VERSION ""

NS_ :

BS_:

BU_: ABS_BASE ATCM_DMSM GENERIC_GWMWakeup PBM IPMB TCU_TBS FDSM GSM TRCM GWM _delete ABS_ESC HUD IPMA CCM SASM PSCM SCCM HCM ATCM SUMA_RLM ATCM_FFSM PCU SECM VDM TBM OCS GENERIC TCCM TSTR RCM

BO_ 1073 BodyEngGateway_2_HS2: 8 GWM
 SG_ CamraFrntBttn_D_Stat : 48|1@0+ (1,0) [0|1] "SED"  IPMB
 SG_ CamraFrntBttn_D_Stat_UB : 60|1@0+ (1,0) [0|1] "SED"  IPMB
 SG_ BrkDrvMde_D_Rq_UB : 49|1@0+ (1,0) [0|1] "SED"  ABS_BASE,ABS_ESC,CCM
 SG_ BrkDrvMde_D_Rq : 63|3@0+ (1,0) [0|7] "SED"  ABS_BASE,ABS_ESC,CCM
 SG_ SteEffort_D_Rq : 52|3@0+ (1,0) [0|7] "SED"  PSCM
 SG_ SteEffort_D_Rq_UB : 40|1@0+ (1,0) [0|1] "SED"  PSCM
 SG_ AutoHoldSwtch_D_Stat_UB : 57|1@0+ (1,0) [0|1] "SED"  ABS_BASE,ABS_ESC
 SG_ AutoHoldSwtch_D_Stat : 59|2@0+ (1,0) [0|3] "SED"  ABS_BASE,ABS_ESC
 SG_ HMI_HMIMode_St_UB : 41|1@0+ (1,0) [0|1] "SED"  SASM,SCCM
 SG_ HMI_HMIMode_St : 55|3@0+ (1,0) [0|7] "SED"  SASM,SCCM
 SG_ Veh_Lock_Requestor_UB : 47|1@0+ (1,0) [0|1] "SED"  TCU_TBS,GSM
 SG_ Veh_Lock_EvNum_UB : 32|1@0+ (1,0) [0|1] "SED"  HUD,TCU_TBS,GSM
 SG_ Veh_Lock_Sub_Id_UB : 33|1@0+ (1,0) [0|1] "SED"  TCU_TBS
 SG_ Tire_Press_System_Stat_UB : 34|1@0+ (1,0) [0|1] "SED"  TCU_TBS
 SG_ Veh_Lock_Status_UB : 8|1@0+ (1,0) [0|1] "SED"  GSM,TCU_TBS
 SG_ Veh_Lock_Sub_Id : 19|4@0+ (1,0) [0|15] "SED"  TCU_TBS
 SG_ Veh_Lock_Status : 10|2@0+ (1,0) [0|3] "SED"  GSM,TCU_TBS
 SG_ Veh_Lock_Requestor : 39|5@0+ (1,0) [0|31] "SED"  TCU_TBS,GSM
 SG_ Veh_Lock_EvNum : 31|8@0+ (1,0) [0|255] "unitless"  HUD,TCU_TBS,GSM
 SG_ Tire_Press_System_Stat : 23|4@0+ (1,0) [0|15] "SED"  TCU_TBS
 SG_ DISPLAY_SPEED_OFFSET_UB : 0|1@0+ (1,0) [0|1] "SED"  IPMA
 SG_ DISPLAY_SPEED_OFFSET : 3|3@0+ (0.5,0) [0|3.5] "kph"  IPMA
 SG_ DISPLAY_SPEED_SCALING_UB : 11|1@0+ (1,0) [0|1] "SED"  IPMA
 SG_ DISPLAY_SPEED_SCALING : 15|4@0+ (0.5,100) [100|107.5] "%"  IPMA
 SG_ Foh_D_Stat : 7|3@0+ (1,0) [0|7] "SED"  SASM,SCCM
 SG_ Foh_D_Stat_UB : 4|1@0+ (1,0) [0|1] "SED"  SASM,SCCM
 SG_ SteWhlHeat_D_Rq_UB : 42|1@0+ (1,0) [0|1] "SED"  SCCM,SASM
 SG_ SteWhlHeat_D_Rq : 46|4@0+ (1,0) [0|15] "SED"  SCCM,SASM

BO_ 1092 TrackingBlocking_Data: 8 TCU_TBS
 SG_ TbsLamp_D_RqDsply : 7|2@0+ (1,0) [0|3] "SED"  GWM

BO_ 1876 TesterPhysicalReqTCU_TBS: 8 TSTR
 SG_ TesterPhysicalReqTCU : 7|64@0+ (1,0) [0|1.84467E+019] "unitless"  TCU_TBS

BO_ 1884 TesterPhysicalResTCU_TBS: 8 TCU_TBS
 SG_ TesterPhysicalResTCU : 7|64@0+ (1,0) [0|1.84467E+019] "unitless"  TSTR

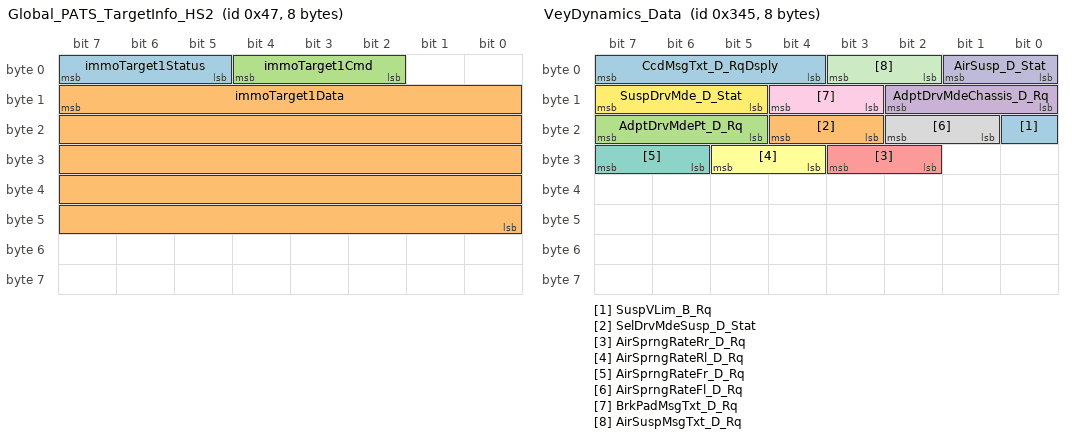
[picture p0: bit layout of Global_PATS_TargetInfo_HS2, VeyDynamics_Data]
BO_ 71 Global_PATS_TargetInfo_HS2: 8 GWM
 SG_ immoTarget1Status : 7|3@0+ (1,0) [0|7] "SED"  ABS_BASE,TCU_TBS,ABS_ESC
 SG_ immoTarget1Data : 15|40@0+ (1,0) [0|1099511627775] "Encrypted"  ABS_BASE,TCU_TBS,ABS_ESC
 SG_ immoTarget1Cmd : 4|3@0+ (1,0) [0|7] "SED"  ABS_BASE,TCU_TBS,ABS_ESC

BO_ 973 Traffic_RecognitionData: 8 IPMA
 SG_ TsrVl2PrmntMsgTxt_D_Rq : 60|2@0+ (1,0) [0|3] "SED"  GWM
 SG_ TsrVl1PrmntMsgTxt_D_Rq : 41|2@0+ (1,0) [0|3] "SED"  GWM
 SG_ TsrVl2RstrcMsgTxt2_D_Rq : 63|3@0+ (1,0) [0|7] "SED"  GWM
 SG_ TsrVl1RstrcMsgTxt2_D_Rq : 51|3@0+ (1,0) [0|7] "SED"  GWM
 SG_ TsrOvtkMsgTxt2_D_Rq : 55|4@0+ (1,0) [0|15] "SED"  GWM
 SG_ WwaWarn_B_Rq : 48|1@0+ (1,0) [0|1] "SED"  GWM
 SG_ TsrVlUnitMsgTxt_D_Rq : 43|2@0+ (1,0) [0|3] "SED"  GWM
 SG_ TsrVLim2MsgTxt_D_Rq : 39|8@0+ (1,0) [0|255] "SED"  GWM
 SG_ TsrVLim1MsgTxt_D_Rq : 31|8@0+ (1,0) [0|255] "SED"  GWM
 SG_ TsrVl2TypeMsgTxt_D_Rq : 45|2@0+ (1,0) [0|3] "SED"  GWM
 SG_ TsrVl2StatMsgTxt_D_Rq : 47|2@0+ (1,0) [0|3] "SED"  GWM
 SG_ TsrVl2RstrcMsgTxt_D_Rq : 17|2@0+ (1,0) [0|3] "SED"  GWM
 SG_ TsrVl1TypeMsgTxt_D_Rq : 19|2@0+ (1,0) [0|3] "SED"  GWM
 SG_ TsrVl1StatMsgTxt_D_Rq : 21|2@0+ (1,0) [0|3] "SED"  GWM
 SG_ TsrVl1RstrcMsgTxt_D_Rq : 23|2@0+ (1,0) [0|3] "SED"  GWM
 SG_ TsrStatMsgTxt_D_Rq : 10|3@0+ (1,0) [0|7] "SED"  GWM
 SG_ TsrOvtkTypeMsgTxt_D_Rq : 12|2@0+ (1,0) [0|3] "SED"  GWM
 SG_ TsrOvtkStatMsgTxt_D_Rq : 1|2@0+ (1,0) [0|3] "SED"  GWM
 SG_ TsrOvtkMsgTxt_D_Rq : 15|3@0+ (1,0) [0|7] "SED"  GWM
 SG_ TsrOswWarnMsgTxt_D_Rq : 3|2@0+ (1,0) [0|3] "SED"  GWM
 SG_ TsrMsgTxt_D_Rq : 7|4@0+ (1,0) [0|15] "SED"  GWM

BO_ 825 Front_Distance_Req: 8 FDSM
 SG_ WndwFrontHeat_B_Rq : 43|1@0+ (1,0) [0|1] "SED"  GWM
 SG_ FdsmTrgRight_B_Actl : 5|1@0+ (1,0) [0|1] "SED"  CCM
 SG_ FdsmTrgLeft_B_Actl : 6|1@0+ (1,0) [0|1] "SED"  CCM
 SG_ FdsmTrgDist_L_Actl : 1|10@0+ (0.0156,0) [0|15.9588] "meter"  CCM
 SG_ FdsmTrgCntr_B_Actl : 7|1@0+ (1,0) [0|1] "SED"  CCM
 SG_ LscmbbSrvcRqd_B_Rq : 44|1@0+ (1,0) [0|1] "SED"  GWM
 SG_ LscmbbPostEvnt_B_Dsply : 45|1@0+ (1,0) [0|1] "SED"  GWM
 SG_ LscmbbEngTqMn_B_Rq : 47|1@0+ (1,0) [0|1] "SED"  ABS_BASE,ABS_ESC,GWM
 SG_ LscmbbMsgTxt_D_Rq : 46|1@0+ (1,0) [0|1] "SED"  GWM
 SG_ LscmbbDeny_B_Actl : 24|1@0+ (1,0) [0|1] "SED"  ABS_BASE,ABS_ESC
 SG_ LscmbbBrkPrchg_D_Rq : 26|2@0+ (1,0) [0|3] "SED"  ABS_BASE,ABS_ESC
 SG_ LscmbbBrkDecel_No_Cs : 39|8@0+ (1,0) [0|255] "Unitless"  ABS_BASE,ABS_ESC
 SG_ LscmbbBrkDecel_No_Cnt : 30|4@0+ (1,0) [0|15] "Unitless"  ABS_BASE,ABS_ESC
 SG_ LscmbbBrkDecel_B_Enbl : 31|1@0+ (1,0) [0|1] "SED"  ABS_BASE,ABS_ESC
 SG_ LscmbbBrkDecel_A_Rq : 23|8@0+ (0.05,-12.75) [-12.75|12.75] "m/s^2"  ABS_BASE,ABS_ESC
 SG_ LscmbbBlck_B_Actl : 2|1@0+ (1,0) [0|1] "SED"  CCM,GWM
 SG_ LscmbbBaSens_D_Rq : 4|2@0+ (1,0) [0|3] "SED"  ABS_BASE,ABS_ESC

BO_ 837 VeyDynamics_Data: 8 VDM
 SG_ SuspVLim_B_Rq : 16|1@0+ (1,0) [0|1] "SED"  GWM
 SG_ SelDrvMdeSusp_D_Stat : 20|2@0+ (1,0) [0|3] "SED"  ABS_BASE,ABS_ESC
 SG_ AdptDrvMdePt_D_Rq : 23|3@0+ (1,0) [0|7] "SED"  ABS_BASE,ABS_ESC
 SG_ AdptDrvMdeChassis_D_Rq : 10|3@0+ (1,0) [0|7] "SED"  ABS_BASE,ABS_ESC
 SG_ AirSprngRateRr_D_Rq : 27|2@0+ (1,0) [0|3] "SED"  SUMA_RLM,GENERIC
 SG_ AirSprngRateRl_D_Rq : 29|2@0+ (1,0) [0|3] "SED"  SUMA_RLM,GENERIC
 SG_ AirSprngRateFr_D_Rq : 31|2@0+ (1,0) [0|3] "SED"  SUMA_RLM,GENERIC
 SG_ AirSprngRateFl_D_Rq : 18|2@0+ (1,0) [0|3] "SED"  SUMA_RLM,GENERIC
 SG_ BrkPadMsgTxt_D_Rq : 12|2@0+ (1,0) [0|3] "SED"  GWM
 SG_ AirSusp_D_Stat : 1|2@0+ (1,0) [0|3] "SED"  GWM
 SG_ AirSuspMsgTxt_D_Rq : 3|2@0+ (1,0) [0|3] "SED"  GWM
 SG_ SuspDrvMde_D_Stat : 15|3@0+ (1,0) [0|7] "SED"  ABS_BASE,GWM,ABS_ESC
 SG_ CcdMsgTxt_D_RqDsply : 7|4@0+ (1,0) [0|15] "SED"  ABS_BASE,SASM,GWM,PSCM,ABS_ESC

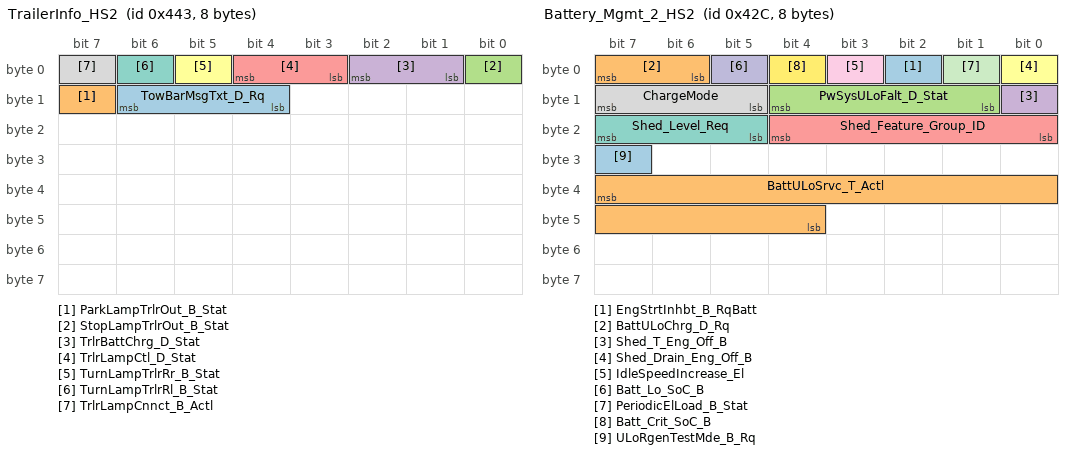
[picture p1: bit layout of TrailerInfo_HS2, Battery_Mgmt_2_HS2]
BO_ 1091 TrailerInfo_HS2: 8 GWM
 SG_ TowBarMsgTxt_D_Rq : 14|3@0+ (1,0) [0|7] "SED"  GENERIC
 SG_ ParkLampTrlrOut_B_Stat : 15|1@0+ (1,0) [0|1] "SED"  GENERIC
 SG_ StopLampTrlrOut_B_Stat : 0|1@0+ (1,0) [0|1] "SED"  GENERIC
 SG_ TrlrBattChrg_D_Stat : 2|2@0+ (1,0) [0|3] "SED"  GENERIC
 SG_ TrlrLampCtl_D_Stat : 4|2@0+ (1,0) [0|3] "SED"  GENERIC
 SG_ TurnLampTrlrRr_B_Stat : 5|1@0+ (1,0) [0|1] "SED"  GENERIC
 SG_ TurnLampTrlrRl_B_Stat : 6|1@0+ (1,0) [0|1] "SED"  GENERIC
 SG_ TrlrLampCnnct_B_Actl : 7|1@0+ (1,0) [0|1] "SED"  ABS_BASE,IPMB,PSCM,IPMA,ABS_ESC,VDM,SCCM

BO_ 1068 Battery_Mgmt_2_HS2: 8 GWM
 SG_ EngStrtInhbt_B_RqBatt : 2|1@0+ (1,0) [0|1] "SED"  GENERIC
 SG_ BattULoChrg_D_Rq : 7|2@0+ (1,0) [0|3] "SED"  GENERIC
 SG_ PwSysULoFalt_D_Stat : 12|4@0+ (1,0) [0|15] "SED"  ABS_BASE,ABS_ESC,PSCM
 SG_ Shed_T_Eng_Off_B : 8|1@0+ (1,0) [0|1] "SED"  SCCM
 SG_ Shed_Feature_Group_ID : 20|5@0+ (1,0) [0|31] "SED"  SCCM
 SG_ Shed_Drain_Eng_Off_B : 0|1@0+ (1,0) [0|1] "SED"  SCCM
 SG_ Shed_Level_Req : 23|3@0+ (1,0) [0|7] "SED"  ABS_BASE,GSM,TRCM,ABS_ESC,SCCM
 SG_ ChargeMode : 15|3@0+ (1,0) [0|7] "SED"  GENERIC
 SG_ IdleSpeedIncrease_El : 3|1@0+ (1,0) [0|1] "SED"  GENERIC
 SG_ Batt_Lo_SoC_B : 5|1@0+ (1,0) [0|1] "SED"  GENERIC
 SG_ PeriodicElLoad_B_Stat : 1|1@0+ (1,0) [0|1] "SED"  GENERIC
 SG_ Batt_Crit_SoC_B : 4|1@0+ (1,0) [0|1] "SED"  GSM,TRCM
 SG_ ULoRgenTestMde_B_Rq : 31|1@0+ (1,0) [0|1] "SED"  GENERIC
 SG_ BattULoSrvc_T_Actl : 39|12@0+ (1,0) [0|4095] "days"  GENERIC

BO_ 611 Driveline_Data_1: 8 TCCM
 SG_ AwdTerrMdeChng_D_Rdy : 58|3@0+ (1,0) [0|7] "SED"  ATCM
 SG_ AwdTerrMde_D_Actl : 50|3@0+ (1,0) [0|7] "SED"  ATCM
 SG_ AwdSys_D_Stat : 27|2@0+ (1,0) [0|3] "SED"  GWM
 SG_ SelDrvMdeAwd_D_Stat : 33|2@0+ (1,0) [0|3] "SED"  ABS_BASE,ABS_ESC,GWM
 SG_ AwdStat_D_RqDsply : 63|5@0+ (1,0) [0|31] "SED"  ABS_BASE,ABS_ESC,GWM
 SG_ AwdLck_D_Stat : 31|4@0+ (1,0) [0|15] "SED"  ABS_BASE,GWM,ABS_ESC
 SG_ AwdSrvcRqd_B_Rq : 0|1@0+ (1,0) [0|1] "SED"  ABS_BASE,ABS_ESC,GWM,RCM
 SG_ AwdDrvMde_D_Stat : 38|3@0+ (1,0) [0|7] "SED"  PSCM,GWM
 SG_ NtrlTowAvail_B_Stat : 4|1@0+ (1,0) [0|1] "SED"  GWM
 SG_ AwdLck_Tq_Rq : 15|12@0+ (1,0) [0|4093] "Nm"  ABS_BASE,ABS_ESC,GWM
 SG_ TrnAout_Tq_RqMx : 47|13@0+ (1,-1250) [-1250|6941] "Nm"  GWM
 SG_ AwdOffRoadMode_D_Stats : 25|2@0+ (1,0) [0|3] "SED"  ABS_BASE,ABS_ESC,GWM
 SG_ AwdLoLamp_D_RqDsply : 35|2@0+ (1,0) [0|3] "SED"  ATCM_FFSM,ATCM_DMSM,GWM
 SG_ AwdHiLamp_D_RqDsply : 19|2@0+ (1,0) [0|3] "SED"  ATCM_FFSM,ATCM_DMSM,GWM
 SG_ AwdAutoLamp_D_RqDsply : 17|2@0+ (1,0) [0|3] "SED"  ATCM_FFSM,ATCM_DMSM,GWM
 SG_ Awd2wdLamp_D_RqDsply : 2|2@0+ (1,0) [0|3] "SED"  ATCM_FFSM,ATCM_DMSM,GWM
 SG_ AwdRnge_D_Actl : 7|3@0+ (1,0) [0|7] "SED"  ABS_BASE,ATCM,PSCM,ABS_ESC,GWM

BO_ 395 HeadUpDisplayReq_HS2: 8 GWM
 SG_ HudShifPoint_N_Rq : 29|6@0+ (100,2000) [2000|8300] "rpm"  HUD
 SG_ HudMde_D_Rq : 38|3@0+ (1,0) [0|7] "SED"  HUD
 SG_ HudLedMde_D_Rq : 31|2@0+ (1,0) [0|3] "SED"  HUD
 SG_ HudLedIntns_Pc_Rq : 22|7@0+ (1,0) [0|127] "percent"  HUD
 SG_ HudLed9On_B_Rq : 15|1@0+ (1,0) [0|1] "SED"  HUD
 SG_ HudLed8On_B_Rq : 0|1@0+ (1,0) [0|1] "SED"  HUD
 SG_ HudLed7On_B_Rq : 1|1@0+ (1,0) [0|1] "SED"  HUD
 SG_ HudLed6On_B_Rq : 2|1@0+ (1,0) [0|1] "SED"  HUD
 SG_ HudLed5On_B_Rq : 3|1@0+ (1,0) [0|1] "SED"  HUD
 SG_ HudLed4On_B_Rq : 4|1@0+ (1,0) [0|1] "SED"  HUD
 SG_ HudLed3On_B_Rq : 5|1@0+ (1,0) [0|1] "SED"  HUD
 SG_ HudLed2On_B_Rq : 6|1@0+ (1,0) [0|1] "SED"  HUD
 SG_ HudLed1On_B_Rq : 7|1@0+ (1,0) [0|1] "SED"  HUD
 SG_ HudLed18On_B_Rq : 39|1@0+ (1,0) [0|1] "SED"  HUD
 SG_ HudLed17On_B_Rq : 23|1@0+ (1,0) [0|1] "SED"  HUD
 SG_ HudLed16On_B_Rq : 8|1@0+ (1,0) [0|1] "SED"  HUD
 SG_ HudLed15On_B_Rq : 9|1@0+ (1,0) [0|1] "SED"  HUD
 SG_ HudLed14On_B_Rq : 10|1@0+ (1,0) [0|1] "SED"  HUD
 SG_ HudLed13On_B_Rq : 11|1@0+ (1,0) [0|1] "SED"  HUD
 SG_ HudLed12On_B_Rq : 12|1@0+ (1,0) [0|1] "SED"  HUD
 SG_ HudLed11On_B_Rq : 13|1@0+ (1,0) [0|1] "SED"  HUD
 SG_ HudLed10On_B_Rq : 14|1@0+ (1,0) [0|1] "SED"  HUD

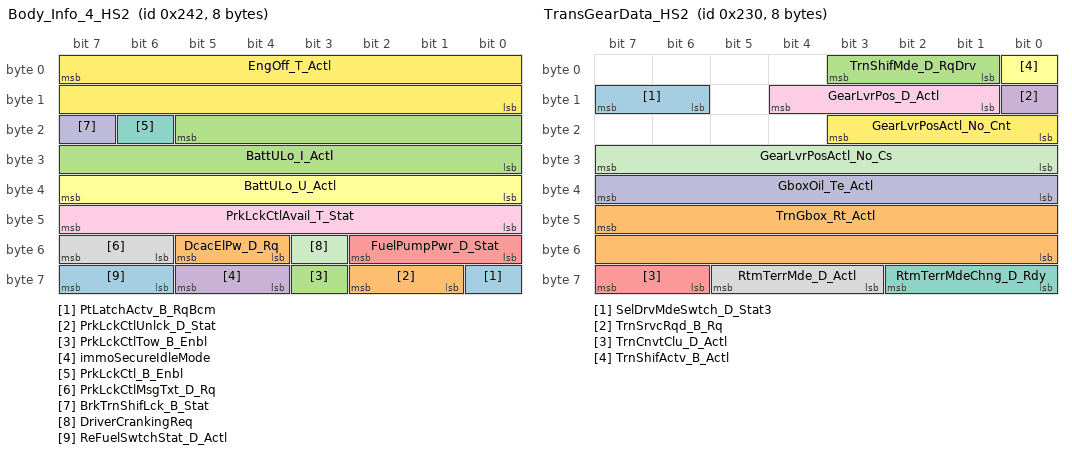
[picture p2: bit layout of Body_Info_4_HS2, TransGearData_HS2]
BO_ 578 Body_Info_4_HS2: 8 GWM
 SG_ PtLatchActv_B_RqBcm : 56|1@0+ (1,0) [0|1] "SED"  GENERIC
 SG_ PrkLckCtlUnlck_D_Stat : 58|2@0+ (1,0) [0|3] "SED"  GENERIC
 SG_ PrkLckCtlTow_B_Enbl : 59|1@0+ (1,0) [0|1] "SED"  GENERIC
 SG_ immoSecureIdleMode : 61|2@0+ (1,0) [0|3] "SED"  GSM
 SG_ FuelPumpPwr_D_Stat : 50|3@0+ (1,0) [0|7] "SED"  GENERIC
 SG_ BattULo_U_Actl : 39|8@0+ (0.0625,0) [0|15.875] "volt"  ABS_BASE,PSCM,IPMA,ABS_ESC
 SG_ PrkLckCtl_B_Enbl : 22|1@0+ (1,0) [0|1] "SED"  GSM,TRCM
 SG_ PrkLckCtlMsgTxt_D_Rq : 55|2@0+ (1,0) [0|3] "SED"  GENERIC,TRCM
 SG_ PrkLckCtlAvail_T_Stat : 47|8@0+ (1,0) [0|255] "second"  GENERIC
 SG_ BrkTrnShifLck_B_Stat : 23|1@0+ (1,0) [0|1] "SED"  GSM,TRCM
 SG_ DriverCrankingReq : 51|1@0+ (1,0) [0|1] "SED"  GSM,TRCM
 SG_ EngOff_T_Actl : 7|16@0+ (1,0) [0|65534] "second^0.5"  ABS_BASE,IPMA,TCCM,ABS_ESC,ATCM,FDSM
 SG_ ReFuelSwtchStat_D_Actl : 63|2@0+ (1,0) [0|3] "SED"  GENERIC
 SG_ DcacElPw_D_Rq : 53|2@0+ (1,0) [0|3] "SED"  GENERIC
 SG_ BattULo_I_Actl : 21|14@0+ (0.0625,-512) [-512|511.875] "ampere"  GENERIC

BO_ 560 TransGearData_HS2: 8 GWM
 SG_ SelDrvMdeSwtch_D_Stat3 : 15|2@0+ (1,0) [0|3] "SED"  ABS_BASE,ABS_ESC
 SG_ TrnGbox_Rt_Actl : 47|16@0+ (0.001,0) [0|65.533] "Unitless"  ABS_BASE,ABS_ESC
 SG_ TrnShifMde_D_RqDrv : 3|3@0+ (1,0) [0|7] "SED"  ABS_BASE,ABS_ESC,GENERIC
 SG_ TrnSrvcRqd_B_Rq : 8|1@0+ (1,0) [0|1] "SED"  RCM
 SG_ TrnCnvtClu_D_Actl : 63|2@0+ (1,0) [0|3] "SED"  ABS_BASE,ABS_ESC
 SG_ TrnShifActv_B_Actl : 0|1@0+ (1,0) [0|1] "SED"  ABS_BASE,ABS_ESC
 SG_ RtmTerrMdeChng_D_Rdy : 58|3@0+ (1,0) [0|7] "SED"  ATCM
 SG_ RtmTerrMde_D_Actl : 61|3@0+ (1,0) [0|7] "SED"  ATCM
 SG_ GearLvrPos_D_Actl : 12|4@0+ (1,0) [0|15] "SED"  ABS_BASE,SASM,PBM,IPMA,IPMB,HCM,VDM,PSCM,TRCM,SCCM,RCM,GSM,CCM,ABS_ESC,TCCM
 SG_ GboxOil_Te_Actl : 39|8@0+ (1,-60) [-60|193] "degC"  TCCM,GENERIC
 SG_ GearLvrPosActl_No_Cs : 31|8@0+ (1,0) [0|255] "Unitless"  GENERIC
 SG_ GearLvrPosActl_No_Cnt : 19|4@0+ (1,0) [0|15] "Unitless"  GENERIC

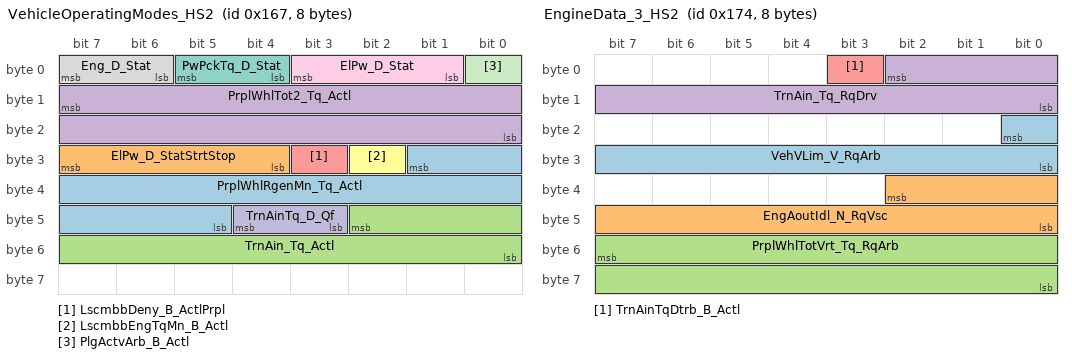
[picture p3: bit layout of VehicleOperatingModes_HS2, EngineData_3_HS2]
BO_ 359 VehicleOperatingModes_HS2: 8 GWM
 SG_ PrplWhlRgenMn_Tq_Actl : 25|13@0+ (4,-16380) [-16380|16380] "Nm"  ABS_BASE,ABS_ESC
 SG_ ElPw_D_StatStrtStop : 31|4@0+ (1,0) [0|15] "SED"  GSM,TRCM,SCCM,SASM,PSCM
 SG_ TrnAin_Tq_Actl : 42|11@0+ (1,-500) [-500|1547] "Nm"  ABS_BASE,ABS_ESC
 SG_ PrplWhlTot2_Tq_Actl : 15|16@0+ (4,-131072) [-131072|131060] "Nm"  ABS_BASE,PBM,RCM,ABS_ESC,PSCM,TCCM,VDM
 SG_ LscmbbDeny_B_ActlPrpl : 27|1@0+ (1,0) [0|1] "SED"  ABS_BASE,ABS_ESC,FDSM
 SG_ LscmbbEngTqMn_B_Actl : 26|1@0+ (1,0) [0|1] "SED"  ABS_BASE,ABS_ESC,FDSM
 SG_ PwPckTq_D_Stat : 5|2@0+ (1,0) [0|3] "SED"  ABS_BASE,IPMB,PBM,HCM,SASM,TCU_TBS,VDM,TRCM,TCCM,TBM,SCCM,PSCM,OCS,IPMA,HUD,GSM,FDSM,CCM,ABS_ESC
 SG_ Eng_D_Stat : 7|2@0+ (1,0) [0|3] "SED"  ABS_BASE,VDM,PBM,ABS_ESC
 SG_ ElPw_D_Stat : 3|3@0+ (1,0) [0|7] "SED"  ABS_BASE,PBM,HCM,SASM,TCU_TBS,IPMA,PSCM,ABS_ESC,ATCM,CCM,FDSM,GSM,HUD,OCS,SCCM,TBM,TCCM,TRCM,VDM
 SG_ TrnAinTq_D_Qf : 44|2@0+ (1,0) [0|3] "SED"  ABS_BASE,ABS_ESC
 SG_ PlgActvArb_B_Actl : 0|1@0+ (1,0) [0|1] "SED"  GENERIC

BO_ 372 EngineData_3_HS2: 8 GWM
 SG_ VehVLim_V_RqArb : 16|9@0+ (0.5,0) [0|255.5] "kph"  GENERIC
 SG_ EngAoutIdl_N_RqVsc : 34|11@0+ (2,0) [0|4094] "rpm"  ABS_BASE,ABS_ESC
 SG_ PrplWhlTotVrt_Tq_RqArb : 55|16@0+ (4,-131072) [-131072|131068] "Nm"  GENERIC
 SG_ TrnAin_Tq_RqDrv : 2|11@0+ (1,-500) [-500|1547] "Nm"  GENERIC
 SG_ TrnAinTqDtrb_B_Actl : 3|1@0+ (1,0) [0|1] "SED"  GENERIC

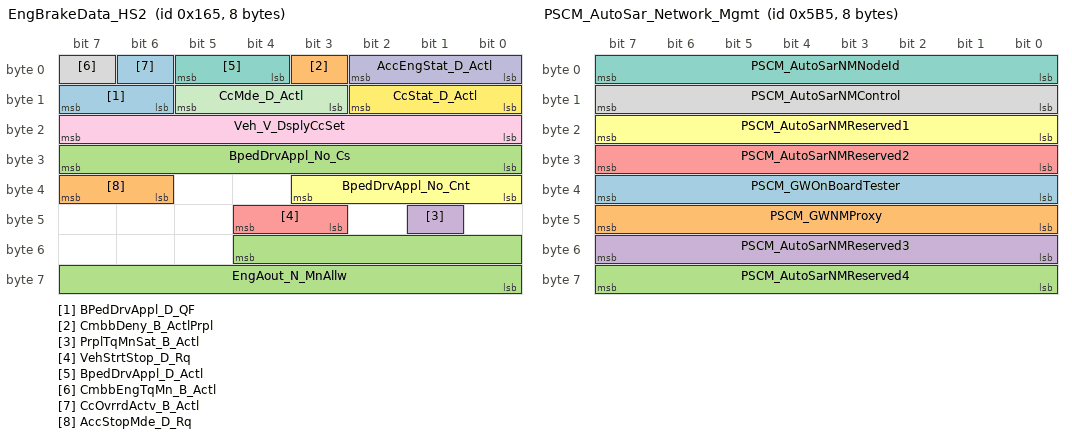
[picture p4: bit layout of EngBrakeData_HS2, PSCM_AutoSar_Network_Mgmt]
BO_ 357 EngBrakeData_HS2: 8 GWM
 SG_ BPedDrvAppl_D_QF : 15|2@0+ (1,0) [0|3] "SED"  ABS_BASE,OCS,VDM,PBM,IPMA,PSCM,GSM,RCM,ABS_ESC,CCM,FDSM
 SG_ CmbbDeny_B_ActlPrpl : 3|1@0+ (1,0) [0|1] "SED"  IPMA,CCM
 SG_ BpedDrvAppl_No_Cs : 31|8@0+ (1,0) [0|255] "Unitless"  GENERIC
 SG_ PrplTqMnSat_B_Actl : 41|1@0+ (1,0) [0|1] "SED"  IPMA,CCM
 SG_ VehStrtStop_D_Rq : 44|2@0+ (1,0) [0|3] "SED"  GENERIC
 SG_ BpedDrvAppl_No_Cnt : 35|4@0+ (1,0) [0|15] "Unitless"  GENERIC
 SG_ BpedDrvAppl_D_Actl : 5|2@0+ (1,0) [0|3] "SED"  ABS_BASE,VDM,OCS,PBM,TBM,PSCM,TCCM,ABS_ESC,CCM,GSM,RCM,TRCM,FDSM,IPMA
 SG_ CmbbEngTqMn_B_Actl : 7|1@0+ (1,0) [0|1] "SED"  IPMA,CCM
 SG_ Veh_V_DsplyCcSet : 23|8@0+ (1,0) [0|253] "Unitless"  GENERIC
 SG_ AccEngStat_D_Actl : 2|3@0+ (1,0) [0|7] "SED"  IPMA,CCM
 SG_ CcMde_D_Actl : 13|3@0+ (1,0) [0|7] "SED"  VDM,ABS_BASE,ABS_ESC
 SG_ CcStat_D_Actl : 10|3@0+ (1,0) [0|7] "SED"  ABS_BASE,IPMA,TCCM,ABS_ESC,CCM,OCS,RCM
 SG_ CcOvrrdActv_B_Actl : 6|1@0+ (1,0) [0|1] "SED"  VDM,ABS_BASE,IPMA,TCCM,ABS_ESC,CCM,RCM
 SG_ AccStopMde_D_Rq : 39|2@0+ (1,0) [0|3] "SED"  ABS_BASE,IPMA,ABS_ESC,CCM
 SG_ EngAout_N_MnAllw : 52|13@0+ (2,0) [0|16382] "rpm"  GENERIC

BO_ 1461 PSCM_AutoSar_Network_Mgmt: 8 PSCM
 SG_ PSCM_GWOnBoardTester : 39|8@0+ (1,0) [0|255] "unitless"  ABS_BASE,GWM,TRCM,TCCM,TBM,SCCM,SASM,PBM,GSM,ABS_ESC
 SG_ PSCM_GWNMProxy : 47|8@0+ (1,0) [0|255] "unitless"  ABS_BASE,GWM,TRCM,TCCM,TBM,SCCM,SASM,PBM,GSM,ABS_ESC
 SG_ PSCM_AutoSarNMReserved4 : 63|8@0+ (1,0) [0|255] "unitless"  ABS_BASE,GWM,TRCM,TCCM,TBM,SCCM,SASM,PBM,GSM,ABS_ESC
 SG_ PSCM_AutoSarNMReserved3 : 55|8@0+ (1,0) [0|255] "unitless"  ABS_BASE,GWM,TRCM,TCCM,TBM,SCCM,SASM,PBM,GSM,ABS_ESC
 SG_ PSCM_AutoSarNMReserved2 : 31|8@0+ (1,0) [0|255] "unitless"  ABS_BASE,GWM,TRCM,TCCM,TBM,SCCM,SASM,PBM,GSM,ABS_ESC
 SG_ PSCM_AutoSarNMReserved1 : 23|8@0+ (1,0) [0|255] "unitless"  ABS_BASE,GWM,TRCM,TCCM,TBM,SCCM,SASM,PBM,GSM,ABS_ESC
 SG_ PSCM_AutoSarNMNodeId : 7|8@0+ (1,0) [0|255] "unitless"  ABS_BASE,GWM,TRCM,TCCM,TBM,SCCM,SASM,PBM,GSM,ABS_ESC
 SG_ PSCM_AutoSarNMControl : 15|8@0+ (1,0) [0|255] "unitless"  ABS_BASE,GWM,TRCM,TCCM,TBM,SCCM,SASM,PBM,GSM,ABS_ESC

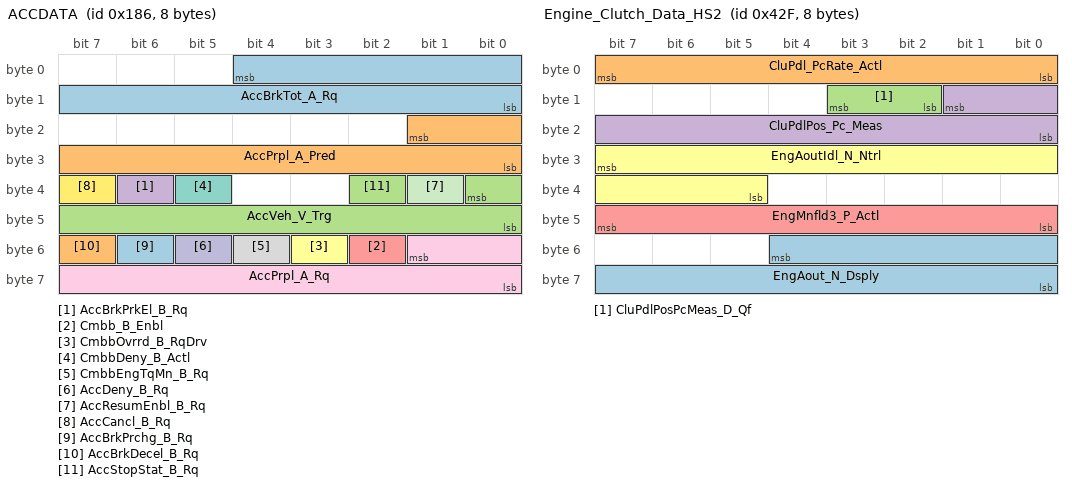
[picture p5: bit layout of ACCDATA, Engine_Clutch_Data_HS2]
BO_ 390 ACCDATA: 8 IPMA
 SG_ AccBrkTot_A_Rq : 4|13@0+ (0.0039,-20) [-20|11.9449] "m/s^2"  ABS_BASE,ABS_ESC,GWM
 SG_ AccPrpl_A_Pred : 17|10@0+ (0.01,-5) [-5|5.23] "m/s^2"  GWM
 SG_ AccVeh_V_Trg : 32|9@0+ (0.5,0) [0|255.5] "kph"  GWM
 SG_ AccBrkPrkEl_B_Rq : 38|1@0+ (1,0) [0|1] "SED"  ABS_BASE,ABS_ESC,GWM
 SG_ Cmbb_B_Enbl : 50|1@0+ (1,0) [0|1] "SED"  RCM,GWM
 SG_ CmbbOvrrd_B_RqDrv : 51|1@0+ (1,0) [0|1] "SED"  RCM,GWM
 SG_ CmbbDeny_B_Actl : 37|1@0+ (1,0) [0|1] "SED"  ABS_BASE,ABS_ESC,RCM,GWM
 SG_ CmbbEngTqMn_B_Rq : 52|1@0+ (1,0) [0|1] "SED"  GWM
 SG_ AccPrpl_A_Rq : 49|10@0+ (0.01,-5) [-5|5.23] "m/s^2"  GWM
 SG_ AccDeny_B_Rq : 53|1@0+ (1,0) [0|1] "SED"  GWM
 SG_ AccResumEnbl_B_Rq : 33|1@0+ (1,0) [0|1] "SED"  GWM
 SG_ AccCancl_B_Rq : 39|1@0+ (1,0) [0|1] "SED"  ABS_BASE,GWM,ABS_ESC
 SG_ AccBrkPrchg_B_Rq : 54|1@0+ (1,0) [0|1] "SED"  ABS_BASE,ABS_ESC,GWM
 SG_ AccBrkDecel_B_Rq : 55|1@0+ (1,0) [0|1] "SED"  ABS_BASE,GWM,ABS_ESC
 SG_ AccStopStat_B_Rq : 34|1@0+ (1,0) [0|1] "SED"  ABS_BASE,ABS_ESC,GWM

BO_ 1947 TesterPhysicalResFDSM: 8 FDSM
 SG_ TesterPhysicalResFDSM : 7|64@0+ (1,0) [0|1.84467E+019] "unitless"  TSTR

BO_ 1939 TesterPhysicalReqFDSM: 8 TSTR
 SG_ TesterPhysicalReqFDSM : 7|64@0+ (1,0) [0|1.84467E+019] "unitless"  FDSM

BO_ 1071 Engine_Clutch_Data_HS2: 8 GWM
 SG_ EngAout_N_Dsply : 52|13@0+ (2,0) [0|16382] "rpm"  GENERIC
 SG_ CluPdl_PcRate_Actl : 7|8@0+ (0.04,-5) [-5|5.2] "%/ms"  ABS_BASE,ABS_ESC
 SG_ CluPdlPosPcMeas_D_Qf : 11|2@0+ (1,0) [0|3] "SED"  HCM,ABS_BASE,TCCM,ABS_ESC
 SG_ CluPdlPos_Pc_Meas : 9|10@0+ (0.1,0) [0|102.3] "%"  HCM,ABS_BASE,TCCM,ABS_ESC
 SG_ EngMnfld3_P_Actl : 47|8@0+ (10,0) [0|2530] "milibar"  ABS_BASE,ABS_ESC
 SG_ EngAoutIdl_N_Ntrl : 31|11@0+ (2,0) [0|4094] "rpm"  ABS_BASE,ABS_ESC

BO_ 1072 Cluster_Info1_HS2: 8 GWM
 SG_ HdcOn_B_Rq_UB : 55|1@0+ (1,0) [0|1] "SED"  ABS_ESC,ABS_BASE
 SG_ TrlrAidCancl_B_Rq_UB : 56|1@0+ (1,0) [0|1] "SED"  PSCM,IPMB
 SG_ TrlrAidCancl_B_Rq : 57|1@0+ (1,0) [0|1] "SED"  PSCM,IPMB
 SG_ HdcOn_B_Rq : 39|1@0+ (1,0) [0|1] "SED"  ABS_ESC,ABS_BASE
 SG_ HsaMde_D_Rq : 51|2@0+ (1,0) [0|3] "SED"  ABS_BASE,ABS_ESC
 SG_ HsaMde_D_Rq_UB : 49|1@0+ (1,0) [0|1] "SED"  ABS_BASE,ABS_ESC
 SG_ LscmbbStat_B_Actl : 53|1@0+ (1,0) [0|1] "SED"  FDSM
 SG_ LscmbbStat_B_Actl_UB : 52|1@0+ (1,0) [0|1] "SED"  FDSM
 SG_ Outside_Air_Temp_Stat_UB : 3|1@0+ (1,0) [0|1] "SED"  PSCM,IPMA,CCM
 SG_ Outside_Air_Temp_Stat : 47|8@0+ (0.5,-40) [-40|86.5] "Degrees C"  PSCM,IPMA,CCM
 SG_ BulbChkActv_B_Stat_UB : 5|1@0+ (1,0) [0|1] "SED"  HUD
 SG_ BulbChkActv_B_Stat : 6|1@0+ (1,0) [0|1] "SED"  HUD
 SG_ Fda_B_Stat_UB : 4|1@0+ (1,0) [0|1] "SED"  CCM,IPMA
 SG_ AccEnbl_B_RqDrv_UB : 2|1@0+ (1,0) [0|1] "SED"  IPMA,CCM
 SG_ AccDeny_B_RqIpc_UB : 1|1@0+ (1,0) [0|1] "SED"  IPMA,CCM
 SG_ OdometerMasterValue_UB : 0|1@0+ (1,0) [0|1] "SED"  ABS_BASE,TCU_TBS,PBM,FDSM,SASM,PSCM,IPMA,VDM,ABS_ESC
 SG_ OdometerMasterValue : 15|24@0+ (1,0) [0|16777214] "km"  ABS_BASE,RCM,TCU_TBS,PBM,FDSM,SASM,IPMA,VDM,PSCM,ABS_ESC
 SG_ Fda_B_Stat : 36|1@0+ (1,0) [0|1] "SED"  CCM,IPMA
 SG_ AccDeny_B_RqIpc : 7|1@0+ (1,0) [0|1] "SED"  CCM,IPMA
 SG_ AccEnbl_B_RqDrv : 35|1@0+ (1,0) [0|1] "SED"  IPMA,CCM
 SG_ DrvSlipCtlMde_D_Rq_UB : 38|1@0+ (1,0) [0|1] "SED"  ABS_BASE,ABS_ESC
 SG_ DrvSlipCtlMde_D_Rq : 33|2@0+ (1,0) [0|3] "SED"  ABS_BASE,ABS_ESC
 SG_ DrvSlipCtlMde_B_Rq_UB : 37|1@0+ (1,0) [0|1] "SED"  ABS_BASE,ABS_ESC
 SG_ DrvSlipCtlMde_B_Rq : 34|1@0+ (1,0) [0|1] "SED"  ABS_BASE,ABS_ESC
 SG_ ePRNDL_MODE_UB : 48|1@0+ (1,0) [0|1] "SED"  GSM,TRCM
 SG_ ePRNDL_MODE : 54|1@0+ (1,0) [0|1] "SED"  GSM,TRCM
 SG_ TrlrBrkMde_D_Rq : 63|1@0+ (1,0) [0|1] "SED"  TBM
 SG_ TRLR_SWAY_CONFIG_CMD : 62|1@0+ (1,0) [0|1] "SED"  ABS_BASE,ABS_ESC
 SG_ TRAILER_BRAKE_CONFIG : 61|1@0+ (1,0) [0|1] "SED"  TBM
 SG_ TrlrBrkMde_D_Rq_UB : 60|1@0+ (1,0) [0|1] "SED"  TBM
 SG_ TRLR_SWAY_CONFIG_CMD_UB : 59|1@0+ (1,0) [0|1] "SED"  ABS_BASE,ABS_ESC
 SG_ TRAILER_BRAKE_CONFIG_UB : 58|1@0+ (1,0) [0|1] "SED"  TBM

BO_ 1058 PowertrainData_HS2: 8 GWM
 SG_ TqmTerrMdeChng_D_Rdy_UB : 33|1@0+ (1,0) [0|1] "SED"  ATCM
 SG_ TqmTerrMde_D_Actl_UB : 32|1@0+ (1,0) [0|1] "SED"  ATCM
 SG_ TqmTerrMdeChng_D_Rdy : 63|3@0+ (1,0) [0|7] "SED"  ATCM
 SG_ TqmTerrMde_D_Actl : 60|3@0+ (1,0) [0|7] "SED"  ATCM
 SG_ BattTracWarnLamp_B_Rq_UB : 48|1@0+ (1,0) [0|1] "SED"  GENERIC
 SG_ BattTracWarnLamp_B_Rq : 43|1@0+ (1,0) [0|1] "SED"  RCM
 SG_ BattTracSrvcRqd_B_Rq_UB : 44|1@0+ (1,0) [0|1] "SED"  GENERIC
 SG_ BattTracSrvcRqd_B_Rq : 45|1@0+ (1,0) [0|1] "SED"  RCM
 SG_ SeatBlLoPsgr_Pc_Actl_UB : 42|1@0+ (1,0) [0|1] "SED"  OCS
 SG_ SeatBlLoPsgr_Pc_Actl : 55|7@0+ (1,0) [0|126] "Percent"  OCS
 SG_ WndwFrontHeat_B_Stat_UB : 41|1@0+ (1,0) [0|1] "SED"  IPMA,FDSM
 SG_ WndwFrontHeat_B_Stat : 40|1@0+ (1,0) [0|1] "SED"  IPMA,FDSM
 SG_ HILL_DESC_SW_UB : 46|1@0+ (1,0) [0|1] "SED"  ABS_BASE,ABS_ESC
 SG_ HILL_DESC_SW : 47|1@0+ (1,0) [0|1] "SED"  ABS_BASE,ABS_ESC
 SG_ EngClntTe_D_Qf : 36|2@0+ (1,0) [0|3] "SED"  ABS_BASE,VDM,ABS_ESC
 SG_ EngClnt_Te_Actl_UB : 37|1@0+ (1,0) [0|1] "SED"  ABS_BASE,VDM,ABS_ESC
 SG_ EngClnt_Te_Actl : 31|8@0+ (1,-60) [-60|195] "degC"  ABS_BASE,VDM,ABS_ESC,GSM,TRCM
 SG_ TrnTotTq_Rt_Est_UB : 38|1@0+ (1,0) [0|1] "SED"  ABS_BASE,ABS_ESC
 SG_ TrnTotLss_Tq_Est_UB : 39|1@0+ (1,0) [0|1] "SED"  ABS_BASE,ABS_ESC
 SG_ TrnTotTq_Rt_Est : 15|16@0+ (0.001,0) [0|65.533] "Unitless"  ABS_BASE,ABS_ESC
 SG_ TrnTotLss_Tq_Est : 7|8@0+ (0.5,0) [0|126.5] "Nm"  ABS_BASE,ABS_ESC
 SG_ DrvSlipCtlMde_B_Rq2_UB : 57|1@0+ (1,0) [0|1] "SED"  ABS_BASE,ABS_ESC
 SG_ DrvSlipCtlMde_B_Rq2 : 34|1@0+ (1,0) [0|1] "SED"  ABS_BASE,ABS_ESC

BO_TX_BU_ 837 : SASM,VDM;
BO_TX_BU_ 390 : GENERIC_GWMWakeup,CCM,IPMA;
CM_ SG_ 1073 HMI_HMIMode_St "Object ACU System Master.HMIMode
OR
Object NAV System Master.HMIMode

Refer Method HMIAudioMode in the SPSS";
CM_ SG_ 1073 Foh_D_Stat "Signal not transmitted on vehicles that do not have the Fuel operated heater feature.";
CM_ BO_ 71 "Provide target function info. to control function of PATS";
CM_ BO_ 611 "Used on Applications with 4x4 supplied by Motorola.";
CM_ SG_ 611 AwdStat_D_RqDsply "Signal not transmitted on programs that do not have AWD.";
CM_ SG_ 611 AwdSrvcRqd_B_Rq "Signal not transmitted on programs that do not have AWD.";
CM_ SG_ 611 AwdLck_Tq_Rq "Signal not transmitted on programs that do not have AWD.";
CM_ SG_ 560 SelDrvMdeSwtch_D_Stat3 "ECM_HEV does not support or transmit signal SelDrvMdeSwtch_D_Stat3.";
CM_ SG_ 560 TrnGbox_Rt_Actl "Signal not transmitted on gas and HEV variants.";
CM_ SG_ 560 TrnSrvcRqd_B_Rq "Signal not transmitted on Diesel and HEV variants.";
CM_ SG_ 560 TrnCnvtClu_D_Actl "Signal not transmitted on gas and HEV variants.";
CM_ SG_ 560 TrnShifActv_B_Actl "Signal not transmitted on HEV variants.";
CM_ SG_ 560 GboxOil_Te_Actl "Signal not transmitted on HEV variants.";
CM_ SG_ 560 GearLvrPosActl_No_Cs "Signal not transmitted on gas and HEV variants.";
CM_ SG_ 560 GearLvrPosActl_No_Cnt "Signal not transmitted on gas and HEV variants.";
CM_ SG_ 359 TrnAin_Tq_Actl "Signal not transmitted on HEV variances.";
CM_ SG_ 359 TrnAinTq_D_Qf "Signal not transmitted on HEV variances.";
CM_ SG_ 359 PlgActvArb_B_Actl "Signal not transmitted on gas, diesel and HEV variants.  Signal is only supported on PHEV programs.";
CM_ SG_ 357 BpedDrvAppl_D_Actl "CCMGenSigTimeoutTime=1000";
CM_ SG_ 357 CcStat_D_Actl "ABSGenSigTimeoutTime=1000";
CM_ SG_ 357 AccStopMde_D_Rq "ABSGenSigTimeoutTime=1000";
CM_ SG_ 390 AccBrkTot_A_Rq "ABSGenSigTimeoutTime=1000";
CM_ SG_ 390 AccBrkPrkEl_B_Rq "ABSGenSigTimeoutTime=1000";
CM_ SG_ 390 AccPrpl_A_Rq "PCMGenSigTimeoutTime=1000";
CM_ SG_ 390 AccBrkPrchg_B_Rq "ABSGenSigTimeoutTime=1000";
CM_ SG_ 390 AccBrkDecel_B_Rq "ABSGenSigTimeoutTime=1000";
CM_ SG_ 390 AccStopStat_B_Rq "ABSGenSigTimeoutTime=1000";
CM_ SG_ 1071 CluPdl_PcRate_Actl "Signal not transmitted on HEV variants.";
CM_ SG_ 1071 CluPdlPosPcMeas_D_Qf "Signal not transmitted on HEV variants.";
CM_ SG_ 1071 CluPdlPos_Pc_Meas "Signal not transmitted on HEV variants.";
CM_ SG_ 1071 EngAoutIdl_N_Ntrl "Signal not transmitted on HEV variants and diesel.";
CM_ SG_ 1072 Outside_Air_Temp_Stat "Filtered value, i.e. same as disply for customer";
CM_ SG_ 1058 TrnTotTq_Rt_Est "Signal not transmitted on gas and HEV variants.";
CM_ SG_ 1058 TrnTotLss_Tq_Est "Signal not transmitted on gas and HEV variants.";
BA_DEF_ SG_  "GenSigTimeoutTime_GWM" INT 0 100000;
BA_DEF_ BO_  "FrameGatewayNetwork" STRING ;
BA_DEF_ BO_  "FrameGatewayMS1" HEX 0 1407;
BA_DEF_ BO_  "FrameGatewayHS3" HEX 0 1407;
BA_DEF_ BO_  "FrameGatewayHS1" HEX 0 1407;
BA_DEF_ BO_  "NetworkInitialization" ENUM  "No","Yes";
BA_DEF_ BO_  "FrameGatewayId" HEX 0 1407;
BA_DEF_ BO_  "EventRateOfChange" INT 10 10000;
BA_DEF_ BO_  "GenMsgStartDelayTime" INT 0 10000;
BA_DEF_ BO_  "GenMsgNrOfRepetition" INT 0 100;
BA_DEF_ BO_  "GenMsgDelayTime" INT 0 1000;
BA_DEF_ BO_  "GenMsgCycleTime" INT 0 100000;
BA_DEF_ BO_  "GenMsgSendType" ENUM  "FixedPeriodic","Event","EnabledPeriodic","NotUsed","NotUsed","EventPeriodic","NotUsed","NotUsed","NoMsgSendType";
BA_DEF_ SG_  "U_U611_U625_MY20_Phev_Tx" ENUM  "No","Yes";
BA_DEF_ SG_  "U_CX482_CX483_MY20_Hev_Tx" ENUM  "No","Yes";
BA_DEF_ SG_  "U_CX482_CX483_MY20_Gas_Tx" ENUM  "No","Yes";
BA_DEF_ SG_  "U_CX482_CX483_MY20_Diesel_Tx" ENUM  "No","Yes";
BA_DEF_ SG_  "U_U611_U625_MY20_Hev_Tx" ENUM  "No","Yes";
BA_DEF_ SG_  "U_U611_U625_MY20_Gas_Tx" ENUM  "No","Yes";
BA_DEF_ SG_  "U_U611_U625_MY20_Diesel_Tx" ENUM  "No","Yes";
BA_DEF_ SG_  "U_LC1_B500_MY18_Gas_Tx" ENUM  "No","Yes";
BA_DEF_ SG_  "U_LC1_B500_MY18_Diesel_Tx" ENUM  "No","Yes";
BA_DEF_ SG_  "U_B500_MY18_Diesel_Tx" ENUM  "No","Yes";
BA_DEF_ SG_  "U_B500_MY18_Gas_Tx" ENUM  "No","Yes";
BA_DEF_ SG_  "U_C490_MY18_Tx" ENUM  "No","Yes";
BA_DEF_ SG_  "U_B562_MY18_Gas_Tx" ENUM  "No","Yes";
BA_DEF_ SG_  "U_C519_MY18_5_Gas_Tx" ENUM  "No","Yes";
BA_DEF_ SG_  "U_C519_MY18_5_Diesel_Tx" ENUM  "No","Yes";
BA_DEF_ SG_  "U_B515_MCA_MY17_Gas_Tx" ENUM  "No","Yes";
BA_DEF_ SG_  "U_B515_MCA_MY17_Diesel_Tx" ENUM  "No","Yes";
BA_DEF_ SG_  "U_B479_MY17_Diesel_Tx" ENUM  "No","Yes";
BA_DEF_ SG_  "U_B479_MY17_Gas_Tx" ENUM  "No","Yes";
BA_DEF_ SG_  "U_B562LC_MY15_Gas_Tx" ENUM  "No","Yes";
BA_DEF_ SG_  "U_B562LC_MY15_Diesel_Tx" ENUM  "No","Yes";
BA_DEF_ SG_  "U_U611_U625_MY20_Phev_Rx" ENUM  "No","Yes";
BA_DEF_ SG_  "U_CX482_CX483_MY20_Hev_Rx" ENUM  "No","Yes";
BA_DEF_ SG_  "U_CX482_CX483_MY20_Gas_Rx" ENUM  "No","Yes";
BA_DEF_ SG_  "U_CX482_CX483_MY20_Diesel_Rx" ENUM  "No","Yes";
BA_DEF_ SG_  "U_U611_U625_MY20_Hev_Rx" ENUM  "No","Yes";
BA_DEF_ SG_  "U_U611_U625_MY20_Gas_Rx" ENUM  "No","Yes";
BA_DEF_ SG_  "U_U611_U625_MY20_Diesel_Rx" ENUM  "No","Yes";
BA_DEF_ SG_  "U_B500_MY18_Diesel_Rx" ENUM  "No","Yes";
BA_DEF_ SG_  "U_B500_MY18_Gas_Rx" ENUM  "No","Yes";
BA_DEF_ SG_  "U_C490_MY18_Rx" ENUM  "No","Yes";
BA_DEF_ SG_  "U_B562_MY18_Gas_Rx" ENUM  "No","Yes";
BA_DEF_ SG_  "U_C519_MY18_5_Gas_Rx" ENUM  "No","Yes";
BA_DEF_ SG_  "U_C519_MY18_5_Diesel_Rx" ENUM  "No","Yes";
BA_DEF_ SG_  "U_B515_MCA_MY17_Gas_Rx" ENUM  "No","Yes";
BA_DEF_ SG_  "U_B515_MCA_MY17_Diesel_Rx" ENUM  "No","Yes";
BA_DEF_ SG_  "U_B479_MY17_Diesel_Rx" ENUM  "No","Yes";
BA_DEF_ SG_  "U_B479_MY17_Gas_Rx" ENUM  "No","Yes";
BA_DEF_ SG_  "U_B562LC_MY15_Gas_Rx" ENUM  "No","Yes";
BA_DEF_ SG_  "U_B562LC_MY15_Diesel_Rx" ENUM  "No","Yes";
BA_DEF_ SG_  "ContentDependant" ENUM  "No","Yes";
BA_DEF_ SG_  "GenSigStartValue" INT 0 1000000000;
BA_DEF_ SG_  "UsedOnPgmDBC" ENUM  "No","Yes";
BA_DEF_ SG_  "CrossOver_InfoCAN" ENUM  "No","Yes";
BA_DEF_ SG_  "WakeupSignal" ENUM  "No","Yes";
BA_DEF_ SG_  "GenSigMissingSourceValue" INT 0 1000000000;
BA_DEF_ SG_  "GenSigSendType" ENUM  "Cyclic","OnWrite","vector_leerstring","OnChange","vector_leerstring","IfActive","vector_leerstring","NoSigSendType";
BA_DEF_ BO_  "GenMsgRoutingTimeoutTime" INT 0 1000;
BA_DEF_ BO_  "MessageGateway" ENUM  "No","Yes";
BA_DEF_ BO_  "NmAsrMessage" ENUM  "No","Yes";
BA_DEF_ BO_  "TpApplType" STRING ;
BA_DEF_ BO_  "DiagState" ENUM  "No","Yes";
BA_DEF_ BO_  "DiagRequest" ENUM  "No","Yes";
BA_DEF_ BO_  "DiagResponse" ENUM  "No","Yes";
BA_DEF_ BO_  "GenMsgILSupport" ENUM  "No","Yes";
BA_DEF_DEF_  "GenSigTimeoutTime_GWM" 0;
BA_DEF_DEF_  "FrameGatewayNetwork" "NONE";
BA_DEF_DEF_  "FrameGatewayMS1" 0;
BA_DEF_DEF_  "FrameGatewayHS3" 0;
BA_DEF_DEF_  "FrameGatewayHS1" 0;
BA_DEF_DEF_  "NetworkInitialization" "Yes";
BA_DEF_DEF_  "FrameGatewayId" 0;
BA_DEF_DEF_  "EventRateOfChange" 10000;
BA_DEF_DEF_  "GenMsgStartDelayTime" 0;
BA_DEF_DEF_  "GenMsgNrOfRepetition" 1;
BA_DEF_DEF_  "GenMsgDelayTime" 20;
BA_DEF_DEF_  "GenMsgCycleTime" 0;
BA_DEF_DEF_  "GenMsgSendType" "NoMsgSendType";
BA_DEF_DEF_  "U_U611_U625_MY20_Phev_Tx" "No";
BA_DEF_DEF_  "U_CX482_CX483_MY20_Hev_Tx" "No";
BA_DEF_DEF_  "U_CX482_CX483_MY20_Gas_Tx" "No";
BA_DEF_DEF_  "U_CX482_CX483_MY20_Diesel_Tx" "No";
BA_DEF_DEF_  "U_U611_U625_MY20_Hev_Tx" "No";
BA_DEF_DEF_  "U_U611_U625_MY20_Gas_Tx" "No";
BA_DEF_DEF_  "U_U611_U625_MY20_Diesel_Tx" "No";
BA_DEF_DEF_  "U_LC1_B500_MY18_Gas_Tx" "No";
BA_DEF_DEF_  "U_LC1_B500_MY18_Diesel_Tx" "No";
BA_DEF_DEF_  "U_B500_MY18_Diesel_Tx" "No";
BA_DEF_DEF_  "U_B500_MY18_Gas_Tx" "No";
BA_DEF_DEF_  "U_C490_MY18_Tx" "No";
BA_DEF_DEF_  "U_B562_MY18_Gas_Tx" "No";
BA_DEF_DEF_  "U_C519_MY18_5_Gas_Tx" "No";
BA_DEF_DEF_  "U_C519_MY18_5_Diesel_Tx" "No";
BA_DEF_DEF_  "U_B515_MCA_MY17_Gas_Tx" "No";
BA_DEF_DEF_  "U_B515_MCA_MY17_Diesel_Tx" "No";
BA_DEF_DEF_  "U_B479_MY17_Diesel_Tx" "No";
BA_DEF_DEF_  "U_B479_MY17_Gas_Tx" "No";
BA_DEF_DEF_  "U_B562LC_MY15_Gas_Tx" "No";
BA_DEF_DEF_  "U_B562LC_MY15_Diesel_Tx" "No";
BA_DEF_DEF_  "U_U611_U625_MY20_Phev_Rx" "No";
BA_DEF_DEF_  "U_CX482_CX483_MY20_Hev_Rx" "No";
BA_DEF_DEF_  "U_CX482_CX483_MY20_Gas_Rx" "No";
BA_DEF_DEF_  "U_CX482_CX483_MY20_Diesel_Rx" "No";
BA_DEF_DEF_  "U_U611_U625_MY20_Hev_Rx" "No";
BA_DEF_DEF_  "U_U611_U625_MY20_Gas_Rx" "No";
BA_DEF_DEF_  "U_U611_U625_MY20_Diesel_Rx" "No";
BA_DEF_DEF_  "U_B500_MY18_Diesel_Rx" "No";
BA_DEF_DEF_  "U_B500_MY18_Gas_Rx" "No";
BA_DEF_DEF_  "U_C490_MY18_Rx" "No";
BA_DEF_DEF_  "U_B562_MY18_Gas_Rx" "No";
BA_DEF_DEF_  "U_C519_MY18_5_Gas_Rx" "No";
BA_DEF_DEF_  "U_C519_MY18_5_Diesel_Rx" "No";
BA_DEF_DEF_  "U_B515_MCA_MY17_Gas_Rx" "No";
BA_DEF_DEF_  "U_B515_MCA_MY17_Diesel_Rx" "No";
BA_DEF_DEF_  "U_B479_MY17_Diesel_Rx" "No";
BA_DEF_DEF_  "U_B479_MY17_Gas_Rx" "No";
BA_DEF_DEF_  "U_B562LC_MY15_Gas_Rx" "No";
BA_DEF_DEF_  "U_B562LC_MY15_Diesel_Rx" "No";
BA_DEF_DEF_  "ContentDependant" "No";
BA_DEF_DEF_  "GenSigStartValue" 0;
BA_DEF_DEF_  "UsedOnPgmDBC" "Yes";
BA_DEF_DEF_  "CrossOver_InfoCAN" "No";
BA_DEF_DEF_  "WakeupSignal" "No";
BA_DEF_DEF_  "GenSigMissingSourceValue" 0;
BA_DEF_DEF_  "GenSigSendType" "NoSigSendType";
BA_DEF_DEF_  "GenMsgRoutingTimeoutTime" 0;
BA_DEF_DEF_  "MessageGateway" "No";
BA_DEF_DEF_  "NmAsrMessage" "No";
BA_DEF_DEF_  "TpApplType" "";
BA_DEF_DEF_  "DiagState" "No";
BA_DEF_DEF_  "DiagRequest" "No";
BA_DEF_DEF_  "DiagResponse" "No";
BA_DEF_DEF_  "GenMsgILSupport" "Yes";
BA_ "GenMsgStartDelayTime" BO_ 1073 100;
BA_ "GenMsgCycleTime" BO_ 1073 1000;
BA_ "GenMsgSendType" BO_ 1073 5;
BA_ "GenMsgCycleTime" BO_ 1092 1000;
BA_ "GenMsgSendType" BO_ 1092 5;
BA_ "NetworkInitialization" BO_ 1876 0;
BA_ "GenMsgDelayTime" BO_ 1876 0;
BA_ "GenMsgSendType" BO_ 1876 1;
BA_ "DiagRequest" BO_ 1876 1;
BA_ "GenMsgILSupport" BO_ 1876 0;
BA_ "NetworkInitialization" BO_ 1884 0;
BA_ "GenMsgDelayTime" BO_ 1884 0;
BA_ "GenMsgSendType" BO_ 1884 1;
BA_ "DiagResponse" BO_ 1884 1;
BA_ "GenMsgILSupport" BO_ 1884 0;
BA_ "FrameGatewayNetwork" BO_ 71 "HS1_CAN";
BA_ "FrameGatewayHS1" BO_ 71 71;
BA_ "FrameGatewayId" BO_ 71 71;
BA_ "GenMsgCycleTime" BO_ 973 1000;
BA_ "GenMsgSendType" BO_ 973 5;
BA_ "GenMsgCycleTime" BO_ 825 30;
BA_ "GenMsgSendType" BO_ 825 0;
BA_ "GenMsgCycleTime" BO_ 837 1000;
BA_ "GenMsgSendType" BO_ 837 5;
BA_ "FrameGatewayNetwork" BO_ 1091 "MS1_CAN";
BA_ "FrameGatewayMS1" BO_ 1091 1091;
BA_ "FrameGatewayId" BO_ 1091 1091;
BA_ "GenMsgCycleTime" BO_ 1068 100;
BA_ "GenMsgSendType" BO_ 1068 5;
BA_ "GenMsgRoutingTimeoutTime" BO_ 1068 150;
BA_ "MessageGateway" BO_ 1068 1;
BA_ "GenMsgCycleTime" BO_ 611 100;
BA_ "GenMsgSendType" BO_ 611 0;
BA_ "FrameGatewayNetwork" BO_ 395 "HS3_CAN";
BA_ "FrameGatewayId" BO_ 395 395;
BA_ "GenMsgCycleTime" BO_ 578 100;
BA_ "GenMsgSendType" BO_ 578 5;
BA_ "GenMsgRoutingTimeoutTime" BO_ 578 120;
BA_ "MessageGateway" BO_ 578 1;
BA_ "GenMsgDelayTime" BO_ 560 10;
BA_ "GenMsgCycleTime" BO_ 560 100;
BA_ "GenMsgSendType" BO_ 560 5;
BA_ "GenMsgRoutingTimeoutTime" BO_ 560 60;
BA_ "MessageGateway" BO_ 560 1;
BA_ "FrameGatewayNetwork" BO_ 359 "HS1_CAN";
BA_ "FrameGatewayHS1" BO_ 359 359;
BA_ "FrameGatewayId" BO_ 359 359;
BA_ "FrameGatewayNetwork" BO_ 372 "HS1_CAN";
BA_ "FrameGatewayHS1" BO_ 372 372;
BA_ "FrameGatewayId" BO_ 372 372;
BA_ "GenMsgDelayTime" BO_ 357 10;
BA_ "GenMsgCycleTime" BO_ 357 100;
BA_ "GenMsgSendType" BO_ 357 5;
BA_ "GenMsgRoutingTimeoutTime" BO_ 357 60;
BA_ "MessageGateway" BO_ 357 1;
BA_ "NetworkInitialization" BO_ 1461 0;
BA_ "GenMsgCycleTime" BO_ 1461 1000;
BA_ "GenMsgSendType" BO_ 1461 0;
BA_ "NmAsrMessage" BO_ 1461 1;
BA_ "GenMsgDelayTime" BO_ 390 10;
BA_ "GenMsgCycleTime" BO_ 390 20;
BA_ "GenMsgSendType" BO_ 390 0;
BA_ "NetworkInitialization" BO_ 1947 0;
BA_ "GenMsgDelayTime" BO_ 1947 0;
BA_ "GenMsgSendType" BO_ 1947 1;
BA_ "DiagResponse" BO_ 1947 1;
BA_ "GenMsgILSupport" BO_ 1947 0;
BA_ "NetworkInitialization" BO_ 1939 0;
BA_ "GenMsgDelayTime" BO_ 1939 0;
BA_ "GenMsgSendType" BO_ 1939 1;
BA_ "DiagRequest" BO_ 1939 1;
BA_ "GenMsgILSupport" BO_ 1939 0;
BA_ "FrameGatewayNetwork" BO_ 1071 "HS1_CAN";
BA_ "FrameGatewayHS1" BO_ 1071 1071;
BA_ "FrameGatewayId" BO_ 1071 1071;
BA_ "GenMsgStartDelayTime" BO_ 1072 200;
BA_ "GenMsgCycleTime" BO_ 1072 100;
BA_ "GenMsgSendType" BO_ 1072 5;
BA_ "GenMsgCycleTime" BO_ 1058 100;
BA_ "GenMsgSendType" BO_ 1058 0;
BA_ "GenSigSendType" SG_ 1073 CamraFrntBttn_D_Stat 3;
BA_ "U_CX482_CX483_MY20_Hev_Rx" SG_ 1073 BrkDrvMde_D_Rq_UB 1;
BA_ "U_CX482_CX483_MY20_Gas_Rx" SG_ 1073 BrkDrvMde_D_Rq_UB 1;
BA_ "U_CX482_CX483_MY20_Diesel_Rx" SG_ 1073 BrkDrvMde_D_Rq_UB 1;
BA_ "U_C519_MY18_5_Gas_Rx" SG_ 1073 BrkDrvMde_D_Rq_UB 1;
BA_ "U_C519_MY18_5_Diesel_Rx" SG_ 1073 BrkDrvMde_D_Rq_UB 1;
BA_ "U_B515_MCA_MY17_Gas_Rx" SG_ 1073 BrkDrvMde_D_Rq_UB 1;
BA_ "U_B515_MCA_MY17_Diesel_Rx" SG_ 1073 BrkDrvMde_D_Rq_UB 1;
BA_ "U_B479_MY17_Diesel_Rx" SG_ 1073 BrkDrvMde_D_Rq_UB 1;
BA_ "U_B479_MY17_Gas_Rx" SG_ 1073 BrkDrvMde_D_Rq_UB 1;
BA_ "U_CX482_CX483_MY20_Hev_Rx" SG_ 1073 BrkDrvMde_D_Rq 1;
BA_ "U_CX482_CX483_MY20_Gas_Rx" SG_ 1073 BrkDrvMde_D_Rq 1;
BA_ "U_CX482_CX483_MY20_Diesel_Rx" SG_ 1073 BrkDrvMde_D_Rq 1;
BA_ "U_C519_MY18_5_Gas_Rx" SG_ 1073 BrkDrvMde_D_Rq 1;
BA_ "U_C519_MY18_5_Diesel_Rx" SG_ 1073 BrkDrvMde_D_Rq 1;
BA_ "U_B515_MCA_MY17_Gas_Rx" SG_ 1073 BrkDrvMde_D_Rq 1;
BA_ "U_B515_MCA_MY17_Diesel_Rx" SG_ 1073 BrkDrvMde_D_Rq 1;
BA_ "U_B479_MY17_Diesel_Rx" SG_ 1073 BrkDrvMde_D_Rq 1;
BA_ "U_B479_MY17_Gas_Rx" SG_ 1073 BrkDrvMde_D_Rq 1;
BA_ "GenSigSendType" SG_ 1073 BrkDrvMde_D_Rq 3;
BA_ "U_B500_MY18_Diesel_Rx" SG_ 1073 SteEffort_D_Rq 1;
BA_ "U_B500_MY18_Gas_Rx" SG_ 1073 SteEffort_D_Rq 1;
BA_ "U_B479_MY17_Diesel_Rx" SG_ 1073 SteEffort_D_Rq 1;
BA_ "U_B479_MY17_Gas_Rx" SG_ 1073 SteEffort_D_Rq 1;
BA_ "GenSigSendType" SG_ 1073 SteEffort_D_Rq 3;
BA_ "U_B500_MY18_Diesel_Rx" SG_ 1073 SteEffort_D_Rq_UB 1;
BA_ "U_B500_MY18_Gas_Rx" SG_ 1073 SteEffort_D_Rq_UB 1;
BA_ "U_B479_MY17_Diesel_Rx" SG_ 1073 SteEffort_D_Rq_UB 1;
BA_ "U_B479_MY17_Gas_Rx" SG_ 1073 SteEffort_D_Rq_UB 1;
BA_ "U_CX482_CX483_MY20_Hev_Rx" SG_ 1073 AutoHoldSwtch_D_Stat_UB 1;
BA_ "U_CX482_CX483_MY20_Gas_Rx" SG_ 1073 AutoHoldSwtch_D_Stat_UB 1;
BA_ "U_CX482_CX483_MY20_Diesel_Rx" SG_ 1073 AutoHoldSwtch_D_Stat_UB 1;
BA_ "U_C519_MY18_5_Gas_Rx" SG_ 1073 AutoHoldSwtch_D_Stat_UB 1;
BA_ "U_C519_MY18_5_Diesel_Rx" SG_ 1073 AutoHoldSwtch_D_Stat_UB 1;
BA_ "U_CX482_CX483_MY20_Hev_Rx" SG_ 1073 AutoHoldSwtch_D_Stat 1;
BA_ "U_CX482_CX483_MY20_Gas_Rx" SG_ 1073 AutoHoldSwtch_D_Stat 1;
BA_ "U_CX482_CX483_MY20_Diesel_Rx" SG_ 1073 AutoHoldSwtch_D_Stat 1;
BA_ "U_C519_MY18_5_Gas_Rx" SG_ 1073 AutoHoldSwtch_D_Stat 1;
BA_ "U_C519_MY18_5_Diesel_Rx" SG_ 1073 AutoHoldSwtch_D_Stat 1;
BA_ "GenSigSendType" SG_ 1073 AutoHoldSwtch_D_Stat 3;
BA_ "U_U611_U625_MY20_Phev_Rx" SG_ 1073 HMI_HMIMode_St_UB 1;
BA_ "U_CX482_CX483_MY20_Hev_Rx" SG_ 1073 HMI_HMIMode_St_UB 1;
BA_ "U_CX482_CX483_MY20_Gas_Rx" SG_ 1073 HMI_HMIMode_St_UB 1;
BA_ "U_CX482_CX483_MY20_Diesel_Rx" SG_ 1073 HMI_HMIMode_St_UB 1;
BA_ "U_U611_U625_MY20_Hev_Rx" SG_ 1073 HMI_HMIMode_St_UB 1;
BA_ "U_U611_U625_MY20_Gas_Rx" SG_ 1073 HMI_HMIMode_St_UB 1;
BA_ "U_U611_U625_MY20_Diesel_Rx" SG_ 1073 HMI_HMIMode_St_UB 1;
BA_ "U_B500_MY18_Diesel_Rx" SG_ 1073 HMI_HMIMode_St_UB 1;
BA_ "U_B500_MY18_Gas_Rx" SG_ 1073 HMI_HMIMode_St_UB 1;
BA_ "U_C519_MY18_5_Gas_Rx" SG_ 1073 HMI_HMIMode_St_UB 1;
BA_ "U_C519_MY18_5_Diesel_Rx" SG_ 1073 HMI_HMIMode_St_UB 1;
BA_ "U_B515_MCA_MY17_Gas_Rx" SG_ 1073 HMI_HMIMode_St_UB 1;
BA_ "U_B515_MCA_MY17_Diesel_Rx" SG_ 1073 HMI_HMIMode_St_UB 1;
BA_ "U_B479_MY17_Diesel_Rx" SG_ 1073 HMI_HMIMode_St_UB 1;
BA_ "U_B479_MY17_Gas_Rx" SG_ 1073 HMI_HMIMode_St_UB 1;
BA_ "U_U611_U625_MY20_Phev_Rx" SG_ 1073 HMI_HMIMode_St 1;
BA_ "U_CX482_CX483_MY20_Hev_Rx" SG_ 1073 HMI_HMIMode_St 1;
BA_ "U_CX482_CX483_MY20_Gas_Rx" SG_ 1073 HMI_HMIMode_St 1;
BA_ "U_CX482_CX483_MY20_Diesel_Rx" SG_ 1073 HMI_HMIMode_St 1;
BA_ "U_U611_U625_MY20_Hev_Rx" SG_ 1073 HMI_HMIMode_St 1;
BA_ "U_U611_U625_MY20_Gas_Rx" SG_ 1073 HMI_HMIMode_St 1;
BA_ "U_U611_U625_MY20_Diesel_Rx" SG_ 1073 HMI_HMIMode_St 1;
BA_ "U_B500_MY18_Diesel_Rx" SG_ 1073 HMI_HMIMode_St 1;
BA_ "U_B500_MY18_Gas_Rx" SG_ 1073 HMI_HMIMode_St 1;
BA_ "U_C519_MY18_5_Gas_Rx" SG_ 1073 HMI_HMIMode_St 1;
BA_ "U_C519_MY18_5_Diesel_Rx" SG_ 1073 HMI_HMIMode_St 1;
BA_ "U_B515_MCA_MY17_Gas_Rx" SG_ 1073 HMI_HMIMode_St 1;
BA_ "U_B515_MCA_MY17_Diesel_Rx" SG_ 1073 HMI_HMIMode_St 1;
BA_ "U_B479_MY17_Diesel_Rx" SG_ 1073 HMI_HMIMode_St 1;
BA_ "U_B479_MY17_Gas_Rx" SG_ 1073 HMI_HMIMode_St 1;
BA_ "GenSigSendType" SG_ 1073 HMI_HMIMode_St 3;
BA_ "CrossOver_InfoCAN" SG_ 1073 HMI_HMIMode_St 1;
BA_ "WakeupSignal" SG_ 1073 HMI_HMIMode_St 1;
BA_ "U_U611_U625_MY20_Phev_Rx" SG_ 1073 Veh_Lock_Requestor_UB 1;
BA_ "U_CX482_CX483_MY20_Hev_Rx" SG_ 1073 Veh_Lock_Requestor_UB 1;
BA_ "U_CX482_CX483_MY20_Gas_Rx" SG_ 1073 Veh_Lock_Requestor_UB 1;
BA_ "U_CX482_CX483_MY20_Diesel_Rx" SG_ 1073 Veh_Lock_Requestor_UB 1;
BA_ "U_U611_U625_MY20_Hev_Rx" SG_ 1073 Veh_Lock_Requestor_UB 1;
BA_ "U_U611_U625_MY20_Gas_Rx" SG_ 1073 Veh_Lock_Requestor_UB 1;
BA_ "U_U611_U625_MY20_Diesel_Rx" SG_ 1073 Veh_Lock_Requestor_UB 1;
BA_ "U_C519_MY18_5_Gas_Rx" SG_ 1073 Veh_Lock_Requestor_UB 1;
BA_ "U_C519_MY18_5_Diesel_Rx" SG_ 1073 Veh_Lock_Requestor_UB 1;
BA_ "U_U611_U625_MY20_Phev_Rx" SG_ 1073 Veh_Lock_EvNum_UB 1;
BA_ "U_CX482_CX483_MY20_Hev_Rx" SG_ 1073 Veh_Lock_EvNum_UB 1;
BA_ "U_CX482_CX483_MY20_Gas_Rx" SG_ 1073 Veh_Lock_EvNum_UB 1;
BA_ "U_CX482_CX483_MY20_Diesel_Rx" SG_ 1073 Veh_Lock_EvNum_UB 1;
BA_ "U_U611_U625_MY20_Hev_Rx" SG_ 1073 Veh_Lock_EvNum_UB 1;
BA_ "U_U611_U625_MY20_Gas_Rx" SG_ 1073 Veh_Lock_EvNum_UB 1;
BA_ "U_U611_U625_MY20_Diesel_Rx" SG_ 1073 Veh_Lock_EvNum_UB 1;
BA_ "U_C519_MY18_5_Gas_Rx" SG_ 1073 Veh_Lock_EvNum_UB 1;
BA_ "U_C519_MY18_5_Diesel_Rx" SG_ 1073 Veh_Lock_EvNum_UB 1;
BA_ "U_U611_U625_MY20_Phev_Rx" SG_ 1073 Veh_Lock_Status_UB 1;
BA_ "U_CX482_CX483_MY20_Hev_Rx" SG_ 1073 Veh_Lock_Status_UB 1;
BA_ "U_CX482_CX483_MY20_Gas_Rx" SG_ 1073 Veh_Lock_Status_UB 1;
BA_ "U_CX482_CX483_MY20_Diesel_Rx" SG_ 1073 Veh_Lock_Status_UB 1;
BA_ "U_U611_U625_MY20_Hev_Rx" SG_ 1073 Veh_Lock_Status_UB 1;
BA_ "U_U611_U625_MY20_Gas_Rx" SG_ 1073 Veh_Lock_Status_UB 1;
BA_ "U_U611_U625_MY20_Diesel_Rx" SG_ 1073 Veh_Lock_Status_UB 1;
BA_ "U_C519_MY18_5_Gas_Rx" SG_ 1073 Veh_Lock_Status_UB 1;
BA_ "U_C519_MY18_5_Diesel_Rx" SG_ 1073 Veh_Lock_Status_UB 1;
BA_ "GenSigSendType" SG_ 1073 Veh_Lock_Sub_Id 3;
BA_ "U_U611_U625_MY20_Phev_Rx" SG_ 1073 Veh_Lock_Status 1;
BA_ "U_CX482_CX483_MY20_Hev_Rx" SG_ 1073 Veh_Lock_Status 1;
BA_ "U_CX482_CX483_MY20_Gas_Rx" SG_ 1073 Veh_Lock_Status 1;
BA_ "U_CX482_CX483_MY20_Diesel_Rx" SG_ 1073 Veh_Lock_Status 1;
BA_ "U_U611_U625_MY20_Hev_Rx" SG_ 1073 Veh_Lock_Status 1;
BA_ "U_U611_U625_MY20_Gas_Rx" SG_ 1073 Veh_Lock_Status 1;
BA_ "U_U611_U625_MY20_Diesel_Rx" SG_ 1073 Veh_Lock_Status 1;
BA_ "U_C519_MY18_5_Gas_Rx" SG_ 1073 Veh_Lock_Status 1;
BA_ "U_C519_MY18_5_Diesel_Rx" SG_ 1073 Veh_Lock_Status 1;
BA_ "GenSigSendType" SG_ 1073 Veh_Lock_Status 3;
BA_ "GenSigStartValue" SG_ 1073 Veh_Lock_Status 1;
BA_ "WakeupSignal" SG_ 1073 Veh_Lock_Status 1;
BA_ "U_U611_U625_MY20_Phev_Rx" SG_ 1073 Veh_Lock_Requestor 1;
BA_ "U_CX482_CX483_MY20_Hev_Rx" SG_ 1073 Veh_Lock_Requestor 1;
BA_ "U_CX482_CX483_MY20_Gas_Rx" SG_ 1073 Veh_Lock_Requestor 1;
BA_ "U_CX482_CX483_MY20_Diesel_Rx" SG_ 1073 Veh_Lock_Requestor 1;
BA_ "U_U611_U625_MY20_Hev_Rx" SG_ 1073 Veh_Lock_Requestor 1;
BA_ "U_U611_U625_MY20_Gas_Rx" SG_ 1073 Veh_Lock_Requestor 1;
BA_ "U_U611_U625_MY20_Diesel_Rx" SG_ 1073 Veh_Lock_Requestor 1;
BA_ "U_C519_MY18_5_Gas_Rx" SG_ 1073 Veh_Lock_Requestor 1;
BA_ "U_C519_MY18_5_Diesel_Rx" SG_ 1073 Veh_Lock_Requestor 1;
BA_ "GenSigSendType" SG_ 1073 Veh_Lock_Requestor 3;
BA_ "WakeupSignal" SG_ 1073 Veh_Lock_Requestor 1;
BA_ "U_U611_U625_MY20_Phev_Rx" SG_ 1073 Veh_Lock_EvNum 1;
BA_ "U_CX482_CX483_MY20_Hev_Rx" SG_ 1073 Veh_Lock_EvNum 1;
BA_ "U_CX482_CX483_MY20_Gas_Rx" SG_ 1073 Veh_Lock_EvNum 1;
BA_ "U_CX482_CX483_MY20_Diesel_Rx" SG_ 1073 Veh_Lock_EvNum 1;
BA_ "U_U611_U625_MY20_Hev_Rx" SG_ 1073 Veh_Lock_EvNum 1;
BA_ "U_U611_U625_MY20_Gas_Rx" SG_ 1073 Veh_Lock_EvNum 1;
BA_ "U_U611_U625_MY20_Diesel_Rx" SG_ 1073 Veh_Lock_EvNum 1;
BA_ "U_C519_MY18_5_Gas_Rx" SG_ 1073 Veh_Lock_EvNum 1;
BA_ "U_C519_MY18_5_Diesel_Rx" SG_ 1073 Veh_Lock_EvNum 1;
BA_ "GenSigSendType" SG_ 1073 Veh_Lock_EvNum 3;
BA_ "WakeupSignal" SG_ 1073 Veh_Lock_EvNum 1;
BA_ "GenSigSendType" SG_ 1073 Tire_Press_System_Stat 3;
BA_ "CrossOver_InfoCAN" SG_ 1073 Tire_Press_System_Stat 1;
BA_ "U_CX482_CX483_MY20_Hev_Rx" SG_ 1073 DISPLAY_SPEED_OFFSET_UB 1;
BA_ "U_CX482_CX483_MY20_Gas_Rx" SG_ 1073 DISPLAY_SPEED_OFFSET_UB 1;
BA_ "U_CX482_CX483_MY20_Diesel_Rx" SG_ 1073 DISPLAY_SPEED_OFFSET_UB 1;
BA_ "U_U611_U625_MY20_Hev_Rx" SG_ 1073 DISPLAY_SPEED_OFFSET_UB 1;
BA_ "U_U611_U625_MY20_Gas_Rx" SG_ 1073 DISPLAY_SPEED_OFFSET_UB 1;
BA_ "U_U611_U625_MY20_Diesel_Rx" SG_ 1073 DISPLAY_SPEED_OFFSET_UB 1;
BA_ "U_C519_MY18_5_Gas_Rx" SG_ 1073 DISPLAY_SPEED_OFFSET_UB 1;
BA_ "U_C519_MY18_5_Diesel_Rx" SG_ 1073 DISPLAY_SPEED_OFFSET_UB 1;
BA_ "U_B479_MY17_Diesel_Rx" SG_ 1073 DISPLAY_SPEED_OFFSET_UB 1;
BA_ "U_B479_MY17_Gas_Rx" SG_ 1073 DISPLAY_SPEED_OFFSET_UB 1;
BA_ "U_CX482_CX483_MY20_Hev_Rx" SG_ 1073 DISPLAY_SPEED_OFFSET 1;
BA_ "U_CX482_CX483_MY20_Gas_Rx" SG_ 1073 DISPLAY_SPEED_OFFSET 1;
BA_ "U_CX482_CX483_MY20_Diesel_Rx" SG_ 1073 DISPLAY_SPEED_OFFSET 1;
BA_ "U_U611_U625_MY20_Hev_Rx" SG_ 1073 DISPLAY_SPEED_OFFSET 1;
BA_ "U_U611_U625_MY20_Gas_Rx" SG_ 1073 DISPLAY_SPEED_OFFSET 1;
BA_ "U_U611_U625_MY20_Diesel_Rx" SG_ 1073 DISPLAY_SPEED_OFFSET 1;
BA_ "U_C519_MY18_5_Gas_Rx" SG_ 1073 DISPLAY_SPEED_OFFSET 1;
BA_ "U_C519_MY18_5_Diesel_Rx" SG_ 1073 DISPLAY_SPEED_OFFSET 1;
BA_ "U_B479_MY17_Diesel_Rx" SG_ 1073 DISPLAY_SPEED_OFFSET 1;
BA_ "U_B479_MY17_Gas_Rx" SG_ 1073 DISPLAY_SPEED_OFFSET 1;
BA_ "GenSigSendType" SG_ 1073 DISPLAY_SPEED_OFFSET 3;
BA_ "CrossOver_InfoCAN" SG_ 1073 DISPLAY_SPEED_OFFSET 1;
BA_ "U_CX482_CX483_MY20_Hev_Rx" SG_ 1073 DISPLAY_SPEED_SCALING_UB 1;
BA_ "U_CX482_CX483_MY20_Gas_Rx" SG_ 1073 DISPLAY_SPEED_SCALING_UB 1;
BA_ "U_CX482_CX483_MY20_Diesel_Rx" SG_ 1073 DISPLAY_SPEED_SCALING_UB 1;
BA_ "U_U611_U625_MY20_Hev_Rx" SG_ 1073 DISPLAY_SPEED_SCALING_UB 1;
BA_ "U_U611_U625_MY20_Gas_Rx" SG_ 1073 DISPLAY_SPEED_SCALING_UB 1;
BA_ "U_U611_U625_MY20_Diesel_Rx" SG_ 1073 DISPLAY_SPEED_SCALING_UB 1;
BA_ "U_C519_MY18_5_Gas_Rx" SG_ 1073 DISPLAY_SPEED_SCALING_UB 1;
BA_ "U_C519_MY18_5_Diesel_Rx" SG_ 1073 DISPLAY_SPEED_SCALING_UB 1;
BA_ "U_B479_MY17_Diesel_Rx" SG_ 1073 DISPLAY_SPEED_SCALING_UB 1;
BA_ "U_B479_MY17_Gas_Rx" SG_ 1073 DISPLAY_SPEED_SCALING_UB 1;
BA_ "U_CX482_CX483_MY20_Hev_Rx" SG_ 1073 DISPLAY_SPEED_SCALING 1;
BA_ "U_CX482_CX483_MY20_Gas_Rx" SG_ 1073 DISPLAY_SPEED_SCALING 1;
BA_ "U_CX482_CX483_MY20_Diesel_Rx" SG_ 1073 DISPLAY_SPEED_SCALING 1;
BA_ "U_U611_U625_MY20_Hev_Rx" SG_ 1073 DISPLAY_SPEED_SCALING 1;
BA_ "U_U611_U625_MY20_Gas_Rx" SG_ 1073 DISPLAY_SPEED_SCALING 1;
BA_ "U_U611_U625_MY20_Diesel_Rx" SG_ 1073 DISPLAY_SPEED_SCALING 1;
BA_ "U_C519_MY18_5_Gas_Rx" SG_ 1073 DISPLAY_SPEED_SCALING 1;
BA_ "U_C519_MY18_5_Diesel_Rx" SG_ 1073 DISPLAY_SPEED_SCALING 1;
BA_ "U_B479_MY17_Diesel_Rx" SG_ 1073 DISPLAY_SPEED_SCALING 1;
BA_ "U_B479_MY17_Gas_Rx" SG_ 1073 DISPLAY_SPEED_SCALING 1;
BA_ "GenSigSendType" SG_ 1073 DISPLAY_SPEED_SCALING 3;
BA_ "CrossOver_InfoCAN" SG_ 1073 DISPLAY_SPEED_SCALING 1;
BA_ "U_U611_U625_MY20_Phev_Rx" SG_ 1073 Foh_D_Stat 1;
BA_ "U_CX482_CX483_MY20_Hev_Rx" SG_ 1073 Foh_D_Stat 1;
BA_ "U_CX482_CX483_MY20_Gas_Rx" SG_ 1073 Foh_D_Stat 1;
BA_ "U_CX482_CX483_MY20_Diesel_Rx" SG_ 1073 Foh_D_Stat 1;
BA_ "U_U611_U625_MY20_Hev_Rx" SG_ 1073 Foh_D_Stat 1;
BA_ "U_U611_U625_MY20_Gas_Rx" SG_ 1073 Foh_D_Stat 1;
BA_ "U_U611_U625_MY20_Diesel_Rx" SG_ 1073 Foh_D_Stat 1;
BA_ "U_B500_MY18_Diesel_Rx" SG_ 1073 Foh_D_Stat 1;
BA_ "U_B500_MY18_Gas_Rx" SG_ 1073 Foh_D_Stat 1;
BA_ "U_C519_MY18_5_Gas_Rx" SG_ 1073 Foh_D_Stat 1;
BA_ "U_C519_MY18_5_Diesel_Rx" SG_ 1073 Foh_D_Stat 1;
BA_ "U_B515_MCA_MY17_Gas_Rx" SG_ 1073 Foh_D_Stat 1;
BA_ "U_B515_MCA_MY17_Diesel_Rx" SG_ 1073 Foh_D_Stat 1;
BA_ "U_B479_MY17_Diesel_Rx" SG_ 1073 Foh_D_Stat 1;
BA_ "U_B479_MY17_Gas_Rx" SG_ 1073 Foh_D_Stat 1;
BA_ "GenSigSendType" SG_ 1073 Foh_D_Stat 3;
BA_ "ContentDependant" SG_ 1073 Foh_D_Stat 1;
BA_ "WakeupSignal" SG_ 1073 Foh_D_Stat 1;
BA_ "U_U611_U625_MY20_Phev_Rx" SG_ 1073 Foh_D_Stat_UB 1;
BA_ "U_CX482_CX483_MY20_Hev_Rx" SG_ 1073 Foh_D_Stat_UB 1;
BA_ "U_CX482_CX483_MY20_Gas_Rx" SG_ 1073 Foh_D_Stat_UB 1;
BA_ "U_CX482_CX483_MY20_Diesel_Rx" SG_ 1073 Foh_D_Stat_UB 1;
BA_ "U_U611_U625_MY20_Hev_Rx" SG_ 1073 Foh_D_Stat_UB 1;
BA_ "U_U611_U625_MY20_Gas_Rx" SG_ 1073 Foh_D_Stat_UB 1;
BA_ "U_U611_U625_MY20_Diesel_Rx" SG_ 1073 Foh_D_Stat_UB 1;
BA_ "U_B500_MY18_Diesel_Rx" SG_ 1073 Foh_D_Stat_UB 1;
BA_ "U_B500_MY18_Gas_Rx" SG_ 1073 Foh_D_Stat_UB 1;
BA_ "U_C519_MY18_5_Gas_Rx" SG_ 1073 Foh_D_Stat_UB 1;
BA_ "U_C519_MY18_5_Diesel_Rx" SG_ 1073 Foh_D_Stat_UB 1;
BA_ "U_B515_MCA_MY17_Gas_Rx" SG_ 1073 Foh_D_Stat_UB 1;
BA_ "U_B515_MCA_MY17_Diesel_Rx" SG_ 1073 Foh_D_Stat_UB 1;
BA_ "U_B479_MY17_Diesel_Rx" SG_ 1073 Foh_D_Stat_UB 1;
BA_ "U_B479_MY17_Gas_Rx" SG_ 1073 Foh_D_Stat_UB 1;
BA_ "U_U611_U625_MY20_Phev_Rx" SG_ 1073 SteWhlHeat_D_Rq_UB 1;
BA_ "U_CX482_CX483_MY20_Hev_Rx" SG_ 1073 SteWhlHeat_D_Rq_UB 1;
BA_ "U_CX482_CX483_MY20_Gas_Rx" SG_ 1073 SteWhlHeat_D_Rq_UB 1;
BA_ "U_CX482_CX483_MY20_Diesel_Rx" SG_ 1073 SteWhlHeat_D_Rq_UB 1;
BA_ "U_B500_MY18_Diesel_Rx" SG_ 1073 SteWhlHeat_D_Rq_UB 1;
BA_ "U_B500_MY18_Gas_Rx" SG_ 1073 SteWhlHeat_D_Rq_UB 1;
BA_ "U_C519_MY18_5_Gas_Rx" SG_ 1073 SteWhlHeat_D_Rq_UB 1;
BA_ "U_C519_MY18_5_Diesel_Rx" SG_ 1073 SteWhlHeat_D_Rq_UB 1;
BA_ "U_B479_MY17_Diesel_Rx" SG_ 1073 SteWhlHeat_D_Rq_UB 1;
BA_ "U_B479_MY17_Gas_Rx" SG_ 1073 SteWhlHeat_D_Rq_UB 1;
BA_ "U_U611_U625_MY20_Hev_Rx" SG_ 1073 SteWhlHeat_D_Rq_UB 1;
BA_ "U_U611_U625_MY20_Gas_Rx" SG_ 1073 SteWhlHeat_D_Rq_UB 1;
BA_ "U_U611_U625_MY20_Diesel_Rx" SG_ 1073 SteWhlHeat_D_Rq_UB 1;
BA_ "U_U611_U625_MY20_Phev_Rx" SG_ 1073 SteWhlHeat_D_Rq 1;
BA_ "U_CX482_CX483_MY20_Hev_Rx" SG_ 1073 SteWhlHeat_D_Rq 1;
BA_ "U_CX482_CX483_MY20_Gas_Rx" SG_ 1073 SteWhlHeat_D_Rq 1;
BA_ "U_CX482_CX483_MY20_Diesel_Rx" SG_ 1073 SteWhlHeat_D_Rq 1;
BA_ "U_B500_MY18_Diesel_Rx" SG_ 1073 SteWhlHeat_D_Rq 1;
BA_ "U_B500_MY18_Gas_Rx" SG_ 1073 SteWhlHeat_D_Rq 1;
BA_ "U_C519_MY18_5_Gas_Rx" SG_ 1073 SteWhlHeat_D_Rq 1;
BA_ "U_C519_MY18_5_Diesel_Rx" SG_ 1073 SteWhlHeat_D_Rq 1;
BA_ "U_B479_MY17_Diesel_Rx" SG_ 1073 SteWhlHeat_D_Rq 1;
BA_ "U_B479_MY17_Gas_Rx" SG_ 1073 SteWhlHeat_D_Rq 1;
BA_ "U_U611_U625_MY20_Hev_Rx" SG_ 1073 SteWhlHeat_D_Rq 1;
BA_ "U_U611_U625_MY20_Gas_Rx" SG_ 1073 SteWhlHeat_D_Rq 1;
BA_ "U_U611_U625_MY20_Diesel_Rx" SG_ 1073 SteWhlHeat_D_Rq 1;
BA_ "GenSigSendType" SG_ 1073 SteWhlHeat_D_Rq 3;
BA_ "U_C519_MY18_5_Gas_Tx" SG_ 1092 TbsLamp_D_RqDsply 1;
BA_ "U_B515_MCA_MY17_Gas_Tx" SG_ 1092 TbsLamp_D_RqDsply 1;
BA_ "GenSigSendType" SG_ 1092 TbsLamp_D_RqDsply 3;
BA_ "U_C519_MY18_5_Gas_Rx" SG_ 1876 TesterPhysicalReqTCU 1;
BA_ "U_B515_MCA_MY17_Gas_Rx" SG_ 1876 TesterPhysicalReqTCU 1;
BA_ "GenSigSendType" SG_ 1876 TesterPhysicalReqTCU 3;
BA_ "U_C519_MY18_5_Gas_Tx" SG_ 1884 TesterPhysicalResTCU 1;
BA_ "U_B515_MCA_MY17_Gas_Tx" SG_ 1884 TesterPhysicalResTCU 1;
BA_ "GenSigSendType" SG_ 1884 TesterPhysicalResTCU 3;
BA_ "U_CX482_CX483_MY20_Hev_Rx" SG_ 71 immoTarget1Status 1;
BA_ "U_CX482_CX483_MY20_Gas_Rx" SG_ 71 immoTarget1Status 1;
BA_ "U_CX482_CX483_MY20_Diesel_Rx" SG_ 71 immoTarget1Status 1;
BA_ "U_B500_MY18_Diesel_Rx" SG_ 71 immoTarget1Status 1;
BA_ "U_B500_MY18_Gas_Rx" SG_ 71 immoTarget1Status 1;
BA_ "U_C490_MY18_Rx" SG_ 71 immoTarget1Status 1;
BA_ "U_B562_MY18_Gas_Rx" SG_ 71 immoTarget1Status 1;
BA_ "U_C519_MY18_5_Gas_Rx" SG_ 71 immoTarget1Status 1;
BA_ "U_C519_MY18_5_Diesel_Rx" SG_ 71 immoTarget1Status 1;
BA_ "U_B515_MCA_MY17_Gas_Rx" SG_ 71 immoTarget1Status 1;
BA_ "U_B515_MCA_MY17_Diesel_Rx" SG_ 71 immoTarget1Status 1;
BA_ "U_B479_MY17_Diesel_Rx" SG_ 71 immoTarget1Status 1;
BA_ "U_B479_MY17_Gas_Rx" SG_ 71 immoTarget1Status 1;
BA_ "U_CX482_CX483_MY20_Hev_Rx" SG_ 71 immoTarget1Data 1;
BA_ "U_CX482_CX483_MY20_Gas_Rx" SG_ 71 immoTarget1Data 1;
BA_ "U_CX482_CX483_MY20_Diesel_Rx" SG_ 71 immoTarget1Data 1;
BA_ "U_B500_MY18_Diesel_Rx" SG_ 71 immoTarget1Data 1;
BA_ "U_B500_MY18_Gas_Rx" SG_ 71 immoTarget1Data 1;
BA_ "U_C490_MY18_Rx" SG_ 71 immoTarget1Data 1;
BA_ "U_B562_MY18_Gas_Rx" SG_ 71 immoTarget1Data 1;
BA_ "U_C519_MY18_5_Gas_Rx" SG_ 71 immoTarget1Data 1;
BA_ "U_C519_MY18_5_Diesel_Rx" SG_ 71 immoTarget1Data 1;
BA_ "U_B515_MCA_MY17_Gas_Rx" SG_ 71 immoTarget1Data 1;
BA_ "U_B515_MCA_MY17_Diesel_Rx" SG_ 71 immoTarget1Data 1;
BA_ "U_B479_MY17_Diesel_Rx" SG_ 71 immoTarget1Data 1;
BA_ "U_B479_MY17_Gas_Rx" SG_ 71 immoTarget1Data 1;
BA_ "U_CX482_CX483_MY20_Hev_Rx" SG_ 71 immoTarget1Cmd 1;
BA_ "U_CX482_CX483_MY20_Gas_Rx" SG_ 71 immoTarget1Cmd 1;
BA_ "U_CX482_CX483_MY20_Diesel_Rx" SG_ 71 immoTarget1Cmd 1;
BA_ "U_B500_MY18_Diesel_Rx" SG_ 71 immoTarget1Cmd 1;
BA_ "U_B500_MY18_Gas_Rx" SG_ 71 immoTarget1Cmd 1;
BA_ "U_C490_MY18_Rx" SG_ 71 immoTarget1Cmd 1;
BA_ "U_B562_MY18_Gas_Rx" SG_ 71 immoTarget1Cmd 1;
BA_ "U_C519_MY18_5_Gas_Rx" SG_ 71 immoTarget1Cmd 1;
BA_ "U_C519_MY18_5_Diesel_Rx" SG_ 71 immoTarget1Cmd 1;
BA_ "U_B515_MCA_MY17_Gas_Rx" SG_ 71 immoTarget1Cmd 1;
BA_ "U_B515_MCA_MY17_Diesel_Rx" SG_ 71 immoTarget1Cmd 1;
BA_ "U_B479_MY17_Diesel_Rx" SG_ 71 immoTarget1Cmd 1;
BA_ "U_B479_MY17_Gas_Rx" SG_ 71 immoTarget1Cmd 1;
BA_ "U_CX482_CX483_MY20_Hev_Tx" SG_ 973 TsrVl2PrmntMsgTxt_D_Rq 1;
BA_ "U_CX482_CX483_MY20_Gas_Tx" SG_ 973 TsrVl2PrmntMsgTxt_D_Rq 1;
BA_ "U_CX482_CX483_MY20_Diesel_Tx" SG_ 973 TsrVl2PrmntMsgTxt_D_Rq 1;
BA_ "U_U611_U625_MY20_Diesel_Tx" SG_ 973 TsrVl2PrmntMsgTxt_D_Rq 1;
BA_ "U_C519_MY18_5_Gas_Tx" SG_ 973 TsrVl2PrmntMsgTxt_D_Rq 1;
BA_ "U_C519_MY18_5_Diesel_Tx" SG_ 973 TsrVl2PrmntMsgTxt_D_Rq 1;
BA_ "U_B479_MY17_Diesel_Tx" SG_ 973 TsrVl2PrmntMsgTxt_D_Rq 1;
BA_ "U_B479_MY17_Gas_Tx" SG_ 973 TsrVl2PrmntMsgTxt_D_Rq 1;
BA_ "GenSigSendType" SG_ 973 TsrVl2PrmntMsgTxt_D_Rq 3;
BA_ "U_CX482_CX483_MY20_Hev_Tx" SG_ 973 TsrVl1PrmntMsgTxt_D_Rq 1;
BA_ "U_CX482_CX483_MY20_Gas_Tx" SG_ 973 TsrVl1PrmntMsgTxt_D_Rq 1;
BA_ "U_CX482_CX483_MY20_Diesel_Tx" SG_ 973 TsrVl1PrmntMsgTxt_D_Rq 1;
BA_ "U_U611_U625_MY20_Diesel_Tx" SG_ 973 TsrVl1PrmntMsgTxt_D_Rq 1;
BA_ "U_C519_MY18_5_Gas_Tx" SG_ 973 TsrVl1PrmntMsgTxt_D_Rq 1;
BA_ "U_C519_MY18_5_Diesel_Tx" SG_ 973 TsrVl1PrmntMsgTxt_D_Rq 1;
BA_ "U_B479_MY17_Diesel_Tx" SG_ 973 TsrVl1PrmntMsgTxt_D_Rq 1;
BA_ "U_B479_MY17_Gas_Tx" SG_ 973 TsrVl1PrmntMsgTxt_D_Rq 1;
BA_ "GenSigSendType" SG_ 973 TsrVl1PrmntMsgTxt_D_Rq 3;
BA_ "U_CX482_CX483_MY20_Hev_Tx" SG_ 973 TsrVl2RstrcMsgTxt2_D_Rq 1;
BA_ "U_CX482_CX483_MY20_Gas_Tx" SG_ 973 TsrVl2RstrcMsgTxt2_D_Rq 1;
BA_ "U_CX482_CX483_MY20_Diesel_Tx" SG_ 973 TsrVl2RstrcMsgTxt2_D_Rq 1;
BA_ "U_U611_U625_MY20_Diesel_Tx" SG_ 973 TsrVl2RstrcMsgTxt2_D_Rq 1;
BA_ "U_C519_MY18_5_Gas_Tx" SG_ 973 TsrVl2RstrcMsgTxt2_D_Rq 1;
BA_ "U_C519_MY18_5_Diesel_Tx" SG_ 973 TsrVl2RstrcMsgTxt2_D_Rq 1;
BA_ "U_B479_MY17_Diesel_Tx" SG_ 973 TsrVl2RstrcMsgTxt2_D_Rq 1;
BA_ "U_B479_MY17_Gas_Tx" SG_ 973 TsrVl2RstrcMsgTxt2_D_Rq 1;
BA_ "GenSigSendType" SG_ 973 TsrVl2RstrcMsgTxt2_D_Rq 3;
BA_ "GenSigStartValue" SG_ 973 TsrVl2RstrcMsgTxt2_D_Rq 1;
BA_ "U_CX482_CX483_MY20_Hev_Tx" SG_ 973 TsrVl1RstrcMsgTxt2_D_Rq 1;
BA_ "U_CX482_CX483_MY20_Gas_Tx" SG_ 973 TsrVl1RstrcMsgTxt2_D_Rq 1;
BA_ "U_CX482_CX483_MY20_Diesel_Tx" SG_ 973 TsrVl1RstrcMsgTxt2_D_Rq 1;
BA_ "U_U611_U625_MY20_Diesel_Tx" SG_ 973 TsrVl1RstrcMsgTxt2_D_Rq 1;
BA_ "U_C519_MY18_5_Gas_Tx" SG_ 973 TsrVl1RstrcMsgTxt2_D_Rq 1;
BA_ "U_C519_MY18_5_Diesel_Tx" SG_ 973 TsrVl1RstrcMsgTxt2_D_Rq 1;
BA_ "U_B479_MY17_Diesel_Tx" SG_ 973 TsrVl1RstrcMsgTxt2_D_Rq 1;
BA_ "U_B479_MY17_Gas_Tx" SG_ 973 TsrVl1RstrcMsgTxt2_D_Rq 1;
BA_ "GenSigSendType" SG_ 973 TsrVl1RstrcMsgTxt2_D_Rq 3;
BA_ "GenSigStartValue" SG_ 973 TsrVl1RstrcMsgTxt2_D_Rq 1;
BA_ "U_CX482_CX483_MY20_Hev_Tx" SG_ 973 TsrOvtkMsgTxt2_D_Rq 1;
BA_ "U_CX482_CX483_MY20_Gas_Tx" SG_ 973 TsrOvtkMsgTxt2_D_Rq 1;
BA_ "U_CX482_CX483_MY20_Diesel_Tx" SG_ 973 TsrOvtkMsgTxt2_D_Rq 1;
BA_ "U_U611_U625_MY20_Hev_Tx" SG_ 973 TsrOvtkMsgTxt2_D_Rq 1;
BA_ "U_U611_U625_MY20_Gas_Tx" SG_ 973 TsrOvtkMsgTxt2_D_Rq 1;
BA_ "U_U611_U625_MY20_Diesel_Tx" SG_ 973 TsrOvtkMsgTxt2_D_Rq 1;
BA_ "U_C519_MY18_5_Gas_Tx" SG_ 973 TsrOvtkMsgTxt2_D_Rq 1;
BA_ "U_C519_MY18_5_Diesel_Tx" SG_ 973 TsrOvtkMsgTxt2_D_Rq 1;
BA_ "U_B479_MY17_Diesel_Tx" SG_ 973 TsrOvtkMsgTxt2_D_Rq 1;
BA_ "U_B479_MY17_Gas_Tx" SG_ 973 TsrOvtkMsgTxt2_D_Rq 1;
BA_ "GenSigSendType" SG_ 973 TsrOvtkMsgTxt2_D_Rq 3;
BA_ "U_CX482_CX483_MY20_Hev_Tx" SG_ 973 WwaWarn_B_Rq 1;
BA_ "U_CX482_CX483_MY20_Gas_Tx" SG_ 973 WwaWarn_B_Rq 1;
BA_ "U_CX482_CX483_MY20_Diesel_Tx" SG_ 973 WwaWarn_B_Rq 1;
BA_ "U_U611_U625_MY20_Diesel_Tx" SG_ 973 WwaWarn_B_Rq 1;
BA_ "U_C519_MY18_5_Gas_Tx" SG_ 973 WwaWarn_B_Rq 1;
BA_ "U_C519_MY18_5_Diesel_Tx" SG_ 973 WwaWarn_B_Rq 1;
BA_ "GenSigSendType" SG_ 973 WwaWarn_B_Rq 3;
BA_ "U_CX482_CX483_MY20_Hev_Tx" SG_ 973 TsrVlUnitMsgTxt_D_Rq 1;
BA_ "U_CX482_CX483_MY20_Gas_Tx" SG_ 973 TsrVlUnitMsgTxt_D_Rq 1;
BA_ "U_CX482_CX483_MY20_Diesel_Tx" SG_ 973 TsrVlUnitMsgTxt_D_Rq 1;
BA_ "U_U611_U625_MY20_Diesel_Tx" SG_ 973 TsrVlUnitMsgTxt_D_Rq 1;
BA_ "U_C519_MY18_5_Gas_Tx" SG_ 973 TsrVlUnitMsgTxt_D_Rq 1;
BA_ "U_C519_MY18_5_Diesel_Tx" SG_ 973 TsrVlUnitMsgTxt_D_Rq 1;
BA_ "U_B479_MY17_Diesel_Tx" SG_ 973 TsrVlUnitMsgTxt_D_Rq 1;
BA_ "U_B479_MY17_Gas_Tx" SG_ 973 TsrVlUnitMsgTxt_D_Rq 1;
BA_ "GenSigSendType" SG_ 973 TsrVlUnitMsgTxt_D_Rq 3;
BA_ "GenSigStartValue" SG_ 973 TsrVlUnitMsgTxt_D_Rq 2;
BA_ "CrossOver_InfoCAN" SG_ 973 TsrVlUnitMsgTxt_D_Rq 1;
BA_ "U_CX482_CX483_MY20_Hev_Tx" SG_ 973 TsrVLim2MsgTxt_D_Rq 1;
BA_ "U_CX482_CX483_MY20_Gas_Tx" SG_ 973 TsrVLim2MsgTxt_D_Rq 1;
BA_ "U_CX482_CX483_MY20_Diesel_Tx" SG_ 973 TsrVLim2MsgTxt_D_Rq 1;
BA_ "U_U611_U625_MY20_Diesel_Tx" SG_ 973 TsrVLim2MsgTxt_D_Rq 1;
BA_ "U_C519_MY18_5_Gas_Tx" SG_ 973 TsrVLim2MsgTxt_D_Rq 1;
BA_ "U_C519_MY18_5_Diesel_Tx" SG_ 973 TsrVLim2MsgTxt_D_Rq 1;
BA_ "U_B479_MY17_Diesel_Tx" SG_ 973 TsrVLim2MsgTxt_D_Rq 1;
BA_ "U_B479_MY17_Gas_Tx" SG_ 973 TsrVLim2MsgTxt_D_Rq 1;
BA_ "GenSigSendType" SG_ 973 TsrVLim2MsgTxt_D_Rq 3;
BA_ "GenSigStartValue" SG_ 973 TsrVLim2MsgTxt_D_Rq 255;
BA_ "CrossOver_InfoCAN" SG_ 973 TsrVLim2MsgTxt_D_Rq 1;
BA_ "U_CX482_CX483_MY20_Hev_Tx" SG_ 973 TsrVLim1MsgTxt_D_Rq 1;
BA_ "U_CX482_CX483_MY20_Gas_Tx" SG_ 973 TsrVLim1MsgTxt_D_Rq 1;
BA_ "U_CX482_CX483_MY20_Diesel_Tx" SG_ 973 TsrVLim1MsgTxt_D_Rq 1;
BA_ "U_U611_U625_MY20_Diesel_Tx" SG_ 973 TsrVLim1MsgTxt_D_Rq 1;
BA_ "U_C519_MY18_5_Gas_Tx" SG_ 973 TsrVLim1MsgTxt_D_Rq 1;
BA_ "U_C519_MY18_5_Diesel_Tx" SG_ 973 TsrVLim1MsgTxt_D_Rq 1;
BA_ "U_B479_MY17_Diesel_Tx" SG_ 973 TsrVLim1MsgTxt_D_Rq 1;
BA_ "U_B479_MY17_Gas_Tx" SG_ 973 TsrVLim1MsgTxt_D_Rq 1;
BA_ "GenSigSendType" SG_ 973 TsrVLim1MsgTxt_D_Rq 3;
BA_ "GenSigStartValue" SG_ 973 TsrVLim1MsgTxt_D_Rq 255;
BA_ "CrossOver_InfoCAN" SG_ 973 TsrVLim1MsgTxt_D_Rq 1;
BA_ "GenSigSendType" SG_ 973 TsrVl2TypeMsgTxt_D_Rq 3;
BA_ "CrossOver_InfoCAN" SG_ 973 TsrVl2TypeMsgTxt_D_Rq 1;
BA_ "U_CX482_CX483_MY20_Hev_Tx" SG_ 973 TsrVl2StatMsgTxt_D_Rq 1;
BA_ "U_CX482_CX483_MY20_Gas_Tx" SG_ 973 TsrVl2StatMsgTxt_D_Rq 1;
BA_ "U_CX482_CX483_MY20_Diesel_Tx" SG_ 973 TsrVl2StatMsgTxt_D_Rq 1;
BA_ "U_U611_U625_MY20_Diesel_Tx" SG_ 973 TsrVl2StatMsgTxt_D_Rq 1;
BA_ "U_C519_MY18_5_Gas_Tx" SG_ 973 TsrVl2StatMsgTxt_D_Rq 1;
BA_ "U_C519_MY18_5_Diesel_Tx" SG_ 973 TsrVl2StatMsgTxt_D_Rq 1;
BA_ "U_B479_MY17_Diesel_Tx" SG_ 973 TsrVl2StatMsgTxt_D_Rq 1;
BA_ "U_B479_MY17_Gas_Tx" SG_ 973 TsrVl2StatMsgTxt_D_Rq 1;
BA_ "GenSigSendType" SG_ 973 TsrVl2StatMsgTxt_D_Rq 3;
BA_ "CrossOver_InfoCAN" SG_ 973 TsrVl2StatMsgTxt_D_Rq 1;
BA_ "GenSigSendType" SG_ 973 TsrVl2RstrcMsgTxt_D_Rq 3;
BA_ "CrossOver_InfoCAN" SG_ 973 TsrVl2RstrcMsgTxt_D_Rq 1;
BA_ "GenSigSendType" SG_ 973 TsrVl1TypeMsgTxt_D_Rq 3;
BA_ "CrossOver_InfoCAN" SG_ 973 TsrVl1TypeMsgTxt_D_Rq 1;
BA_ "U_CX482_CX483_MY20_Hev_Tx" SG_ 973 TsrVl1StatMsgTxt_D_Rq 1;
BA_ "U_CX482_CX483_MY20_Gas_Tx" SG_ 973 TsrVl1StatMsgTxt_D_Rq 1;
BA_ "U_CX482_CX483_MY20_Diesel_Tx" SG_ 973 TsrVl1StatMsgTxt_D_Rq 1;
BA_ "U_U611_U625_MY20_Diesel_Tx" SG_ 973 TsrVl1StatMsgTxt_D_Rq 1;
BA_ "U_C519_MY18_5_Gas_Tx" SG_ 973 TsrVl1StatMsgTxt_D_Rq 1;
BA_ "U_C519_MY18_5_Diesel_Tx" SG_ 973 TsrVl1StatMsgTxt_D_Rq 1;
BA_ "U_B479_MY17_Diesel_Tx" SG_ 973 TsrVl1StatMsgTxt_D_Rq 1;
BA_ "U_B479_MY17_Gas_Tx" SG_ 973 TsrVl1StatMsgTxt_D_Rq 1;
BA_ "GenSigSendType" SG_ 973 TsrVl1StatMsgTxt_D_Rq 3;
BA_ "CrossOver_InfoCAN" SG_ 973 TsrVl1StatMsgTxt_D_Rq 1;
BA_ "GenSigSendType" SG_ 973 TsrVl1RstrcMsgTxt_D_Rq 3;
BA_ "CrossOver_InfoCAN" SG_ 973 TsrVl1RstrcMsgTxt_D_Rq 1;
BA_ "U_CX482_CX483_MY20_Hev_Tx" SG_ 973 TsrStatMsgTxt_D_Rq 1;
BA_ "U_CX482_CX483_MY20_Gas_Tx" SG_ 973 TsrStatMsgTxt_D_Rq 1;
BA_ "U_CX482_CX483_MY20_Diesel_Tx" SG_ 973 TsrStatMsgTxt_D_Rq 1;
BA_ "U_U611_U625_MY20_Diesel_Tx" SG_ 973 TsrStatMsgTxt_D_Rq 1;
BA_ "U_C519_MY18_5_Gas_Tx" SG_ 973 TsrStatMsgTxt_D_Rq 1;
BA_ "U_C519_MY18_5_Diesel_Tx" SG_ 973 TsrStatMsgTxt_D_Rq 1;
BA_ "U_B479_MY17_Diesel_Tx" SG_ 973 TsrStatMsgTxt_D_Rq 1;
BA_ "U_B479_MY17_Gas_Tx" SG_ 973 TsrStatMsgTxt_D_Rq 1;
BA_ "GenSigSendType" SG_ 973 TsrStatMsgTxt_D_Rq 3;
BA_ "CrossOver_InfoCAN" SG_ 973 TsrStatMsgTxt_D_Rq 1;
BA_ "GenSigSendType" SG_ 973 TsrOvtkTypeMsgTxt_D_Rq 3;
BA_ "CrossOver_InfoCAN" SG_ 973 TsrOvtkTypeMsgTxt_D_Rq 1;
BA_ "U_CX482_CX483_MY20_Hev_Tx" SG_ 973 TsrOvtkStatMsgTxt_D_Rq 1;
BA_ "U_CX482_CX483_MY20_Gas_Tx" SG_ 973 TsrOvtkStatMsgTxt_D_Rq 1;
BA_ "U_CX482_CX483_MY20_Diesel_Tx" SG_ 973 TsrOvtkStatMsgTxt_D_Rq 1;
BA_ "U_U611_U625_MY20_Hev_Tx" SG_ 973 TsrOvtkStatMsgTxt_D_Rq 1;
BA_ "U_U611_U625_MY20_Gas_Tx" SG_ 973 TsrOvtkStatMsgTxt_D_Rq 1;
BA_ "U_U611_U625_MY20_Diesel_Tx" SG_ 973 TsrOvtkStatMsgTxt_D_Rq 1;
BA_ "U_C519_MY18_5_Gas_Tx" SG_ 973 TsrOvtkStatMsgTxt_D_Rq 1;
BA_ "U_C519_MY18_5_Diesel_Tx" SG_ 973 TsrOvtkStatMsgTxt_D_Rq 1;
BA_ "U_B479_MY17_Diesel_Tx" SG_ 973 TsrOvtkStatMsgTxt_D_Rq 1;
BA_ "U_B479_MY17_Gas_Tx" SG_ 973 TsrOvtkStatMsgTxt_D_Rq 1;
BA_ "GenSigSendType" SG_ 973 TsrOvtkStatMsgTxt_D_Rq 3;
BA_ "CrossOver_InfoCAN" SG_ 973 TsrOvtkStatMsgTxt_D_Rq 1;
BA_ "U_CX482_CX483_MY20_Hev_Tx" SG_ 973 TsrOvtkMsgTxt_D_Rq 1;
BA_ "U_CX482_CX483_MY20_Gas_Tx" SG_ 973 TsrOvtkMsgTxt_D_Rq 1;
BA_ "U_CX482_CX483_MY20_Diesel_Tx" SG_ 973 TsrOvtkMsgTxt_D_Rq 1;
BA_ "U_U611_U625_MY20_Hev_Tx" SG_ 973 TsrOvtkMsgTxt_D_Rq 1;
BA_ "U_U611_U625_MY20_Gas_Tx" SG_ 973 TsrOvtkMsgTxt_D_Rq 1;
BA_ "U_U611_U625_MY20_Diesel_Tx" SG_ 973 TsrOvtkMsgTxt_D_Rq 1;
BA_ "U_C519_MY18_5_Gas_Tx" SG_ 973 TsrOvtkMsgTxt_D_Rq 1;
BA_ "U_C519_MY18_5_Diesel_Tx" SG_ 973 TsrOvtkMsgTxt_D_Rq 1;
BA_ "U_B479_MY17_Diesel_Tx" SG_ 973 TsrOvtkMsgTxt_D_Rq 1;
BA_ "U_B479_MY17_Gas_Tx" SG_ 973 TsrOvtkMsgTxt_D_Rq 1;
BA_ "GenSigSendType" SG_ 973 TsrOvtkMsgTxt_D_Rq 3;
BA_ "GenSigStartValue" SG_ 973 TsrOvtkMsgTxt_D_Rq 1;
BA_ "CrossOver_InfoCAN" SG_ 973 TsrOvtkMsgTxt_D_Rq 1;
BA_ "GenSigSendType" SG_ 973 TsrOswWarnMsgTxt_D_Rq 3;
BA_ "GenSigStartValue" SG_ 973 TsrOswWarnMsgTxt_D_Rq 1;
BA_ "CrossOver_InfoCAN" SG_ 973 TsrOswWarnMsgTxt_D_Rq 1;
BA_ "U_CX482_CX483_MY20_Hev_Tx" SG_ 973 TsrMsgTxt_D_Rq 1;
BA_ "U_CX482_CX483_MY20_Gas_Tx" SG_ 973 TsrMsgTxt_D_Rq 1;
BA_ "U_CX482_CX483_MY20_Diesel_Tx" SG_ 973 TsrMsgTxt_D_Rq 1;
BA_ "U_U611_U625_MY20_Hev_Tx" SG_ 973 TsrMsgTxt_D_Rq 1;
BA_ "U_U611_U625_MY20_Gas_Tx" SG_ 973 TsrMsgTxt_D_Rq 1;
BA_ "U_U611_U625_MY20_Diesel_Tx" SG_ 973 TsrMsgTxt_D_Rq 1;
BA_ "U_C519_MY18_5_Gas_Tx" SG_ 973 TsrMsgTxt_D_Rq 1;
BA_ "U_C519_MY18_5_Diesel_Tx" SG_ 973 TsrMsgTxt_D_Rq 1;
BA_ "U_B479_MY17_Diesel_Tx" SG_ 973 TsrMsgTxt_D_Rq 1;
BA_ "U_B479_MY17_Gas_Tx" SG_ 973 TsrMsgTxt_D_Rq 1;
BA_ "GenSigSendType" SG_ 973 TsrMsgTxt_D_Rq 3;
BA_ "GenSigStartValue" SG_ 973 TsrMsgTxt_D_Rq 1;
BA_ "CrossOver_InfoCAN" SG_ 973 TsrMsgTxt_D_Rq 1;
BA_ "CrossOver_InfoCAN" SG_ 825 WndwFrontHeat_B_Rq 1;
BA_ "CrossOver_InfoCAN" SG_ 825 FdsmTrgRight_B_Actl 1;
BA_ "CrossOver_InfoCAN" SG_ 825 FdsmTrgLeft_B_Actl 1;
BA_ "CrossOver_InfoCAN" SG_ 825 FdsmTrgDist_L_Actl 1;
BA_ "CrossOver_InfoCAN" SG_ 825 FdsmTrgCntr_B_Actl 1;
BA_ "CrossOver_InfoCAN" SG_ 825 LscmbbSrvcRqd_B_Rq 1;
BA_ "CrossOver_InfoCAN" SG_ 825 LscmbbPostEvnt_B_Dsply 1;
BA_ "U_U611_U625_MY20_Hev_Rx" SG_ 825 LscmbbEngTqMn_B_Rq 1;
BA_ "U_U611_U625_MY20_Gas_Rx" SG_ 825 LscmbbEngTqMn_B_Rq 1;
BA_ "U_U611_U625_MY20_Diesel_Rx" SG_ 825 LscmbbEngTqMn_B_Rq 1;
BA_ "CrossOver_InfoCAN" SG_ 825 LscmbbEngTqMn_B_Rq 1;
BA_ "CrossOver_InfoCAN" SG_ 825 LscmbbMsgTxt_D_Rq 1;
BA_ "U_U611_U625_MY20_Hev_Rx" SG_ 825 LscmbbDeny_B_Actl 1;
BA_ "U_U611_U625_MY20_Gas_Rx" SG_ 825 LscmbbDeny_B_Actl 1;
BA_ "U_U611_U625_MY20_Diesel_Rx" SG_ 825 LscmbbDeny_B_Actl 1;
BA_ "CrossOver_InfoCAN" SG_ 825 LscmbbDeny_B_Actl 1;
BA_ "U_U611_U625_MY20_Hev_Rx" SG_ 825 LscmbbBrkPrchg_D_Rq 1;
BA_ "U_U611_U625_MY20_Gas_Rx" SG_ 825 LscmbbBrkPrchg_D_Rq 1;
BA_ "U_U611_U625_MY20_Diesel_Rx" SG_ 825 LscmbbBrkPrchg_D_Rq 1;
BA_ "CrossOver_InfoCAN" SG_ 825 LscmbbBrkPrchg_D_Rq 1;
BA_ "U_U611_U625_MY20_Hev_Rx" SG_ 825 LscmbbBrkDecel_No_Cs 1;
BA_ "U_U611_U625_MY20_Gas_Rx" SG_ 825 LscmbbBrkDecel_No_Cs 1;
BA_ "U_U611_U625_MY20_Diesel_Rx" SG_ 825 LscmbbBrkDecel_No_Cs 1;
BA_ "CrossOver_InfoCAN" SG_ 825 LscmbbBrkDecel_No_Cs 1;
BA_ "U_U611_U625_MY20_Hev_Rx" SG_ 825 LscmbbBrkDecel_No_Cnt 1;
BA_ "U_U611_U625_MY20_Gas_Rx" SG_ 825 LscmbbBrkDecel_No_Cnt 1;
BA_ "U_U611_U625_MY20_Diesel_Rx" SG_ 825 LscmbbBrkDecel_No_Cnt 1;
BA_ "CrossOver_InfoCAN" SG_ 825 LscmbbBrkDecel_No_Cnt 1;
BA_ "U_U611_U625_MY20_Hev_Rx" SG_ 825 LscmbbBrkDecel_B_Enbl 1;
BA_ "U_U611_U625_MY20_Gas_Rx" SG_ 825 LscmbbBrkDecel_B_Enbl 1;
BA_ "U_U611_U625_MY20_Diesel_Rx" SG_ 825 LscmbbBrkDecel_B_Enbl 1;
BA_ "CrossOver_InfoCAN" SG_ 825 LscmbbBrkDecel_B_Enbl 1;
BA_ "U_U611_U625_MY20_Hev_Rx" SG_ 825 LscmbbBrkDecel_A_Rq 1;
BA_ "U_U611_U625_MY20_Gas_Rx" SG_ 825 LscmbbBrkDecel_A_Rq 1;
BA_ "U_U611_U625_MY20_Diesel_Rx" SG_ 825 LscmbbBrkDecel_A_Rq 1;
BA_ "GenSigStartValue" SG_ 825 LscmbbBrkDecel_A_Rq 255;
BA_ "CrossOver_InfoCAN" SG_ 825 LscmbbBlck_B_Actl 1;
BA_ "U_U611_U625_MY20_Hev_Rx" SG_ 825 LscmbbBaSens_D_Rq 1;
BA_ "U_U611_U625_MY20_Gas_Rx" SG_ 825 LscmbbBaSens_D_Rq 1;
BA_ "U_U611_U625_MY20_Diesel_Rx" SG_ 825 LscmbbBaSens_D_Rq 1;
BA_ "CrossOver_InfoCAN" SG_ 825 LscmbbBaSens_D_Rq 1;
BA_ "GenSigSendType" SG_ 837 SuspVLim_B_Rq 3;
BA_ "U_U611_U625_MY20_Phev_Tx" SG_ 837 SelDrvMdeSusp_D_Stat 1;
BA_ "U_U611_U625_MY20_Hev_Tx" SG_ 837 SelDrvMdeSusp_D_Stat 1;
BA_ "U_U611_U625_MY20_Gas_Tx" SG_ 837 SelDrvMdeSusp_D_Stat 1;
BA_ "U_U611_U625_MY20_Diesel_Tx" SG_ 837 SelDrvMdeSusp_D_Stat 1;
BA_ "U_C519_MY18_5_Gas_Tx" SG_ 837 SelDrvMdeSusp_D_Stat 1;
BA_ "U_C519_MY18_5_Diesel_Tx" SG_ 837 SelDrvMdeSusp_D_Stat 1;
BA_ "U_CX482_CX483_MY20_Hev_Rx" SG_ 837 SelDrvMdeSusp_D_Stat 1;
BA_ "U_CX482_CX483_MY20_Gas_Rx" SG_ 837 SelDrvMdeSusp_D_Stat 1;
BA_ "U_CX482_CX483_MY20_Diesel_Rx" SG_ 837 SelDrvMdeSusp_D_Stat 1;
BA_ "U_U611_U625_MY20_Hev_Rx" SG_ 837 SelDrvMdeSusp_D_Stat 1;
BA_ "U_U611_U625_MY20_Gas_Rx" SG_ 837 SelDrvMdeSusp_D_Stat 1;
BA_ "U_U611_U625_MY20_Diesel_Rx" SG_ 837 SelDrvMdeSusp_D_Stat 1;
BA_ "U_C519_MY18_5_Gas_Rx" SG_ 837 SelDrvMdeSusp_D_Stat 1;
BA_ "U_C519_MY18_5_Diesel_Rx" SG_ 837 SelDrvMdeSusp_D_Stat 1;
BA_ "GenSigSendType" SG_ 837 SelDrvMdeSusp_D_Stat 3;
BA_ "U_U611_U625_MY20_Phev_Tx" SG_ 837 AdptDrvMdePt_D_Rq 1;
BA_ "U_U611_U625_MY20_Hev_Tx" SG_ 837 AdptDrvMdePt_D_Rq 1;
BA_ "U_U611_U625_MY20_Gas_Tx" SG_ 837 AdptDrvMdePt_D_Rq 1;
BA_ "U_U611_U625_MY20_Diesel_Tx" SG_ 837 AdptDrvMdePt_D_Rq 1;
BA_ "U_C519_MY18_5_Gas_Tx" SG_ 837 AdptDrvMdePt_D_Rq 1;
BA_ "U_C519_MY18_5_Diesel_Tx" SG_ 837 AdptDrvMdePt_D_Rq 1;
BA_ "U_CX482_CX483_MY20_Hev_Rx" SG_ 837 AdptDrvMdePt_D_Rq 1;
BA_ "U_CX482_CX483_MY20_Gas_Rx" SG_ 837 AdptDrvMdePt_D_Rq 1;
BA_ "U_CX482_CX483_MY20_Diesel_Rx" SG_ 837 AdptDrvMdePt_D_Rq 1;
BA_ "U_U611_U625_MY20_Hev_Rx" SG_ 837 AdptDrvMdePt_D_Rq 1;
BA_ "U_U611_U625_MY20_Gas_Rx" SG_ 837 AdptDrvMdePt_D_Rq 1;
BA_ "U_U611_U625_MY20_Diesel_Rx" SG_ 837 AdptDrvMdePt_D_Rq 1;
BA_ "U_C519_MY18_5_Gas_Rx" SG_ 837 AdptDrvMdePt_D_Rq 1;
BA_ "U_C519_MY18_5_Diesel_Rx" SG_ 837 AdptDrvMdePt_D_Rq 1;
BA_ "GenSigSendType" SG_ 837 AdptDrvMdePt_D_Rq 3;
BA_ "U_U611_U625_MY20_Phev_Tx" SG_ 837 AdptDrvMdeChassis_D_Rq 1;
BA_ "U_U611_U625_MY20_Hev_Tx" SG_ 837 AdptDrvMdeChassis_D_Rq 1;
BA_ "U_U611_U625_MY20_Gas_Tx" SG_ 837 AdptDrvMdeChassis_D_Rq 1;
BA_ "U_U611_U625_MY20_Diesel_Tx" SG_ 837 AdptDrvMdeChassis_D_Rq 1;
BA_ "U_C519_MY18_5_Gas_Tx" SG_ 837 AdptDrvMdeChassis_D_Rq 1;
BA_ "U_C519_MY18_5_Diesel_Tx" SG_ 837 AdptDrvMdeChassis_D_Rq 1;
BA_ "U_CX482_CX483_MY20_Hev_Rx" SG_ 837 AdptDrvMdeChassis_D_Rq 1;
BA_ "U_CX482_CX483_MY20_Gas_Rx" SG_ 837 AdptDrvMdeChassis_D_Rq 1;
BA_ "U_CX482_CX483_MY20_Diesel_Rx" SG_ 837 AdptDrvMdeChassis_D_Rq 1;
BA_ "U_U611_U625_MY20_Hev_Rx" SG_ 837 AdptDrvMdeChassis_D_Rq 1;
BA_ "U_U611_U625_MY20_Gas_Rx" SG_ 837 AdptDrvMdeChassis_D_Rq 1;
BA_ "U_U611_U625_MY20_Diesel_Rx" SG_ 837 AdptDrvMdeChassis_D_Rq 1;
BA_ "U_C519_MY18_5_Gas_Rx" SG_ 837 AdptDrvMdeChassis_D_Rq 1;
BA_ "U_C519_MY18_5_Diesel_Rx" SG_ 837 AdptDrvMdeChassis_D_Rq 1;
BA_ "GenSigSendType" SG_ 837 AdptDrvMdeChassis_D_Rq 3;
BA_ "U_U611_U625_MY20_Phev_Tx" SG_ 837 AirSprngRateRr_D_Rq 1;
BA_ "U_U611_U625_MY20_Hev_Tx" SG_ 837 AirSprngRateRr_D_Rq 1;
BA_ "U_U611_U625_MY20_Gas_Tx" SG_ 837 AirSprngRateRr_D_Rq 1;
BA_ "U_U611_U625_MY20_Diesel_Tx" SG_ 837 AirSprngRateRr_D_Rq 1;
BA_ "GenSigSendType" SG_ 837 AirSprngRateRr_D_Rq 3;
BA_ "U_U611_U625_MY20_Phev_Tx" SG_ 837 AirSprngRateRl_D_Rq 1;
BA_ "U_U611_U625_MY20_Hev_Tx" SG_ 837 AirSprngRateRl_D_Rq 1;
BA_ "U_U611_U625_MY20_Gas_Tx" SG_ 837 AirSprngRateRl_D_Rq 1;
BA_ "U_U611_U625_MY20_Diesel_Tx" SG_ 837 AirSprngRateRl_D_Rq 1;
BA_ "GenSigSendType" SG_ 837 AirSprngRateRl_D_Rq 3;
BA_ "U_U611_U625_MY20_Phev_Tx" SG_ 837 AirSprngRateFr_D_Rq 1;
BA_ "U_U611_U625_MY20_Hev_Tx" SG_ 837 AirSprngRateFr_D_Rq 1;
BA_ "U_U611_U625_MY20_Gas_Tx" SG_ 837 AirSprngRateFr_D_Rq 1;
BA_ "U_U611_U625_MY20_Diesel_Tx" SG_ 837 AirSprngRateFr_D_Rq 1;
BA_ "GenSigSendType" SG_ 837 AirSprngRateFr_D_Rq 3;
BA_ "U_U611_U625_MY20_Phev_Tx" SG_ 837 AirSprngRateFl_D_Rq 1;
BA_ "U_U611_U625_MY20_Hev_Tx" SG_ 837 AirSprngRateFl_D_Rq 1;
BA_ "U_U611_U625_MY20_Gas_Tx" SG_ 837 AirSprngRateFl_D_Rq 1;
BA_ "U_U611_U625_MY20_Diesel_Tx" SG_ 837 AirSprngRateFl_D_Rq 1;
BA_ "GenSigSendType" SG_ 837 AirSprngRateFl_D_Rq 3;
BA_ "U_CX482_CX483_MY20_Hev_Tx" SG_ 837 BrkPadMsgTxt_D_Rq 1;
BA_ "U_CX482_CX483_MY20_Gas_Tx" SG_ 837 BrkPadMsgTxt_D_Rq 1;
BA_ "U_CX482_CX483_MY20_Diesel_Tx" SG_ 837 BrkPadMsgTxt_D_Rq 1;
BA_ "U_C519_MY18_5_Gas_Tx" SG_ 837 BrkPadMsgTxt_D_Rq 1;
BA_ "U_C519_MY18_5_Diesel_Tx" SG_ 837 BrkPadMsgTxt_D_Rq 1;
BA_ "GenSigSendType" SG_ 837 BrkPadMsgTxt_D_Rq 3;
BA_ "GenSigSendType" SG_ 837 AirSusp_D_Stat 3;
BA_ "GenSigSendType" SG_ 837 AirSuspMsgTxt_D_Rq 3;
BA_ "GenSigSendType" SG_ 837 SuspDrvMde_D_Stat 3;
BA_ "U_U611_U625_MY20_Hev_Tx" SG_ 837 CcdMsgTxt_D_RqDsply 1;
BA_ "U_U611_U625_MY20_Gas_Tx" SG_ 837 CcdMsgTxt_D_RqDsply 1;
BA_ "U_U611_U625_MY20_Diesel_Tx" SG_ 837 CcdMsgTxt_D_RqDsply 1;
BA_ "U_U611_U625_MY20_Hev_Rx" SG_ 837 CcdMsgTxt_D_RqDsply 1;
BA_ "U_U611_U625_MY20_Gas_Rx" SG_ 837 CcdMsgTxt_D_RqDsply 1;
BA_ "U_U611_U625_MY20_Diesel_Rx" SG_ 837 CcdMsgTxt_D_RqDsply 1;
BA_ "U_B479_MY17_Diesel_Rx" SG_ 837 CcdMsgTxt_D_RqDsply 1;
BA_ "U_B479_MY17_Gas_Rx" SG_ 837 CcdMsgTxt_D_RqDsply 1;
BA_ "GenSigSendType" SG_ 837 CcdMsgTxt_D_RqDsply 3;
BA_ "CrossOver_InfoCAN" SG_ 837 CcdMsgTxt_D_RqDsply 1;
BA_ "CrossOver_InfoCAN" SG_ 1091 ParkLampTrlrOut_B_Stat 1;
BA_ "CrossOver_InfoCAN" SG_ 1091 StopLampTrlrOut_B_Stat 1;
BA_ "CrossOver_InfoCAN" SG_ 1091 TrlrBattChrg_D_Stat 1;
BA_ "CrossOver_InfoCAN" SG_ 1091 TrlrLampCtl_D_Stat 1;
BA_ "CrossOver_InfoCAN" SG_ 1091 TurnLampTrlrRr_B_Stat 1;
BA_ "CrossOver_InfoCAN" SG_ 1091 TurnLampTrlrRl_B_Stat 1;
BA_ "U_CX482_CX483_MY20_Hev_Rx" SG_ 1091 TrlrLampCnnct_B_Actl 1;
BA_ "U_CX482_CX483_MY20_Gas_Rx" SG_ 1091 TrlrLampCnnct_B_Actl 1;
BA_ "U_CX482_CX483_MY20_Diesel_Rx" SG_ 1091 TrlrLampCnnct_B_Actl 1;
BA_ "U_C519_MY18_5_Gas_Rx" SG_ 1091 TrlrLampCnnct_B_Actl 1;
BA_ "U_C519_MY18_5_Diesel_Rx" SG_ 1091 TrlrLampCnnct_B_Actl 1;
BA_ "U_B515_MCA_MY17_Gas_Rx" SG_ 1091 TrlrLampCnnct_B_Actl 1;
BA_ "U_B515_MCA_MY17_Diesel_Rx" SG_ 1091 TrlrLampCnnct_B_Actl 1;
BA_ "U_B479_MY17_Diesel_Rx" SG_ 1091 TrlrLampCnnct_B_Actl 1;
BA_ "U_B479_MY17_Gas_Rx" SG_ 1091 TrlrLampCnnct_B_Actl 1;
BA_ "U_U611_U625_MY20_Phev_Rx" SG_ 1091 TrlrLampCnnct_B_Actl 1;
BA_ "U_U611_U625_MY20_Hev_Rx" SG_ 1091 TrlrLampCnnct_B_Actl 1;
BA_ "U_U611_U625_MY20_Gas_Rx" SG_ 1091 TrlrLampCnnct_B_Actl 1;
BA_ "U_U611_U625_MY20_Diesel_Rx" SG_ 1091 TrlrLampCnnct_B_Actl 1;
BA_ "CrossOver_InfoCAN" SG_ 1091 TrlrLampCnnct_B_Actl 1;
BA_ "GenSigSendType" SG_ 1068 EngStrtInhbt_B_RqBatt 3;
BA_ "GenSigSendType" SG_ 1068 BattULoChrg_D_Rq 3;
BA_ "U_CX482_CX483_MY20_Hev_Rx" SG_ 1068 PwSysULoFalt_D_Stat 1;
BA_ "U_CX482_CX483_MY20_Gas_Rx" SG_ 1068 PwSysULoFalt_D_Stat 1;
BA_ "U_CX482_CX483_MY20_Diesel_Rx" SG_ 1068 PwSysULoFalt_D_Stat 1;
BA_ "U_B500_MY18_Diesel_Rx" SG_ 1068 PwSysULoFalt_D_Stat 1;
BA_ "U_B500_MY18_Gas_Rx" SG_ 1068 PwSysULoFalt_D_Stat 1;
BA_ "U_C490_MY18_Rx" SG_ 1068 PwSysULoFalt_D_Stat 1;
BA_ "U_B562_MY18_Gas_Rx" SG_ 1068 PwSysULoFalt_D_Stat 1;
BA_ "U_C519_MY18_5_Gas_Rx" SG_ 1068 PwSysULoFalt_D_Stat 1;
BA_ "U_C519_MY18_5_Diesel_Rx" SG_ 1068 PwSysULoFalt_D_Stat 1;
BA_ "U_B515_MCA_MY17_Gas_Rx" SG_ 1068 PwSysULoFalt_D_Stat 1;
BA_ "U_B515_MCA_MY17_Diesel_Rx" SG_ 1068 PwSysULoFalt_D_Stat 1;
BA_ "U_B479_MY17_Diesel_Rx" SG_ 1068 PwSysULoFalt_D_Stat 1;
BA_ "U_B479_MY17_Gas_Rx" SG_ 1068 PwSysULoFalt_D_Stat 1;
BA_ "GenSigSendType" SG_ 1068 PwSysULoFalt_D_Stat 3;
BA_ "CrossOver_InfoCAN" SG_ 1068 PwSysULoFalt_D_Stat 1;
BA_ "WakeupSignal" SG_ 1068 PwSysULoFalt_D_Stat 1;
BA_ "GenSigSendType" SG_ 1068 Shed_T_Eng_Off_B 3;
BA_ "CrossOver_InfoCAN" SG_ 1068 Shed_T_Eng_Off_B 1;
BA_ "U_B515_MCA_MY17_Gas_Rx" SG_ 1068 Shed_Feature_Group_ID 1;
BA_ "U_B515_MCA_MY17_Diesel_Rx" SG_ 1068 Shed_Feature_Group_ID 1;
BA_ "GenSigSendType" SG_ 1068 Shed_Feature_Group_ID 3;
BA_ "WakeupSignal" SG_ 1068 Shed_Feature_Group_ID 1;
BA_ "GenSigSendType" SG_ 1068 Shed_Drain_Eng_Off_B 3;
BA_ "CrossOver_InfoCAN" SG_ 1068 Shed_Drain_Eng_Off_B 1;
BA_ "U_CX482_CX483_MY20_Hev_Rx" SG_ 1068 Shed_Level_Req 1;
BA_ "U_CX482_CX483_MY20_Gas_Rx" SG_ 1068 Shed_Level_Req 1;
BA_ "U_CX482_CX483_MY20_Diesel_Rx" SG_ 1068 Shed_Level_Req 1;
BA_ "U_B479_MY17_Diesel_Rx" SG_ 1068 Shed_Level_Req 1;
BA_ "U_B479_MY17_Gas_Rx" SG_ 1068 Shed_Level_Req 1;
BA_ "U_U611_U625_MY20_Phev_Rx" SG_ 1068 Shed_Level_Req 1;
BA_ "U_U611_U625_MY20_Hev_Rx" SG_ 1068 Shed_Level_Req 1;
BA_ "U_U611_U625_MY20_Gas_Rx" SG_ 1068 Shed_Level_Req 1;
BA_ "U_U611_U625_MY20_Diesel_Rx" SG_ 1068 Shed_Level_Req 1;
BA_ "U_C519_MY18_5_Gas_Rx" SG_ 1068 Shed_Level_Req 1;
BA_ "U_C519_MY18_5_Diesel_Rx" SG_ 1068 Shed_Level_Req 1;
BA_ "U_B515_MCA_MY17_Gas_Rx" SG_ 1068 Shed_Level_Req 1;
BA_ "U_B515_MCA_MY17_Diesel_Rx" SG_ 1068 Shed_Level_Req 1;
BA_ "GenSigSendType" SG_ 1068 Shed_Level_Req 3;
BA_ "CrossOver_InfoCAN" SG_ 1068 Shed_Level_Req 1;
BA_ "WakeupSignal" SG_ 1068 Shed_Level_Req 1;
BA_ "GenSigSendType" SG_ 1068 ChargeMode 3;
BA_ "GenSigSendType" SG_ 1068 IdleSpeedIncrease_El 3;
BA_ "GenSigSendType" SG_ 1068 Batt_Lo_SoC_B 3;
BA_ "CrossOver_InfoCAN" SG_ 1068 Batt_Lo_SoC_B 1;
BA_ "GenSigSendType" SG_ 1068 PeriodicElLoad_B_Stat 3;
BA_ "U_U611_U625_MY20_Phev_Rx" SG_ 1068 Batt_Crit_SoC_B 1;
BA_ "U_CX482_CX483_MY20_Hev_Rx" SG_ 1068 Batt_Crit_SoC_B 1;
BA_ "U_CX482_CX483_MY20_Gas_Rx" SG_ 1068 Batt_Crit_SoC_B 1;
BA_ "U_CX482_CX483_MY20_Diesel_Rx" SG_ 1068 Batt_Crit_SoC_B 1;
BA_ "U_U611_U625_MY20_Hev_Rx" SG_ 1068 Batt_Crit_SoC_B 1;
BA_ "U_U611_U625_MY20_Gas_Rx" SG_ 1068 Batt_Crit_SoC_B 1;
BA_ "U_U611_U625_MY20_Diesel_Rx" SG_ 1068 Batt_Crit_SoC_B 1;
BA_ "U_C519_MY18_5_Gas_Rx" SG_ 1068 Batt_Crit_SoC_B 1;
BA_ "U_C519_MY18_5_Diesel_Rx" SG_ 1068 Batt_Crit_SoC_B 1;
BA_ "GenSigSendType" SG_ 1068 Batt_Crit_SoC_B 3;
BA_ "CrossOver_InfoCAN" SG_ 1068 Batt_Crit_SoC_B 1;
BA_ "GenSigSendType" SG_ 1068 ULoRgenTestMde_B_Rq 3;
BA_ "CrossOver_InfoCAN" SG_ 611 AwdTerrMdeChng_D_Rdy 1;
BA_ "CrossOver_InfoCAN" SG_ 611 AwdTerrMde_D_Actl 1;
BA_ "U_U611_U625_MY20_Hev_Rx" SG_ 611 SelDrvMdeAwd_D_Stat 1;
BA_ "U_U611_U625_MY20_Gas_Rx" SG_ 611 SelDrvMdeAwd_D_Stat 1;
BA_ "U_U611_U625_MY20_Diesel_Rx" SG_ 611 SelDrvMdeAwd_D_Stat 1;
BA_ "U_U611_U625_MY20_Hev_Rx" SG_ 611 AwdStat_D_RqDsply 1;
BA_ "U_U611_U625_MY20_Gas_Rx" SG_ 611 AwdStat_D_RqDsply 1;
BA_ "U_U611_U625_MY20_Diesel_Rx" SG_ 611 AwdStat_D_RqDsply 1;
BA_ "ContentDependant" SG_ 611 AwdStat_D_RqDsply 1;
BA_ "CrossOver_InfoCAN" SG_ 611 AwdStat_D_RqDsply 1;
BA_ "U_U611_U625_MY20_Hev_Rx" SG_ 611 AwdLck_D_Stat 1;
BA_ "U_U611_U625_MY20_Gas_Rx" SG_ 611 AwdLck_D_Stat 1;
BA_ "U_U611_U625_MY20_Diesel_Rx" SG_ 611 AwdLck_D_Stat 1;
BA_ "U_B515_MCA_MY17_Gas_Rx" SG_ 611 AwdLck_D_Stat 1;
BA_ "U_B515_MCA_MY17_Diesel_Rx" SG_ 611 AwdLck_D_Stat 1;
BA_ "CrossOver_InfoCAN" SG_ 611 AwdLck_D_Stat 1;
BA_ "U_U611_U625_MY20_Hev_Rx" SG_ 611 AwdSrvcRqd_B_Rq 1;
BA_ "U_U611_U625_MY20_Gas_Rx" SG_ 611 AwdSrvcRqd_B_Rq 1;
BA_ "U_U611_U625_MY20_Diesel_Rx" SG_ 611 AwdSrvcRqd_B_Rq 1;
BA_ "U_B515_MCA_MY17_Gas_Rx" SG_ 611 AwdSrvcRqd_B_Rq 1;
BA_ "U_B515_MCA_MY17_Diesel_Rx" SG_ 611 AwdSrvcRqd_B_Rq 1;
BA_ "ContentDependant" SG_ 611 AwdSrvcRqd_B_Rq 1;
BA_ "CrossOver_InfoCAN" SG_ 611 AwdSrvcRqd_B_Rq 1;
BA_ "U_B515_MCA_MY17_Gas_Rx" SG_ 611 AwdLck_Tq_Rq 1;
BA_ "U_B515_MCA_MY17_Diesel_Rx" SG_ 611 AwdLck_Tq_Rq 1;
BA_ "ContentDependant" SG_ 611 AwdLck_Tq_Rq 1;
BA_ "CrossOver_InfoCAN" SG_ 611 AwdLck_Tq_Rq 1;
BA_ "GenSigStartValue" SG_ 611 TrnAout_Tq_RqMx 8191;
BA_ "CrossOver_InfoCAN" SG_ 611 TrnAout_Tq_RqMx 1;
BA_ "U_B515_MCA_MY17_Gas_Rx" SG_ 611 AwdOffRoadMode_D_Stats 1;
BA_ "U_B515_MCA_MY17_Diesel_Rx" SG_ 611 AwdOffRoadMode_D_Stats 1;
BA_ "CrossOver_InfoCAN" SG_ 611 AwdOffRoadMode_D_Stats 1;
BA_ "U_U611_U625_MY20_Hev_Rx" SG_ 611 AwdLoLamp_D_RqDsply 1;
BA_ "U_U611_U625_MY20_Gas_Rx" SG_ 611 AwdLoLamp_D_RqDsply 1;
BA_ "U_U611_U625_MY20_Diesel_Rx" SG_ 611 AwdLoLamp_D_RqDsply 1;
BA_ "CrossOver_InfoCAN" SG_ 611 AwdLoLamp_D_RqDsply 1;
BA_ "U_U611_U625_MY20_Hev_Rx" SG_ 611 AwdHiLamp_D_RqDsply 1;
BA_ "U_U611_U625_MY20_Gas_Rx" SG_ 611 AwdHiLamp_D_RqDsply 1;
BA_ "U_U611_U625_MY20_Diesel_Rx" SG_ 611 AwdHiLamp_D_RqDsply 1;
BA_ "CrossOver_InfoCAN" SG_ 611 AwdHiLamp_D_RqDsply 1;
BA_ "U_U611_U625_MY20_Hev_Rx" SG_ 611 AwdAutoLamp_D_RqDsply 1;
BA_ "U_U611_U625_MY20_Gas_Rx" SG_ 611 AwdAutoLamp_D_RqDsply 1;
BA_ "U_U611_U625_MY20_Diesel_Rx" SG_ 611 AwdAutoLamp_D_RqDsply 1;
BA_ "CrossOver_InfoCAN" SG_ 611 AwdAutoLamp_D_RqDsply 1;
BA_ "U_U611_U625_MY20_Hev_Rx" SG_ 611 Awd2wdLamp_D_RqDsply 1;
BA_ "U_U611_U625_MY20_Gas_Rx" SG_ 611 Awd2wdLamp_D_RqDsply 1;
BA_ "U_U611_U625_MY20_Diesel_Rx" SG_ 611 Awd2wdLamp_D_RqDsply 1;
BA_ "CrossOver_InfoCAN" SG_ 611 Awd2wdLamp_D_RqDsply 1;
BA_ "U_U611_U625_MY20_Hev_Rx" SG_ 611 AwdRnge_D_Actl 1;
BA_ "U_U611_U625_MY20_Gas_Rx" SG_ 611 AwdRnge_D_Actl 1;
BA_ "U_U611_U625_MY20_Diesel_Rx" SG_ 611 AwdRnge_D_Actl 1;
BA_ "U_B515_MCA_MY17_Gas_Rx" SG_ 611 AwdRnge_D_Actl 1;
BA_ "U_B515_MCA_MY17_Diesel_Rx" SG_ 611 AwdRnge_D_Actl 1;
BA_ "GenSigStartValue" SG_ 611 AwdRnge_D_Actl 7;
BA_ "CrossOver_InfoCAN" SG_ 611 AwdRnge_D_Actl 1;
BA_ "GenSigStartValue" SG_ 395 HudShifPoint_N_Rq 30;
BA_ "CrossOver_InfoCAN" SG_ 395 HudLedMde_D_Rq 1;
BA_ "GenSigSendType" SG_ 578 PtLatchActv_B_RqBcm 3;
BA_ "GenSigSendType" SG_ 578 PrkLckCtlUnlck_D_Stat 3;
BA_ "GenSigSendType" SG_ 578 PrkLckCtlTow_B_Enbl 3;
BA_ "U_U611_U625_MY20_Phev_Rx" SG_ 578 immoSecureIdleMode 1;
BA_ "U_CX482_CX483_MY20_Hev_Rx" SG_ 578 immoSecureIdleMode 1;
BA_ "U_CX482_CX483_MY20_Gas_Rx" SG_ 578 immoSecureIdleMode 1;
BA_ "U_CX482_CX483_MY20_Diesel_Rx" SG_ 578 immoSecureIdleMode 1;
BA_ "U_U611_U625_MY20_Hev_Rx" SG_ 578 immoSecureIdleMode 1;
BA_ "U_U611_U625_MY20_Gas_Rx" SG_ 578 immoSecureIdleMode 1;
BA_ "U_U611_U625_MY20_Diesel_Rx" SG_ 578 immoSecureIdleMode 1;
BA_ "U_C519_MY18_5_Gas_Rx" SG_ 578 immoSecureIdleMode 1;
BA_ "U_C519_MY18_5_Diesel_Rx" SG_ 578 immoSecureIdleMode 1;
BA_ "GenSigSendType" SG_ 578 immoSecureIdleMode 3;
BA_ "GenSigSendType" SG_ 578 FuelPumpPwr_D_Stat 3;
BA_ "U_U611_U625_MY20_Phev_Rx" SG_ 578 BattULo_U_Actl 1;
BA_ "U_CX482_CX483_MY20_Hev_Rx" SG_ 578 BattULo_U_Actl 1;
BA_ "U_CX482_CX483_MY20_Gas_Rx" SG_ 578 BattULo_U_Actl 1;
BA_ "U_CX482_CX483_MY20_Diesel_Rx" SG_ 578 BattULo_U_Actl 1;
BA_ "U_U611_U625_MY20_Hev_Rx" SG_ 578 BattULo_U_Actl 1;
BA_ "U_U611_U625_MY20_Gas_Rx" SG_ 578 BattULo_U_Actl 1;
BA_ "U_U611_U625_MY20_Diesel_Rx" SG_ 578 BattULo_U_Actl 1;
BA_ "U_B500_MY18_Diesel_Rx" SG_ 578 BattULo_U_Actl 1;
BA_ "U_B500_MY18_Gas_Rx" SG_ 578 BattULo_U_Actl 1;
BA_ "U_C490_MY18_Rx" SG_ 578 BattULo_U_Actl 1;
BA_ "U_B562_MY18_Gas_Rx" SG_ 578 BattULo_U_Actl 1;
BA_ "U_C519_MY18_5_Gas_Rx" SG_ 578 BattULo_U_Actl 1;
BA_ "U_C519_MY18_5_Diesel_Rx" SG_ 578 BattULo_U_Actl 1;
BA_ "U_B515_MCA_MY17_Gas_Rx" SG_ 578 BattULo_U_Actl 1;
BA_ "U_B515_MCA_MY17_Diesel_Rx" SG_ 578 BattULo_U_Actl 1;
BA_ "U_B479_MY17_Diesel_Rx" SG_ 578 BattULo_U_Actl 1;
BA_ "U_B479_MY17_Gas_Rx" SG_ 578 BattULo_U_Actl 1;
BA_ "GenSigStartValue" SG_ 578 BattULo_U_Actl 255;
BA_ "U_U611_U625_MY20_Phev_Rx" SG_ 578 PrkLckCtl_B_Enbl 1;
BA_ "U_CX482_CX483_MY20_Hev_Rx" SG_ 578 PrkLckCtl_B_Enbl 1;
BA_ "U_CX482_CX483_MY20_Gas_Rx" SG_ 578 PrkLckCtl_B_Enbl 1;
BA_ "U_CX482_CX483_MY20_Diesel_Rx" SG_ 578 PrkLckCtl_B_Enbl 1;
BA_ "U_U611_U625_MY20_Hev_Rx" SG_ 578 PrkLckCtl_B_Enbl 1;
BA_ "U_U611_U625_MY20_Gas_Rx" SG_ 578 PrkLckCtl_B_Enbl 1;
BA_ "U_U611_U625_MY20_Diesel_Rx" SG_ 578 PrkLckCtl_B_Enbl 1;
BA_ "U_C519_MY18_5_Gas_Rx" SG_ 578 PrkLckCtl_B_Enbl 1;
BA_ "U_C519_MY18_5_Diesel_Rx" SG_ 578 PrkLckCtl_B_Enbl 1;
BA_ "GenSigSendType" SG_ 578 PrkLckCtl_B_Enbl 3;
BA_ "CrossOver_InfoCAN" SG_ 578 PrkLckCtl_B_Enbl 1;
BA_ "GenSigSendType" SG_ 578 PrkLckCtlMsgTxt_D_Rq 3;
BA_ "CrossOver_InfoCAN" SG_ 578 PrkLckCtlMsgTxt_D_Rq 1;
BA_ "WakeupSignal" SG_ 578 PrkLckCtlMsgTxt_D_Rq 1;
BA_ "CrossOver_InfoCAN" SG_ 578 PrkLckCtlAvail_T_Stat 1;
BA_ "WakeupSignal" SG_ 578 PrkLckCtlAvail_T_Stat 1;
BA_ "U_U611_U625_MY20_Phev_Rx" SG_ 578 BrkTrnShifLck_B_Stat 1;
BA_ "U_CX482_CX483_MY20_Hev_Rx" SG_ 578 BrkTrnShifLck_B_Stat 1;
BA_ "U_CX482_CX483_MY20_Gas_Rx" SG_ 578 BrkTrnShifLck_B_Stat 1;
BA_ "U_CX482_CX483_MY20_Diesel_Rx" SG_ 578 BrkTrnShifLck_B_Stat 1;
BA_ "U_U611_U625_MY20_Hev_Rx" SG_ 578 BrkTrnShifLck_B_Stat 1;
BA_ "U_U611_U625_MY20_Gas_Rx" SG_ 578 BrkTrnShifLck_B_Stat 1;
BA_ "U_U611_U625_MY20_Diesel_Rx" SG_ 578 BrkTrnShifLck_B_Stat 1;
BA_ "U_C519_MY18_5_Gas_Rx" SG_ 578 BrkTrnShifLck_B_Stat 1;
BA_ "U_C519_MY18_5_Diesel_Rx" SG_ 578 BrkTrnShifLck_B_Stat 1;
BA_ "GenSigSendType" SG_ 578 BrkTrnShifLck_B_Stat 3;
BA_ "U_U611_U625_MY20_Phev_Rx" SG_ 578 DriverCrankingReq 1;
BA_ "U_CX482_CX483_MY20_Hev_Rx" SG_ 578 DriverCrankingReq 1;
BA_ "U_CX482_CX483_MY20_Gas_Rx" SG_ 578 DriverCrankingReq 1;
BA_ "U_CX482_CX483_MY20_Diesel_Rx" SG_ 578 DriverCrankingReq 1;
BA_ "U_U611_U625_MY20_Hev_Rx" SG_ 578 DriverCrankingReq 1;
BA_ "U_U611_U625_MY20_Gas_Rx" SG_ 578 DriverCrankingReq 1;
BA_ "U_U611_U625_MY20_Diesel_Rx" SG_ 578 DriverCrankingReq 1;
BA_ "U_C519_MY18_5_Gas_Rx" SG_ 578 DriverCrankingReq 1;
BA_ "U_C519_MY18_5_Diesel_Rx" SG_ 578 DriverCrankingReq 1;
BA_ "GenSigSendType" SG_ 578 DriverCrankingReq 3;
BA_ "U_CX482_CX483_MY20_Hev_Rx" SG_ 578 EngOff_T_Actl 1;
BA_ "U_CX482_CX483_MY20_Gas_Rx" SG_ 578 EngOff_T_Actl 1;
BA_ "U_CX482_CX483_MY20_Diesel_Rx" SG_ 578 EngOff_T_Actl 1;
BA_ "U_U611_U625_MY20_Hev_Rx" SG_ 578 EngOff_T_Actl 1;
BA_ "U_U611_U625_MY20_Gas_Rx" SG_ 578 EngOff_T_Actl 1;
BA_ "U_U611_U625_MY20_Diesel_Rx" SG_ 578 EngOff_T_Actl 1;
BA_ "U_B500_MY18_Diesel_Rx" SG_ 578 EngOff_T_Actl 1;
BA_ "U_B500_MY18_Gas_Rx" SG_ 578 EngOff_T_Actl 1;
BA_ "U_C519_MY18_5_Gas_Rx" SG_ 578 EngOff_T_Actl 1;
BA_ "U_C519_MY18_5_Diesel_Rx" SG_ 578 EngOff_T_Actl 1;
BA_ "U_B515_MCA_MY17_Gas_Rx" SG_ 578 EngOff_T_Actl 1;
BA_ "U_B515_MCA_MY17_Diesel_Rx" SG_ 578 EngOff_T_Actl 1;
BA_ "U_B479_MY17_Diesel_Rx" SG_ 578 EngOff_T_Actl 1;
BA_ "U_B479_MY17_Gas_Rx" SG_ 578 EngOff_T_Actl 1;
BA_ "GenSigSendType" SG_ 578 ReFuelSwtchStat_D_Actl 3;
BA_ "WakeupSignal" SG_ 578 ReFuelSwtchStat_D_Actl 1;
BA_ "GenSigSendType" SG_ 578 DcacElPw_D_Rq 3;
BA_ "GenSigStartValue" SG_ 578 BattULo_I_Actl 16383;
BA_ "U_CX482_CX483_MY20_Hev_Rx" SG_ 560 SelDrvMdeSwtch_D_Stat3 1;
BA_ "U_CX482_CX483_MY20_Gas_Rx" SG_ 560 SelDrvMdeSwtch_D_Stat3 1;
BA_ "U_CX482_CX483_MY20_Diesel_Rx" SG_ 560 SelDrvMdeSwtch_D_Stat3 1;
BA_ "U_U611_U625_MY20_Hev_Rx" SG_ 560 SelDrvMdeSwtch_D_Stat3 1;
BA_ "U_U611_U625_MY20_Gas_Rx" SG_ 560 SelDrvMdeSwtch_D_Stat3 1;
BA_ "U_U611_U625_MY20_Diesel_Rx" SG_ 560 SelDrvMdeSwtch_D_Stat3 1;
BA_ "U_C519_MY18_5_Gas_Rx" SG_ 560 SelDrvMdeSwtch_D_Stat3 1;
BA_ "U_C519_MY18_5_Diesel_Rx" SG_ 560 SelDrvMdeSwtch_D_Stat3 1;
BA_ "U_CX482_CX483_MY20_Hev_Rx" SG_ 560 TrnGbox_Rt_Actl 1;
BA_ "U_CX482_CX483_MY20_Gas_Rx" SG_ 560 TrnGbox_Rt_Actl 1;
BA_ "U_CX482_CX483_MY20_Diesel_Rx" SG_ 560 TrnGbox_Rt_Actl 1;
BA_ "U_B500_MY18_Diesel_Rx" SG_ 560 TrnGbox_Rt_Actl 1;
BA_ "U_B500_MY18_Gas_Rx" SG_ 560 TrnGbox_Rt_Actl 1;
BA_ "U_C490_MY18_Rx" SG_ 560 TrnGbox_Rt_Actl 1;
BA_ "U_B562_MY18_Gas_Rx" SG_ 560 TrnGbox_Rt_Actl 1;
BA_ "U_C519_MY18_5_Gas_Rx" SG_ 560 TrnGbox_Rt_Actl 1;
BA_ "U_C519_MY18_5_Diesel_Rx" SG_ 560 TrnGbox_Rt_Actl 1;
BA_ "U_B515_MCA_MY17_Gas_Rx" SG_ 560 TrnGbox_Rt_Actl 1;
BA_ "U_B515_MCA_MY17_Diesel_Rx" SG_ 560 TrnGbox_Rt_Actl 1;
BA_ "U_B479_MY17_Diesel_Rx" SG_ 560 TrnGbox_Rt_Actl 1;
BA_ "U_B479_MY17_Gas_Rx" SG_ 560 TrnGbox_Rt_Actl 1;
BA_ "ContentDependant" SG_ 560 TrnGbox_Rt_Actl 1;
BA_ "U_CX482_CX483_MY20_Hev_Rx" SG_ 560 TrnShifMde_D_RqDrv 1;
BA_ "U_CX482_CX483_MY20_Gas_Rx" SG_ 560 TrnShifMde_D_RqDrv 1;
BA_ "U_CX482_CX483_MY20_Diesel_Rx" SG_ 560 TrnShifMde_D_RqDrv 1;
BA_ "U_B500_MY18_Diesel_Rx" SG_ 560 TrnShifMde_D_RqDrv 1;
BA_ "U_B500_MY18_Gas_Rx" SG_ 560 TrnShifMde_D_RqDrv 1;
BA_ "U_C519_MY18_5_Gas_Rx" SG_ 560 TrnShifMde_D_RqDrv 1;
BA_ "U_C519_MY18_5_Diesel_Rx" SG_ 560 TrnShifMde_D_RqDrv 1;
BA_ "U_B515_MCA_MY17_Gas_Rx" SG_ 560 TrnShifMde_D_RqDrv 1;
BA_ "U_B515_MCA_MY17_Diesel_Rx" SG_ 560 TrnShifMde_D_RqDrv 1;
BA_ "U_B479_MY17_Diesel_Rx" SG_ 560 TrnShifMde_D_RqDrv 1;
BA_ "U_B479_MY17_Gas_Rx" SG_ 560 TrnShifMde_D_RqDrv 1;
BA_ "GenSigSendType" SG_ 560 TrnShifMde_D_RqDrv 3;
BA_ "CrossOver_InfoCAN" SG_ 560 TrnShifMde_D_RqDrv 1;
BA_ "U_CX482_CX483_MY20_Hev_Rx" SG_ 560 TrnSrvcRqd_B_Rq 1;
BA_ "U_CX482_CX483_MY20_Gas_Rx" SG_ 560 TrnSrvcRqd_B_Rq 1;
BA_ "U_CX482_CX483_MY20_Diesel_Rx" SG_ 560 TrnSrvcRqd_B_Rq 1;
BA_ "U_U611_U625_MY20_Hev_Rx" SG_ 560 TrnSrvcRqd_B_Rq 1;
BA_ "U_U611_U625_MY20_Gas_Rx" SG_ 560 TrnSrvcRqd_B_Rq 1;
BA_ "U_U611_U625_MY20_Diesel_Rx" SG_ 560 TrnSrvcRqd_B_Rq 1;
BA_ "U_B500_MY18_Diesel_Rx" SG_ 560 TrnSrvcRqd_B_Rq 1;
BA_ "U_B500_MY18_Gas_Rx" SG_ 560 TrnSrvcRqd_B_Rq 1;
BA_ "U_C490_MY18_Rx" SG_ 560 TrnSrvcRqd_B_Rq 1;
BA_ "U_B562_MY18_Gas_Rx" SG_ 560 TrnSrvcRqd_B_Rq 1;
BA_ "U_C519_MY18_5_Gas_Rx" SG_ 560 TrnSrvcRqd_B_Rq 1;
BA_ "U_C519_MY18_5_Diesel_Rx" SG_ 560 TrnSrvcRqd_B_Rq 1;
BA_ "U_B515_MCA_MY17_Gas_Rx" SG_ 560 TrnSrvcRqd_B_Rq 1;
BA_ "U_B515_MCA_MY17_Diesel_Rx" SG_ 560 TrnSrvcRqd_B_Rq 1;
BA_ "U_B479_MY17_Diesel_Rx" SG_ 560 TrnSrvcRqd_B_Rq 1;
BA_ "U_B479_MY17_Gas_Rx" SG_ 560 TrnSrvcRqd_B_Rq 1;
BA_ "GenSigSendType" SG_ 560 TrnSrvcRqd_B_Rq 3;
BA_ "ContentDependant" SG_ 560 TrnSrvcRqd_B_Rq 1;
BA_ "CrossOver_InfoCAN" SG_ 560 TrnSrvcRqd_B_Rq 1;
BA_ "U_CX482_CX483_MY20_Hev_Rx" SG_ 560 TrnCnvtClu_D_Actl 1;
BA_ "U_CX482_CX483_MY20_Gas_Rx" SG_ 560 TrnCnvtClu_D_Actl 1;
BA_ "U_CX482_CX483_MY20_Diesel_Rx" SG_ 560 TrnCnvtClu_D_Actl 1;
BA_ "U_B500_MY18_Diesel_Rx" SG_ 560 TrnCnvtClu_D_Actl 1;
BA_ "U_B500_MY18_Gas_Rx" SG_ 560 TrnCnvtClu_D_Actl 1;
BA_ "U_C519_MY18_5_Gas_Rx" SG_ 560 TrnCnvtClu_D_Actl 1;
BA_ "U_C519_MY18_5_Diesel_Rx" SG_ 560 TrnCnvtClu_D_Actl 1;
BA_ "U_B515_MCA_MY17_Gas_Rx" SG_ 560 TrnCnvtClu_D_Actl 1;
BA_ "U_B515_MCA_MY17_Diesel_Rx" SG_ 560 TrnCnvtClu_D_Actl 1;
BA_ "U_B479_MY17_Diesel_Rx" SG_ 560 TrnCnvtClu_D_Actl 1;
BA_ "U_B479_MY17_Gas_Rx" SG_ 560 TrnCnvtClu_D_Actl 1;
BA_ "GenSigSendType" SG_ 560 TrnCnvtClu_D_Actl 3;
BA_ "ContentDependant" SG_ 560 TrnCnvtClu_D_Actl 1;
BA_ "U_CX482_CX483_MY20_Hev_Rx" SG_ 560 TrnShifActv_B_Actl 1;
BA_ "U_CX482_CX483_MY20_Gas_Rx" SG_ 560 TrnShifActv_B_Actl 1;
BA_ "U_CX482_CX483_MY20_Diesel_Rx" SG_ 560 TrnShifActv_B_Actl 1;
BA_ "U_B500_MY18_Diesel_Rx" SG_ 560 TrnShifActv_B_Actl 1;
BA_ "U_B500_MY18_Gas_Rx" SG_ 560 TrnShifActv_B_Actl 1;
BA_ "U_C490_MY18_Rx" SG_ 560 TrnShifActv_B_Actl 1;
BA_ "U_B562_MY18_Gas_Rx" SG_ 560 TrnShifActv_B_Actl 1;
BA_ "U_C519_MY18_5_Gas_Rx" SG_ 560 TrnShifActv_B_Actl 1;
BA_ "U_C519_MY18_5_Diesel_Rx" SG_ 560 TrnShifActv_B_Actl 1;
BA_ "U_B515_MCA_MY17_Gas_Rx" SG_ 560 TrnShifActv_B_Actl 1;
BA_ "U_B515_MCA_MY17_Diesel_Rx" SG_ 560 TrnShifActv_B_Actl 1;
BA_ "U_B479_MY17_Diesel_Rx" SG_ 560 TrnShifActv_B_Actl 1;
BA_ "U_B479_MY17_Gas_Rx" SG_ 560 TrnShifActv_B_Actl 1;
BA_ "GenSigSendType" SG_ 560 TrnShifActv_B_Actl 3;
BA_ "ContentDependant" SG_ 560 TrnShifActv_B_Actl 1;
BA_ "GenSigSendType" SG_ 560 RtmTerrMdeChng_D_Rdy 3;
BA_ "GenSigSendType" SG_ 560 RtmTerrMde_D_Actl 3;
BA_ "U_U611_U625_MY20_Phev_Rx" SG_ 560 GearLvrPos_D_Actl 1;
BA_ "U_U611_U625_MY20_Hev_Rx" SG_ 560 GearLvrPos_D_Actl 1;
BA_ "U_U611_U625_MY20_Gas_Rx" SG_ 560 GearLvrPos_D_Actl 1;
BA_ "U_U611_U625_MY20_Diesel_Rx" SG_ 560 GearLvrPos_D_Actl 1;
BA_ "U_CX482_CX483_MY20_Hev_Rx" SG_ 560 GearLvrPos_D_Actl 1;
BA_ "U_CX482_CX483_MY20_Gas_Rx" SG_ 560 GearLvrPos_D_Actl 1;
BA_ "U_CX482_CX483_MY20_Diesel_Rx" SG_ 560 GearLvrPos_D_Actl 1;
BA_ "U_B500_MY18_Diesel_Rx" SG_ 560 GearLvrPos_D_Actl 1;
BA_ "U_B500_MY18_Gas_Rx" SG_ 560 GearLvrPos_D_Actl 1;
BA_ "U_C490_MY18_Rx" SG_ 560 GearLvrPos_D_Actl 1;
BA_ "U_B562_MY18_Gas_Rx" SG_ 560 GearLvrPos_D_Actl 1;
BA_ "U_C519_MY18_5_Gas_Rx" SG_ 560 GearLvrPos_D_Actl 1;
BA_ "U_C519_MY18_5_Diesel_Rx" SG_ 560 GearLvrPos_D_Actl 1;
BA_ "U_B515_MCA_MY17_Gas_Rx" SG_ 560 GearLvrPos_D_Actl 1;
BA_ "U_B515_MCA_MY17_Diesel_Rx" SG_ 560 GearLvrPos_D_Actl 1;
BA_ "U_B479_MY17_Diesel_Rx" SG_ 560 GearLvrPos_D_Actl 1;
BA_ "U_B479_MY17_Gas_Rx" SG_ 560 GearLvrPos_D_Actl 1;
BA_ "GenSigSendType" SG_ 560 GearLvrPos_D_Actl 3;
BA_ "GenSigStartValue" SG_ 560 GearLvrPos_D_Actl 14;
BA_ "CrossOver_InfoCAN" SG_ 560 GearLvrPos_D_Actl 1;
BA_ "ContentDependant" SG_ 560 GboxOil_Te_Actl 1;
BA_ "GenSigStartValue" SG_ 560 GboxOil_Te_Actl 254;
BA_ "ContentDependant" SG_ 560 GearLvrPosActl_No_Cs 1;
BA_ "ContentDependant" SG_ 560 GearLvrPosActl_No_Cnt 1;
BA_ "U_CX482_CX483_MY20_Hev_Rx" SG_ 359 PrplWhlRgenMn_Tq_Actl 1;
BA_ "U_CX482_CX483_MY20_Gas_Rx" SG_ 359 PrplWhlRgenMn_Tq_Actl 1;
BA_ "U_CX482_CX483_MY20_Diesel_Rx" SG_ 359 PrplWhlRgenMn_Tq_Actl 1;
BA_ "U_U611_U625_MY20_Hev_Rx" SG_ 359 PrplWhlRgenMn_Tq_Actl 1;
BA_ "U_U611_U625_MY20_Gas_Rx" SG_ 359 PrplWhlRgenMn_Tq_Actl 1;
BA_ "U_U611_U625_MY20_Diesel_Rx" SG_ 359 PrplWhlRgenMn_Tq_Actl 1;
BA_ "U_C519_MY18_5_Gas_Rx" SG_ 359 PrplWhlRgenMn_Tq_Actl 1;
BA_ "U_C519_MY18_5_Diesel_Rx" SG_ 359 PrplWhlRgenMn_Tq_Actl 1;
BA_ "U_B515_MCA_MY17_Gas_Rx" SG_ 359 PrplWhlRgenMn_Tq_Actl 1;
BA_ "U_B515_MCA_MY17_Diesel_Rx" SG_ 359 PrplWhlRgenMn_Tq_Actl 1;
BA_ "U_B479_MY17_Diesel_Rx" SG_ 359 PrplWhlRgenMn_Tq_Actl 1;
BA_ "U_B479_MY17_Gas_Rx" SG_ 359 PrplWhlRgenMn_Tq_Actl 1;
BA_ "GenSigStartValue" SG_ 359 PrplWhlRgenMn_Tq_Actl 4095;
BA_ "U_B515_MCA_MY17_Gas_Rx" SG_ 359 ElPw_D_StatStrtStop 1;
BA_ "U_B515_MCA_MY17_Diesel_Rx" SG_ 359 ElPw_D_StatStrtStop 1;
BA_ "U_U611_U625_MY20_Phev_Rx" SG_ 359 ElPw_D_StatStrtStop 1;
BA_ "U_CX482_CX483_MY20_Hev_Rx" SG_ 359 ElPw_D_StatStrtStop 1;
BA_ "U_CX482_CX483_MY20_Gas_Rx" SG_ 359 ElPw_D_StatStrtStop 1;
BA_ "U_CX482_CX483_MY20_Diesel_Rx" SG_ 359 ElPw_D_StatStrtStop 1;
BA_ "U_U611_U625_MY20_Hev_Rx" SG_ 359 ElPw_D_StatStrtStop 1;
BA_ "U_U611_U625_MY20_Gas_Rx" SG_ 359 ElPw_D_StatStrtStop 1;
BA_ "U_U611_U625_MY20_Diesel_Rx" SG_ 359 ElPw_D_StatStrtStop 1;
BA_ "U_B500_MY18_Diesel_Rx" SG_ 359 ElPw_D_StatStrtStop 1;
BA_ "U_B500_MY18_Gas_Rx" SG_ 359 ElPw_D_StatStrtStop 1;
BA_ "U_C490_MY18_Rx" SG_ 359 ElPw_D_StatStrtStop 1;
BA_ "U_B562_MY18_Gas_Rx" SG_ 359 ElPw_D_StatStrtStop 1;
BA_ "U_C519_MY18_5_Gas_Rx" SG_ 359 ElPw_D_StatStrtStop 1;
BA_ "U_C519_MY18_5_Diesel_Rx" SG_ 359 ElPw_D_StatStrtStop 1;
BA_ "U_B479_MY17_Diesel_Rx" SG_ 359 ElPw_D_StatStrtStop 1;
BA_ "U_B479_MY17_Gas_Rx" SG_ 359 ElPw_D_StatStrtStop 1;
BA_ "CrossOver_InfoCAN" SG_ 359 ElPw_D_StatStrtStop 1;
BA_ "U_CX482_CX483_MY20_Hev_Rx" SG_ 359 TrnAin_Tq_Actl 1;
BA_ "U_CX482_CX483_MY20_Gas_Rx" SG_ 359 TrnAin_Tq_Actl 1;
BA_ "U_CX482_CX483_MY20_Diesel_Rx" SG_ 359 TrnAin_Tq_Actl 1;
BA_ "U_U611_U625_MY20_Hev_Rx" SG_ 359 TrnAin_Tq_Actl 1;
BA_ "U_U611_U625_MY20_Gas_Rx" SG_ 359 TrnAin_Tq_Actl 1;
BA_ "U_U611_U625_MY20_Diesel_Rx" SG_ 359 TrnAin_Tq_Actl 1;
BA_ "U_B500_MY18_Diesel_Rx" SG_ 359 TrnAin_Tq_Actl 1;
BA_ "U_B500_MY18_Gas_Rx" SG_ 359 TrnAin_Tq_Actl 1;
BA_ "U_C490_MY18_Rx" SG_ 359 TrnAin_Tq_Actl 1;
BA_ "U_B562_MY18_Gas_Rx" SG_ 359 TrnAin_Tq_Actl 1;
BA_ "U_C519_MY18_5_Gas_Rx" SG_ 359 TrnAin_Tq_Actl 1;
BA_ "U_C519_MY18_5_Diesel_Rx" SG_ 359 TrnAin_Tq_Actl 1;
BA_ "U_B515_MCA_MY17_Gas_Rx" SG_ 359 TrnAin_Tq_Actl 1;
BA_ "U_B515_MCA_MY17_Diesel_Rx" SG_ 359 TrnAin_Tq_Actl 1;
BA_ "U_B479_MY17_Diesel_Rx" SG_ 359 TrnAin_Tq_Actl 1;
BA_ "U_B479_MY17_Gas_Rx" SG_ 359 TrnAin_Tq_Actl 1;
BA_ "ContentDependant" SG_ 359 TrnAin_Tq_Actl 1;
BA_ "CrossOver_InfoCAN" SG_ 359 TrnAin_Tq_Actl 1;
BA_ "U_B500_MY18_Diesel_Rx" SG_ 359 PrplWhlTot2_Tq_Actl 1;
BA_ "U_B500_MY18_Gas_Rx" SG_ 359 PrplWhlTot2_Tq_Actl 1;
BA_ "U_C490_MY18_Rx" SG_ 359 PrplWhlTot2_Tq_Actl 1;
BA_ "U_B562_MY18_Gas_Rx" SG_ 359 PrplWhlTot2_Tq_Actl 1;
BA_ "U_B515_MCA_MY17_Gas_Rx" SG_ 359 PrplWhlTot2_Tq_Actl 1;
BA_ "U_B515_MCA_MY17_Diesel_Rx" SG_ 359 PrplWhlTot2_Tq_Actl 1;
BA_ "U_B479_MY17_Diesel_Rx" SG_ 359 PrplWhlTot2_Tq_Actl 1;
BA_ "U_B479_MY17_Gas_Rx" SG_ 359 PrplWhlTot2_Tq_Actl 1;
BA_ "U_U611_U625_MY20_Phev_Rx" SG_ 359 PrplWhlTot2_Tq_Actl 1;
BA_ "U_CX482_CX483_MY20_Hev_Rx" SG_ 359 PrplWhlTot2_Tq_Actl 1;
BA_ "U_CX482_CX483_MY20_Gas_Rx" SG_ 359 PrplWhlTot2_Tq_Actl 1;
BA_ "U_CX482_CX483_MY20_Diesel_Rx" SG_ 359 PrplWhlTot2_Tq_Actl 1;
BA_ "U_U611_U625_MY20_Hev_Rx" SG_ 359 PrplWhlTot2_Tq_Actl 1;
BA_ "U_U611_U625_MY20_Gas_Rx" SG_ 359 PrplWhlTot2_Tq_Actl 1;
BA_ "U_U611_U625_MY20_Diesel_Rx" SG_ 359 PrplWhlTot2_Tq_Actl 1;
BA_ "U_C519_MY18_5_Gas_Rx" SG_ 359 PrplWhlTot2_Tq_Actl 1;
BA_ "U_C519_MY18_5_Diesel_Rx" SG_ 359 PrplWhlTot2_Tq_Actl 1;
BA_ "CrossOver_InfoCAN" SG_ 359 PrplWhlTot2_Tq_Actl 1;
BA_ "U_U611_U625_MY20_Hev_Rx" SG_ 359 LscmbbDeny_B_ActlPrpl 1;
BA_ "U_U611_U625_MY20_Gas_Rx" SG_ 359 LscmbbDeny_B_ActlPrpl 1;
BA_ "U_U611_U625_MY20_Diesel_Rx" SG_ 359 LscmbbDeny_B_ActlPrpl 1;
BA_ "U_B515_MCA_MY17_Gas_Rx" SG_ 359 LscmbbDeny_B_ActlPrpl 1;
BA_ "U_B515_MCA_MY17_Diesel_Rx" SG_ 359 LscmbbDeny_B_ActlPrpl 1;
BA_ "CrossOver_InfoCAN" SG_ 359 LscmbbDeny_B_ActlPrpl 1;
BA_ "U_U611_U625_MY20_Hev_Rx" SG_ 359 LscmbbEngTqMn_B_Actl 1;
BA_ "U_U611_U625_MY20_Gas_Rx" SG_ 359 LscmbbEngTqMn_B_Actl 1;
BA_ "U_U611_U625_MY20_Diesel_Rx" SG_ 359 LscmbbEngTqMn_B_Actl 1;
BA_ "U_B515_MCA_MY17_Gas_Rx" SG_ 359 LscmbbEngTqMn_B_Actl 1;
BA_ "U_B515_MCA_MY17_Diesel_Rx" SG_ 359 LscmbbEngTqMn_B_Actl 1;
BA_ "CrossOver_InfoCAN" SG_ 359 LscmbbEngTqMn_B_Actl 1;
BA_ "U_U611_U625_MY20_Phev_Rx" SG_ 359 PwPckTq_D_Stat 1;
BA_ "U_CX482_CX483_MY20_Hev_Rx" SG_ 359 PwPckTq_D_Stat 1;
BA_ "U_CX482_CX483_MY20_Gas_Rx" SG_ 359 PwPckTq_D_Stat 1;
BA_ "U_CX482_CX483_MY20_Diesel_Rx" SG_ 359 PwPckTq_D_Stat 1;
BA_ "U_U611_U625_MY20_Hev_Rx" SG_ 359 PwPckTq_D_Stat 1;
BA_ "U_U611_U625_MY20_Gas_Rx" SG_ 359 PwPckTq_D_Stat 1;
BA_ "U_U611_U625_MY20_Diesel_Rx" SG_ 359 PwPckTq_D_Stat 1;
BA_ "U_B500_MY18_Diesel_Rx" SG_ 359 PwPckTq_D_Stat 1;
BA_ "U_B500_MY18_Gas_Rx" SG_ 359 PwPckTq_D_Stat 1;
BA_ "U_C490_MY18_Rx" SG_ 359 PwPckTq_D_Stat 1;
BA_ "U_B562_MY18_Gas_Rx" SG_ 359 PwPckTq_D_Stat 1;
BA_ "U_C519_MY18_5_Gas_Rx" SG_ 359 PwPckTq_D_Stat 1;
BA_ "U_C519_MY18_5_Diesel_Rx" SG_ 359 PwPckTq_D_Stat 1;
BA_ "U_B515_MCA_MY17_Gas_Rx" SG_ 359 PwPckTq_D_Stat 1;
BA_ "U_B515_MCA_MY17_Diesel_Rx" SG_ 359 PwPckTq_D_Stat 1;
BA_ "U_B479_MY17_Diesel_Rx" SG_ 359 PwPckTq_D_Stat 1;
BA_ "U_B479_MY17_Gas_Rx" SG_ 359 PwPckTq_D_Stat 1;
BA_ "CrossOver_InfoCAN" SG_ 359 PwPckTq_D_Stat 1;
BA_ "U_CX482_CX483_MY20_Hev_Rx" SG_ 359 Eng_D_Stat 1;
BA_ "U_CX482_CX483_MY20_Gas_Rx" SG_ 359 Eng_D_Stat 1;
BA_ "U_CX482_CX483_MY20_Diesel_Rx" SG_ 359 Eng_D_Stat 1;
BA_ "U_U611_U625_MY20_Hev_Rx" SG_ 359 Eng_D_Stat 1;
BA_ "U_U611_U625_MY20_Gas_Rx" SG_ 359 Eng_D_Stat 1;
BA_ "U_U611_U625_MY20_Diesel_Rx" SG_ 359 Eng_D_Stat 1;
BA_ "U_B500_MY18_Diesel_Rx" SG_ 359 Eng_D_Stat 1;
BA_ "U_B500_MY18_Gas_Rx" SG_ 359 Eng_D_Stat 1;
BA_ "U_C490_MY18_Rx" SG_ 359 Eng_D_Stat 1;
BA_ "U_B562_MY18_Gas_Rx" SG_ 359 Eng_D_Stat 1;
BA_ "U_C519_MY18_5_Gas_Rx" SG_ 359 Eng_D_Stat 1;
BA_ "U_C519_MY18_5_Diesel_Rx" SG_ 359 Eng_D_Stat 1;
BA_ "U_B515_MCA_MY17_Gas_Rx" SG_ 359 Eng_D_Stat 1;
BA_ "U_B515_MCA_MY17_Diesel_Rx" SG_ 359 Eng_D_Stat 1;
BA_ "U_B479_MY17_Diesel_Rx" SG_ 359 Eng_D_Stat 1;
BA_ "U_B479_MY17_Gas_Rx" SG_ 359 Eng_D_Stat 1;
BA_ "CrossOver_InfoCAN" SG_ 359 Eng_D_Stat 1;
BA_ "U_C490_MY18_Rx" SG_ 359 ElPw_D_Stat 1;
BA_ "U_B562_MY18_Gas_Rx" SG_ 359 ElPw_D_Stat 1;
BA_ "U_CX482_CX483_MY20_Hev_Rx" SG_ 359 ElPw_D_Stat 1;
BA_ "U_CX482_CX483_MY20_Gas_Rx" SG_ 359 ElPw_D_Stat 1;
BA_ "U_CX482_CX483_MY20_Diesel_Rx" SG_ 359 ElPw_D_Stat 1;
BA_ "U_B500_MY18_Diesel_Rx" SG_ 359 ElPw_D_Stat 1;
BA_ "U_B500_MY18_Gas_Rx" SG_ 359 ElPw_D_Stat 1;
BA_ "U_B515_MCA_MY17_Gas_Rx" SG_ 359 ElPw_D_Stat 1;
BA_ "U_B515_MCA_MY17_Diesel_Rx" SG_ 359 ElPw_D_Stat 1;
BA_ "U_B479_MY17_Diesel_Rx" SG_ 359 ElPw_D_Stat 1;
BA_ "U_B479_MY17_Gas_Rx" SG_ 359 ElPw_D_Stat 1;
BA_ "U_U611_U625_MY20_Phev_Rx" SG_ 359 ElPw_D_Stat 1;
BA_ "U_U611_U625_MY20_Hev_Rx" SG_ 359 ElPw_D_Stat 1;
BA_ "U_U611_U625_MY20_Gas_Rx" SG_ 359 ElPw_D_Stat 1;
BA_ "U_U611_U625_MY20_Diesel_Rx" SG_ 359 ElPw_D_Stat 1;
BA_ "U_C519_MY18_5_Gas_Rx" SG_ 359 ElPw_D_Stat 1;
BA_ "U_C519_MY18_5_Diesel_Rx" SG_ 359 ElPw_D_Stat 1;
BA_ "CrossOver_InfoCAN" SG_ 359 ElPw_D_Stat 1;
BA_ "U_CX482_CX483_MY20_Hev_Rx" SG_ 359 TrnAinTq_D_Qf 1;
BA_ "U_CX482_CX483_MY20_Gas_Rx" SG_ 359 TrnAinTq_D_Qf 1;
BA_ "U_CX482_CX483_MY20_Diesel_Rx" SG_ 359 TrnAinTq_D_Qf 1;
BA_ "U_U611_U625_MY20_Hev_Rx" SG_ 359 TrnAinTq_D_Qf 1;
BA_ "U_U611_U625_MY20_Gas_Rx" SG_ 359 TrnAinTq_D_Qf 1;
BA_ "U_U611_U625_MY20_Diesel_Rx" SG_ 359 TrnAinTq_D_Qf 1;
BA_ "U_B500_MY18_Diesel_Rx" SG_ 359 TrnAinTq_D_Qf 1;
BA_ "U_B500_MY18_Gas_Rx" SG_ 359 TrnAinTq_D_Qf 1;
BA_ "U_C490_MY18_Rx" SG_ 359 TrnAinTq_D_Qf 1;
BA_ "U_B562_MY18_Gas_Rx" SG_ 359 TrnAinTq_D_Qf 1;
BA_ "U_C519_MY18_5_Gas_Rx" SG_ 359 TrnAinTq_D_Qf 1;
BA_ "U_C519_MY18_5_Diesel_Rx" SG_ 359 TrnAinTq_D_Qf 1;
BA_ "U_B515_MCA_MY17_Gas_Rx" SG_ 359 TrnAinTq_D_Qf 1;
BA_ "U_B515_MCA_MY17_Diesel_Rx" SG_ 359 TrnAinTq_D_Qf 1;
BA_ "U_B479_MY17_Diesel_Rx" SG_ 359 TrnAinTq_D_Qf 1;
BA_ "U_B479_MY17_Gas_Rx" SG_ 359 TrnAinTq_D_Qf 1;
BA_ "ContentDependant" SG_ 359 TrnAinTq_D_Qf 1;
BA_ "CrossOver_InfoCAN" SG_ 359 TrnAinTq_D_Qf 1;
BA_ "ContentDependant" SG_ 359 PlgActvArb_B_Actl 1;
BA_ "GenSigStartValue" SG_ 359 PlgActvArb_B_Actl 1;
BA_ "CrossOver_InfoCAN" SG_ 359 PlgActvArb_B_Actl 1;
BA_ "U_CX482_CX483_MY20_Hev_Rx" SG_ 372 EngAoutIdl_N_RqVsc 1;
BA_ "U_CX482_CX483_MY20_Gas_Rx" SG_ 372 EngAoutIdl_N_RqVsc 1;
BA_ "U_CX482_CX483_MY20_Diesel_Rx" SG_ 372 EngAoutIdl_N_RqVsc 1;
BA_ "U_B500_MY18_Diesel_Rx" SG_ 372 EngAoutIdl_N_RqVsc 1;
BA_ "U_B500_MY18_Gas_Rx" SG_ 372 EngAoutIdl_N_RqVsc 1;
BA_ "U_B562_MY18_Gas_Rx" SG_ 372 EngAoutIdl_N_RqVsc 1;
BA_ "U_C519_MY18_5_Gas_Rx" SG_ 372 EngAoutIdl_N_RqVsc 1;
BA_ "U_C519_MY18_5_Diesel_Rx" SG_ 372 EngAoutIdl_N_RqVsc 1;
BA_ "U_B515_MCA_MY17_Gas_Rx" SG_ 372 EngAoutIdl_N_RqVsc 1;
BA_ "U_B515_MCA_MY17_Diesel_Rx" SG_ 372 EngAoutIdl_N_RqVsc 1;
BA_ "U_B479_MY17_Diesel_Rx" SG_ 372 EngAoutIdl_N_RqVsc 1;
BA_ "U_B479_MY17_Gas_Rx" SG_ 372 EngAoutIdl_N_RqVsc 1;
BA_ "U_U611_U625_MY20_Phev_Rx" SG_ 357 BPedDrvAppl_D_QF 1;
BA_ "U_U611_U625_MY20_Hev_Rx" SG_ 357 BPedDrvAppl_D_QF 1;
BA_ "U_U611_U625_MY20_Gas_Rx" SG_ 357 BPedDrvAppl_D_QF 1;
BA_ "U_U611_U625_MY20_Diesel_Rx" SG_ 357 BPedDrvAppl_D_QF 1;
BA_ "U_CX482_CX483_MY20_Hev_Rx" SG_ 357 BPedDrvAppl_D_QF 1;
BA_ "U_CX482_CX483_MY20_Gas_Rx" SG_ 357 BPedDrvAppl_D_QF 1;
BA_ "U_CX482_CX483_MY20_Diesel_Rx" SG_ 357 BPedDrvAppl_D_QF 1;
BA_ "U_B500_MY18_Diesel_Rx" SG_ 357 BPedDrvAppl_D_QF 1;
BA_ "U_B500_MY18_Gas_Rx" SG_ 357 BPedDrvAppl_D_QF 1;
BA_ "U_C490_MY18_Rx" SG_ 357 BPedDrvAppl_D_QF 1;
BA_ "U_B562_MY18_Gas_Rx" SG_ 357 BPedDrvAppl_D_QF 1;
BA_ "U_C519_MY18_5_Gas_Rx" SG_ 357 BPedDrvAppl_D_QF 1;
BA_ "U_C519_MY18_5_Diesel_Rx" SG_ 357 BPedDrvAppl_D_QF 1;
BA_ "U_B515_MCA_MY17_Gas_Rx" SG_ 357 BPedDrvAppl_D_QF 1;
BA_ "U_B515_MCA_MY17_Diesel_Rx" SG_ 357 BPedDrvAppl_D_QF 1;
BA_ "U_B479_MY17_Diesel_Rx" SG_ 357 BPedDrvAppl_D_QF 1;
BA_ "U_B479_MY17_Gas_Rx" SG_ 357 BPedDrvAppl_D_QF 1;
BA_ "GenSigSendType" SG_ 357 BPedDrvAppl_D_QF 3;
BA_ "GenSigStartValue" SG_ 357 BPedDrvAppl_D_QF 1;
BA_ "U_CX482_CX483_MY20_Hev_Rx" SG_ 357 CmbbDeny_B_ActlPrpl 1;
BA_ "U_CX482_CX483_MY20_Gas_Rx" SG_ 357 CmbbDeny_B_ActlPrpl 1;
BA_ "U_CX482_CX483_MY20_Diesel_Rx" SG_ 357 CmbbDeny_B_ActlPrpl 1;
BA_ "U_U611_U625_MY20_Hev_Rx" SG_ 357 CmbbDeny_B_ActlPrpl 1;
BA_ "U_U611_U625_MY20_Gas_Rx" SG_ 357 CmbbDeny_B_ActlPrpl 1;
BA_ "U_U611_U625_MY20_Diesel_Rx" SG_ 357 CmbbDeny_B_ActlPrpl 1;
BA_ "U_C519_MY18_5_Gas_Rx" SG_ 357 CmbbDeny_B_ActlPrpl 1;
BA_ "U_C519_MY18_5_Diesel_Rx" SG_ 357 CmbbDeny_B_ActlPrpl 1;
BA_ "U_B479_MY17_Diesel_Rx" SG_ 357 CmbbDeny_B_ActlPrpl 1;
BA_ "U_B479_MY17_Gas_Rx" SG_ 357 CmbbDeny_B_ActlPrpl 1;
BA_ "GenSigSendType" SG_ 357 CmbbDeny_B_ActlPrpl 3;
BA_ "U_CX482_CX483_MY20_Hev_Rx" SG_ 357 PrplTqMnSat_B_Actl 1;
BA_ "U_CX482_CX483_MY20_Gas_Rx" SG_ 357 PrplTqMnSat_B_Actl 1;
BA_ "U_CX482_CX483_MY20_Diesel_Rx" SG_ 357 PrplTqMnSat_B_Actl 1;
BA_ "U_U611_U625_MY20_Hev_Rx" SG_ 357 PrplTqMnSat_B_Actl 1;
BA_ "U_U611_U625_MY20_Gas_Rx" SG_ 357 PrplTqMnSat_B_Actl 1;
BA_ "U_U611_U625_MY20_Diesel_Rx" SG_ 357 PrplTqMnSat_B_Actl 1;
BA_ "U_C519_MY18_5_Gas_Rx" SG_ 357 PrplTqMnSat_B_Actl 1;
BA_ "U_C519_MY18_5_Diesel_Rx" SG_ 357 PrplTqMnSat_B_Actl 1;
BA_ "U_B479_MY17_Diesel_Rx" SG_ 357 PrplTqMnSat_B_Actl 1;
BA_ "U_B479_MY17_Gas_Rx" SG_ 357 PrplTqMnSat_B_Actl 1;
BA_ "GenSigSendType" SG_ 357 PrplTqMnSat_B_Actl 3;
BA_ "GenSigSendType" SG_ 357 VehStrtStop_D_Rq 3;
BA_ "U_U611_U625_MY20_Phev_Rx" SG_ 357 BpedDrvAppl_D_Actl 1;
BA_ "U_B500_MY18_Diesel_Rx" SG_ 357 BpedDrvAppl_D_Actl 1;
BA_ "U_B500_MY18_Gas_Rx" SG_ 357 BpedDrvAppl_D_Actl 1;
BA_ "U_C490_MY18_Rx" SG_ 357 BpedDrvAppl_D_Actl 1;
BA_ "U_B562_MY18_Gas_Rx" SG_ 357 BpedDrvAppl_D_Actl 1;
BA_ "U_B515_MCA_MY17_Gas_Rx" SG_ 357 BpedDrvAppl_D_Actl 1;
BA_ "U_B515_MCA_MY17_Diesel_Rx" SG_ 357 BpedDrvAppl_D_Actl 1;
BA_ "U_CX482_CX483_MY20_Hev_Rx" SG_ 357 BpedDrvAppl_D_Actl 1;
BA_ "U_CX482_CX483_MY20_Gas_Rx" SG_ 357 BpedDrvAppl_D_Actl 1;
BA_ "U_CX482_CX483_MY20_Diesel_Rx" SG_ 357 BpedDrvAppl_D_Actl 1;
BA_ "U_U611_U625_MY20_Hev_Rx" SG_ 357 BpedDrvAppl_D_Actl 1;
BA_ "U_U611_U625_MY20_Gas_Rx" SG_ 357 BpedDrvAppl_D_Actl 1;
BA_ "U_U611_U625_MY20_Diesel_Rx" SG_ 357 BpedDrvAppl_D_Actl 1;
BA_ "U_C519_MY18_5_Gas_Rx" SG_ 357 BpedDrvAppl_D_Actl 1;
BA_ "U_C519_MY18_5_Diesel_Rx" SG_ 357 BpedDrvAppl_D_Actl 1;
BA_ "U_B479_MY17_Diesel_Rx" SG_ 357 BpedDrvAppl_D_Actl 1;
BA_ "U_B479_MY17_Gas_Rx" SG_ 357 BpedDrvAppl_D_Actl 1;
BA_ "GenSigSendType" SG_ 357 BpedDrvAppl_D_Actl 3;
BA_ "GenSigStartValue" SG_ 357 BpedDrvAppl_D_Actl 1;
BA_ "CrossOver_InfoCAN" SG_ 357 BpedDrvAppl_D_Actl 1;
BA_ "U_CX482_CX483_MY20_Hev_Rx" SG_ 357 CmbbEngTqMn_B_Actl 1;
BA_ "U_CX482_CX483_MY20_Gas_Rx" SG_ 357 CmbbEngTqMn_B_Actl 1;
BA_ "U_CX482_CX483_MY20_Diesel_Rx" SG_ 357 CmbbEngTqMn_B_Actl 1;
BA_ "U_U611_U625_MY20_Hev_Rx" SG_ 357 CmbbEngTqMn_B_Actl 1;
BA_ "U_U611_U625_MY20_Gas_Rx" SG_ 357 CmbbEngTqMn_B_Actl 1;
BA_ "U_U611_U625_MY20_Diesel_Rx" SG_ 357 CmbbEngTqMn_B_Actl 1;
BA_ "U_C519_MY18_5_Gas_Rx" SG_ 357 CmbbEngTqMn_B_Actl 1;
BA_ "U_C519_MY18_5_Diesel_Rx" SG_ 357 CmbbEngTqMn_B_Actl 1;
BA_ "U_B479_MY17_Diesel_Rx" SG_ 357 CmbbEngTqMn_B_Actl 1;
BA_ "U_B479_MY17_Gas_Rx" SG_ 357 CmbbEngTqMn_B_Actl 1;
BA_ "GenSigSendType" SG_ 357 CmbbEngTqMn_B_Actl 3;
BA_ "CrossOver_InfoCAN" SG_ 357 Veh_V_DsplyCcSet 1;
BA_ "U_CX482_CX483_MY20_Hev_Rx" SG_ 357 AccEngStat_D_Actl 1;
BA_ "U_CX482_CX483_MY20_Gas_Rx" SG_ 357 AccEngStat_D_Actl 1;
BA_ "U_CX482_CX483_MY20_Diesel_Rx" SG_ 357 AccEngStat_D_Actl 1;
BA_ "U_U611_U625_MY20_Hev_Rx" SG_ 357 AccEngStat_D_Actl 1;
BA_ "U_U611_U625_MY20_Gas_Rx" SG_ 357 AccEngStat_D_Actl 1;
BA_ "U_U611_U625_MY20_Diesel_Rx" SG_ 357 AccEngStat_D_Actl 1;
BA_ "U_C519_MY18_5_Gas_Rx" SG_ 357 AccEngStat_D_Actl 1;
BA_ "U_C519_MY18_5_Diesel_Rx" SG_ 357 AccEngStat_D_Actl 1;
BA_ "U_B479_MY17_Diesel_Rx" SG_ 357 AccEngStat_D_Actl 1;
BA_ "U_B479_MY17_Gas_Rx" SG_ 357 AccEngStat_D_Actl 1;
BA_ "GenSigSendType" SG_ 357 AccEngStat_D_Actl 3;
BA_ "U_CX482_CX483_MY20_Hev_Rx" SG_ 357 CcMde_D_Actl 1;
BA_ "U_CX482_CX483_MY20_Gas_Rx" SG_ 357 CcMde_D_Actl 1;
BA_ "U_CX482_CX483_MY20_Diesel_Rx" SG_ 357 CcMde_D_Actl 1;
BA_ "U_C519_MY18_5_Gas_Rx" SG_ 357 CcMde_D_Actl 1;
BA_ "U_C519_MY18_5_Diesel_Rx" SG_ 357 CcMde_D_Actl 1;
BA_ "U_B515_MCA_MY17_Gas_Rx" SG_ 357 CcMde_D_Actl 1;
BA_ "U_B515_MCA_MY17_Diesel_Rx" SG_ 357 CcMde_D_Actl 1;
BA_ "U_B479_MY17_Diesel_Rx" SG_ 357 CcMde_D_Actl 1;
BA_ "U_B479_MY17_Gas_Rx" SG_ 357 CcMde_D_Actl 1;
BA_ "GenSigSendType" SG_ 357 CcMde_D_Actl 3;
BA_ "U_U611_U625_MY20_Phev_Rx" SG_ 357 CcStat_D_Actl 1;
BA_ "U_CX482_CX483_MY20_Hev_Rx" SG_ 357 CcStat_D_Actl 1;
BA_ "U_CX482_CX483_MY20_Gas_Rx" SG_ 357 CcStat_D_Actl 1;
BA_ "U_CX482_CX483_MY20_Diesel_Rx" SG_ 357 CcStat_D_Actl 1;
BA_ "U_U611_U625_MY20_Hev_Rx" SG_ 357 CcStat_D_Actl 1;
BA_ "U_U611_U625_MY20_Gas_Rx" SG_ 357 CcStat_D_Actl 1;
BA_ "U_U611_U625_MY20_Diesel_Rx" SG_ 357 CcStat_D_Actl 1;
BA_ "U_B500_MY18_Diesel_Rx" SG_ 357 CcStat_D_Actl 1;
BA_ "U_B500_MY18_Gas_Rx" SG_ 357 CcStat_D_Actl 1;
BA_ "U_B562_MY18_Gas_Rx" SG_ 357 CcStat_D_Actl 1;
BA_ "U_C519_MY18_5_Gas_Rx" SG_ 357 CcStat_D_Actl 1;
BA_ "U_C519_MY18_5_Diesel_Rx" SG_ 357 CcStat_D_Actl 1;
BA_ "U_B515_MCA_MY17_Gas_Rx" SG_ 357 CcStat_D_Actl 1;
BA_ "U_B515_MCA_MY17_Diesel_Rx" SG_ 357 CcStat_D_Actl 1;
BA_ "U_B479_MY17_Diesel_Rx" SG_ 357 CcStat_D_Actl 1;
BA_ "U_B479_MY17_Gas_Rx" SG_ 357 CcStat_D_Actl 1;
BA_ "GenSigSendType" SG_ 357 CcStat_D_Actl 3;
BA_ "CrossOver_InfoCAN" SG_ 357 CcStat_D_Actl 1;
BA_ "U_CX482_CX483_MY20_Hev_Rx" SG_ 357 CcOvrrdActv_B_Actl 1;
BA_ "U_CX482_CX483_MY20_Gas_Rx" SG_ 357 CcOvrrdActv_B_Actl 1;
BA_ "U_CX482_CX483_MY20_Diesel_Rx" SG_ 357 CcOvrrdActv_B_Actl 1;
BA_ "U_U611_U625_MY20_Hev_Rx" SG_ 357 CcOvrrdActv_B_Actl 1;
BA_ "U_U611_U625_MY20_Gas_Rx" SG_ 357 CcOvrrdActv_B_Actl 1;
BA_ "U_U611_U625_MY20_Diesel_Rx" SG_ 357 CcOvrrdActv_B_Actl 1;
BA_ "U_B500_MY18_Diesel_Rx" SG_ 357 CcOvrrdActv_B_Actl 1;
BA_ "U_B500_MY18_Gas_Rx" SG_ 357 CcOvrrdActv_B_Actl 1;
BA_ "U_C519_MY18_5_Gas_Rx" SG_ 357 CcOvrrdActv_B_Actl 1;
BA_ "U_C519_MY18_5_Diesel_Rx" SG_ 357 CcOvrrdActv_B_Actl 1;
BA_ "U_B515_MCA_MY17_Gas_Rx" SG_ 357 CcOvrrdActv_B_Actl 1;
BA_ "U_B515_MCA_MY17_Diesel_Rx" SG_ 357 CcOvrrdActv_B_Actl 1;
BA_ "U_B479_MY17_Diesel_Rx" SG_ 357 CcOvrrdActv_B_Actl 1;
BA_ "U_B479_MY17_Gas_Rx" SG_ 357 CcOvrrdActv_B_Actl 1;
BA_ "GenSigSendType" SG_ 357 CcOvrrdActv_B_Actl 3;
BA_ "CrossOver_InfoCAN" SG_ 357 CcOvrrdActv_B_Actl 1;
BA_ "U_U611_U625_MY20_Hev_Rx" SG_ 357 AccStopMde_D_Rq 1;
BA_ "U_U611_U625_MY20_Gas_Rx" SG_ 357 AccStopMde_D_Rq 1;
BA_ "U_U611_U625_MY20_Diesel_Rx" SG_ 357 AccStopMde_D_Rq 1;
BA_ "U_CX482_CX483_MY20_Hev_Rx" SG_ 357 AccStopMde_D_Rq 1;
BA_ "U_CX482_CX483_MY20_Gas_Rx" SG_ 357 AccStopMde_D_Rq 1;
BA_ "U_CX482_CX483_MY20_Diesel_Rx" SG_ 357 AccStopMde_D_Rq 1;
BA_ "U_B515_MCA_MY17_Gas_Rx" SG_ 357 AccStopMde_D_Rq 1;
BA_ "U_B515_MCA_MY17_Diesel_Rx" SG_ 357 AccStopMde_D_Rq 1;
BA_ "U_C519_MY18_5_Gas_Rx" SG_ 357 AccStopMde_D_Rq 1;
BA_ "U_C519_MY18_5_Diesel_Rx" SG_ 357 AccStopMde_D_Rq 1;
BA_ "U_B479_MY17_Diesel_Rx" SG_ 357 AccStopMde_D_Rq 1;
BA_ "U_B479_MY17_Gas_Rx" SG_ 357 AccStopMde_D_Rq 1;
BA_ "GenSigSendType" SG_ 357 AccStopMde_D_Rq 3;
BA_ "U_U611_U625_MY20_Phev_Tx" SG_ 1461 PSCM_GWOnBoardTester 1;
BA_ "U_CX482_CX483_MY20_Hev_Tx" SG_ 1461 PSCM_GWOnBoardTester 1;
BA_ "U_CX482_CX483_MY20_Gas_Tx" SG_ 1461 PSCM_GWOnBoardTester 1;
BA_ "U_CX482_CX483_MY20_Diesel_Tx" SG_ 1461 PSCM_GWOnBoardTester 1;
BA_ "U_U611_U625_MY20_Hev_Tx" SG_ 1461 PSCM_GWOnBoardTester 1;
BA_ "U_U611_U625_MY20_Gas_Tx" SG_ 1461 PSCM_GWOnBoardTester 1;
BA_ "U_U611_U625_MY20_Diesel_Tx" SG_ 1461 PSCM_GWOnBoardTester 1;
BA_ "U_B500_MY18_Diesel_Tx" SG_ 1461 PSCM_GWOnBoardTester 1;
BA_ "U_B500_MY18_Gas_Tx" SG_ 1461 PSCM_GWOnBoardTester 1;
BA_ "U_C490_MY18_Tx" SG_ 1461 PSCM_GWOnBoardTester 1;
BA_ "U_B562_MY18_Gas_Tx" SG_ 1461 PSCM_GWOnBoardTester 1;
BA_ "U_C519_MY18_5_Gas_Tx" SG_ 1461 PSCM_GWOnBoardTester 1;
BA_ "U_C519_MY18_5_Diesel_Tx" SG_ 1461 PSCM_GWOnBoardTester 1;
BA_ "U_B479_MY17_Diesel_Tx" SG_ 1461 PSCM_GWOnBoardTester 1;
BA_ "U_B479_MY17_Gas_Tx" SG_ 1461 PSCM_GWOnBoardTester 1;
BA_ "U_B479_MY17_Diesel_Rx" SG_ 1461 PSCM_GWOnBoardTester 1;
BA_ "U_B479_MY17_Gas_Rx" SG_ 1461 PSCM_GWOnBoardTester 1;
BA_ "U_U611_U625_MY20_Phev_Rx" SG_ 1461 PSCM_GWOnBoardTester 1;
BA_ "U_U611_U625_MY20_Hev_Rx" SG_ 1461 PSCM_GWOnBoardTester 1;
BA_ "U_U611_U625_MY20_Gas_Rx" SG_ 1461 PSCM_GWOnBoardTester 1;
BA_ "U_U611_U625_MY20_Diesel_Rx" SG_ 1461 PSCM_GWOnBoardTester 1;
BA_ "U_CX482_CX483_MY20_Hev_Rx" SG_ 1461 PSCM_GWOnBoardTester 1;
BA_ "U_CX482_CX483_MY20_Gas_Rx" SG_ 1461 PSCM_GWOnBoardTester 1;
BA_ "U_CX482_CX483_MY20_Diesel_Rx" SG_ 1461 PSCM_GWOnBoardTester 1;
BA_ "U_B500_MY18_Diesel_Rx" SG_ 1461 PSCM_GWOnBoardTester 1;
BA_ "U_B500_MY18_Gas_Rx" SG_ 1461 PSCM_GWOnBoardTester 1;
BA_ "U_C490_MY18_Rx" SG_ 1461 PSCM_GWOnBoardTester 1;
BA_ "U_B562_MY18_Gas_Rx" SG_ 1461 PSCM_GWOnBoardTester 1;
BA_ "U_C519_MY18_5_Gas_Rx" SG_ 1461 PSCM_GWOnBoardTester 1;
BA_ "U_C519_MY18_5_Diesel_Rx" SG_ 1461 PSCM_GWOnBoardTester 1;
BA_ "U_B515_MCA_MY17_Gas_Rx" SG_ 1461 PSCM_GWOnBoardTester 1;
BA_ "U_B515_MCA_MY17_Diesel_Rx" SG_ 1461 PSCM_GWOnBoardTester 1;
BA_ "ContentDependant" SG_ 1461 PSCM_GWOnBoardTester 1;
BA_ "GenSigStartValue" SG_ 1461 PSCM_GWOnBoardTester 255;
BA_ "U_U611_U625_MY20_Phev_Tx" SG_ 1461 PSCM_GWNMProxy 1;
BA_ "U_CX482_CX483_MY20_Hev_Tx" SG_ 1461 PSCM_GWNMProxy 1;
BA_ "U_CX482_CX483_MY20_Gas_Tx" SG_ 1461 PSCM_GWNMProxy 1;
BA_ "U_CX482_CX483_MY20_Diesel_Tx" SG_ 1461 PSCM_GWNMProxy 1;
BA_ "U_U611_U625_MY20_Hev_Tx" SG_ 1461 PSCM_GWNMProxy 1;
BA_ "U_U611_U625_MY20_Gas_Tx" SG_ 1461 PSCM_GWNMProxy 1;
BA_ "U_U611_U625_MY20_Diesel_Tx" SG_ 1461 PSCM_GWNMProxy 1;
BA_ "U_B500_MY18_Diesel_Tx" SG_ 1461 PSCM_GWNMProxy 1;
BA_ "U_B500_MY18_Gas_Tx" SG_ 1461 PSCM_GWNMProxy 1;
BA_ "U_C490_MY18_Tx" SG_ 1461 PSCM_GWNMProxy 1;
BA_ "U_B562_MY18_Gas_Tx" SG_ 1461 PSCM_GWNMProxy 1;
BA_ "U_C519_MY18_5_Gas_Tx" SG_ 1461 PSCM_GWNMProxy 1;
BA_ "U_C519_MY18_5_Diesel_Tx" SG_ 1461 PSCM_GWNMProxy 1;
BA_ "U_B479_MY17_Diesel_Tx" SG_ 1461 PSCM_GWNMProxy 1;
BA_ "U_B479_MY17_Gas_Tx" SG_ 1461 PSCM_GWNMProxy 1;
BA_ "U_B479_MY17_Diesel_Rx" SG_ 1461 PSCM_GWNMProxy 1;
BA_ "U_B479_MY17_Gas_Rx" SG_ 1461 PSCM_GWNMProxy 1;
BA_ "U_U611_U625_MY20_Phev_Rx" SG_ 1461 PSCM_GWNMProxy 1;
BA_ "U_U611_U625_MY20_Hev_Rx" SG_ 1461 PSCM_GWNMProxy 1;
BA_ "U_U611_U625_MY20_Gas_Rx" SG_ 1461 PSCM_GWNMProxy 1;
BA_ "U_U611_U625_MY20_Diesel_Rx" SG_ 1461 PSCM_GWNMProxy 1;
BA_ "U_CX482_CX483_MY20_Hev_Rx" SG_ 1461 PSCM_GWNMProxy 1;
BA_ "U_CX482_CX483_MY20_Gas_Rx" SG_ 1461 PSCM_GWNMProxy 1;
BA_ "U_CX482_CX483_MY20_Diesel_Rx" SG_ 1461 PSCM_GWNMProxy 1;
BA_ "U_B500_MY18_Diesel_Rx" SG_ 1461 PSCM_GWNMProxy 1;
BA_ "U_B500_MY18_Gas_Rx" SG_ 1461 PSCM_GWNMProxy 1;
BA_ "U_C490_MY18_Rx" SG_ 1461 PSCM_GWNMProxy 1;
BA_ "U_B562_MY18_Gas_Rx" SG_ 1461 PSCM_GWNMProxy 1;
BA_ "U_C519_MY18_5_Gas_Rx" SG_ 1461 PSCM_GWNMProxy 1;
BA_ "U_C519_MY18_5_Diesel_Rx" SG_ 1461 PSCM_GWNMProxy 1;
BA_ "U_B515_MCA_MY17_Gas_Rx" SG_ 1461 PSCM_GWNMProxy 1;
BA_ "U_B515_MCA_MY17_Diesel_Rx" SG_ 1461 PSCM_GWNMProxy 1;
BA_ "ContentDependant" SG_ 1461 PSCM_GWNMProxy 1;
BA_ "GenSigStartValue" SG_ 1461 PSCM_GWNMProxy 255;
BA_ "U_U611_U625_MY20_Phev_Tx" SG_ 1461 PSCM_AutoSarNMReserved4 1;
BA_ "U_CX482_CX483_MY20_Hev_Tx" SG_ 1461 PSCM_AutoSarNMReserved4 1;
BA_ "U_CX482_CX483_MY20_Gas_Tx" SG_ 1461 PSCM_AutoSarNMReserved4 1;
BA_ "U_CX482_CX483_MY20_Diesel_Tx" SG_ 1461 PSCM_AutoSarNMReserved4 1;
BA_ "U_U611_U625_MY20_Hev_Tx" SG_ 1461 PSCM_AutoSarNMReserved4 1;
BA_ "U_U611_U625_MY20_Gas_Tx" SG_ 1461 PSCM_AutoSarNMReserved4 1;
BA_ "U_U611_U625_MY20_Diesel_Tx" SG_ 1461 PSCM_AutoSarNMReserved4 1;
BA_ "U_B500_MY18_Diesel_Tx" SG_ 1461 PSCM_AutoSarNMReserved4 1;
BA_ "U_B500_MY18_Gas_Tx" SG_ 1461 PSCM_AutoSarNMReserved4 1;
BA_ "U_C490_MY18_Tx" SG_ 1461 PSCM_AutoSarNMReserved4 1;
BA_ "U_B562_MY18_Gas_Tx" SG_ 1461 PSCM_AutoSarNMReserved4 1;
BA_ "U_C519_MY18_5_Gas_Tx" SG_ 1461 PSCM_AutoSarNMReserved4 1;
BA_ "U_C519_MY18_5_Diesel_Tx" SG_ 1461 PSCM_AutoSarNMReserved4 1;
BA_ "U_B479_MY17_Diesel_Tx" SG_ 1461 PSCM_AutoSarNMReserved4 1;
BA_ "U_B479_MY17_Gas_Tx" SG_ 1461 PSCM_AutoSarNMReserved4 1;
BA_ "U_B479_MY17_Diesel_Rx" SG_ 1461 PSCM_AutoSarNMReserved4 1;
BA_ "U_B479_MY17_Gas_Rx" SG_ 1461 PSCM_AutoSarNMReserved4 1;
BA_ "U_U611_U625_MY20_Phev_Rx" SG_ 1461 PSCM_AutoSarNMReserved4 1;
BA_ "U_U611_U625_MY20_Hev_Rx" SG_ 1461 PSCM_AutoSarNMReserved4 1;
BA_ "U_U611_U625_MY20_Gas_Rx" SG_ 1461 PSCM_AutoSarNMReserved4 1;
BA_ "U_U611_U625_MY20_Diesel_Rx" SG_ 1461 PSCM_AutoSarNMReserved4 1;
BA_ "U_CX482_CX483_MY20_Hev_Rx" SG_ 1461 PSCM_AutoSarNMReserved4 1;
BA_ "U_CX482_CX483_MY20_Gas_Rx" SG_ 1461 PSCM_AutoSarNMReserved4 1;
BA_ "U_CX482_CX483_MY20_Diesel_Rx" SG_ 1461 PSCM_AutoSarNMReserved4 1;
BA_ "U_B500_MY18_Diesel_Rx" SG_ 1461 PSCM_AutoSarNMReserved4 1;
BA_ "U_B500_MY18_Gas_Rx" SG_ 1461 PSCM_AutoSarNMReserved4 1;
BA_ "U_C490_MY18_Rx" SG_ 1461 PSCM_AutoSarNMReserved4 1;
BA_ "U_B562_MY18_Gas_Rx" SG_ 1461 PSCM_AutoSarNMReserved4 1;
BA_ "U_C519_MY18_5_Gas_Rx" SG_ 1461 PSCM_AutoSarNMReserved4 1;
BA_ "U_C519_MY18_5_Diesel_Rx" SG_ 1461 PSCM_AutoSarNMReserved4 1;
BA_ "U_B515_MCA_MY17_Gas_Rx" SG_ 1461 PSCM_AutoSarNMReserved4 1;
BA_ "U_B515_MCA_MY17_Diesel_Rx" SG_ 1461 PSCM_AutoSarNMReserved4 1;
BA_ "ContentDependant" SG_ 1461 PSCM_AutoSarNMReserved4 1;
BA_ "GenSigStartValue" SG_ 1461 PSCM_AutoSarNMReserved4 255;
BA_ "U_U611_U625_MY20_Phev_Tx" SG_ 1461 PSCM_AutoSarNMReserved3 1;
BA_ "U_CX482_CX483_MY20_Hev_Tx" SG_ 1461 PSCM_AutoSarNMReserved3 1;
BA_ "U_CX482_CX483_MY20_Gas_Tx" SG_ 1461 PSCM_AutoSarNMReserved3 1;
BA_ "U_CX482_CX483_MY20_Diesel_Tx" SG_ 1461 PSCM_AutoSarNMReserved3 1;
BA_ "U_U611_U625_MY20_Hev_Tx" SG_ 1461 PSCM_AutoSarNMReserved3 1;
BA_ "U_U611_U625_MY20_Gas_Tx" SG_ 1461 PSCM_AutoSarNMReserved3 1;
BA_ "U_U611_U625_MY20_Diesel_Tx" SG_ 1461 PSCM_AutoSarNMReserved3 1;
BA_ "U_B500_MY18_Diesel_Tx" SG_ 1461 PSCM_AutoSarNMReserved3 1;
BA_ "U_B500_MY18_Gas_Tx" SG_ 1461 PSCM_AutoSarNMReserved3 1;
BA_ "U_C490_MY18_Tx" SG_ 1461 PSCM_AutoSarNMReserved3 1;
BA_ "U_B562_MY18_Gas_Tx" SG_ 1461 PSCM_AutoSarNMReserved3 1;
BA_ "U_C519_MY18_5_Gas_Tx" SG_ 1461 PSCM_AutoSarNMReserved3 1;
BA_ "U_C519_MY18_5_Diesel_Tx" SG_ 1461 PSCM_AutoSarNMReserved3 1;
BA_ "U_B479_MY17_Diesel_Tx" SG_ 1461 PSCM_AutoSarNMReserved3 1;
BA_ "U_B479_MY17_Gas_Tx" SG_ 1461 PSCM_AutoSarNMReserved3 1;
BA_ "U_B479_MY17_Diesel_Rx" SG_ 1461 PSCM_AutoSarNMReserved3 1;
BA_ "U_B479_MY17_Gas_Rx" SG_ 1461 PSCM_AutoSarNMReserved3 1;
BA_ "U_U611_U625_MY20_Phev_Rx" SG_ 1461 PSCM_AutoSarNMReserved3 1;
BA_ "U_U611_U625_MY20_Hev_Rx" SG_ 1461 PSCM_AutoSarNMReserved3 1;
BA_ "U_U611_U625_MY20_Gas_Rx" SG_ 1461 PSCM_AutoSarNMReserved3 1;
BA_ "U_U611_U625_MY20_Diesel_Rx" SG_ 1461 PSCM_AutoSarNMReserved3 1;
BA_ "U_CX482_CX483_MY20_Hev_Rx" SG_ 1461 PSCM_AutoSarNMReserved3 1;
BA_ "U_CX482_CX483_MY20_Gas_Rx" SG_ 1461 PSCM_AutoSarNMReserved3 1;
BA_ "U_CX482_CX483_MY20_Diesel_Rx" SG_ 1461 PSCM_AutoSarNMReserved3 1;
BA_ "U_B500_MY18_Diesel_Rx" SG_ 1461 PSCM_AutoSarNMReserved3 1;
BA_ "U_B500_MY18_Gas_Rx" SG_ 1461 PSCM_AutoSarNMReserved3 1;
BA_ "U_C490_MY18_Rx" SG_ 1461 PSCM_AutoSarNMReserved3 1;
BA_ "U_B562_MY18_Gas_Rx" SG_ 1461 PSCM_AutoSarNMReserved3 1;
BA_ "U_C519_MY18_5_Gas_Rx" SG_ 1461 PSCM_AutoSarNMReserved3 1;
BA_ "U_C519_MY18_5_Diesel_Rx" SG_ 1461 PSCM_AutoSarNMReserved3 1;
BA_ "U_B515_MCA_MY17_Gas_Rx" SG_ 1461 PSCM_AutoSarNMReserved3 1;
BA_ "U_B515_MCA_MY17_Diesel_Rx" SG_ 1461 PSCM_AutoSarNMReserved3 1;
BA_ "ContentDependant" SG_ 1461 PSCM_AutoSarNMReserved3 1;
BA_ "GenSigStartValue" SG_ 1461 PSCM_AutoSarNMReserved3 255;
BA_ "U_U611_U625_MY20_Phev_Tx" SG_ 1461 PSCM_AutoSarNMReserved2 1;
BA_ "U_CX482_CX483_MY20_Hev_Tx" SG_ 1461 PSCM_AutoSarNMReserved2 1;
BA_ "U_CX482_CX483_MY20_Gas_Tx" SG_ 1461 PSCM_AutoSarNMReserved2 1;
BA_ "U_CX482_CX483_MY20_Diesel_Tx" SG_ 1461 PSCM_AutoSarNMReserved2 1;
BA_ "U_U611_U625_MY20_Hev_Tx" SG_ 1461 PSCM_AutoSarNMReserved2 1;
BA_ "U_U611_U625_MY20_Gas_Tx" SG_ 1461 PSCM_AutoSarNMReserved2 1;
BA_ "U_U611_U625_MY20_Diesel_Tx" SG_ 1461 PSCM_AutoSarNMReserved2 1;
BA_ "U_B500_MY18_Diesel_Tx" SG_ 1461 PSCM_AutoSarNMReserved2 1;
BA_ "U_B500_MY18_Gas_Tx" SG_ 1461 PSCM_AutoSarNMReserved2 1;
BA_ "U_C490_MY18_Tx" SG_ 1461 PSCM_AutoSarNMReserved2 1;
BA_ "U_B562_MY18_Gas_Tx" SG_ 1461 PSCM_AutoSarNMReserved2 1;
BA_ "U_C519_MY18_5_Gas_Tx" SG_ 1461 PSCM_AutoSarNMReserved2 1;
BA_ "U_C519_MY18_5_Diesel_Tx" SG_ 1461 PSCM_AutoSarNMReserved2 1;
BA_ "U_B479_MY17_Diesel_Tx" SG_ 1461 PSCM_AutoSarNMReserved2 1;
BA_ "U_B479_MY17_Gas_Tx" SG_ 1461 PSCM_AutoSarNMReserved2 1;
BA_ "U_B479_MY17_Diesel_Rx" SG_ 1461 PSCM_AutoSarNMReserved2 1;
BA_ "U_B479_MY17_Gas_Rx" SG_ 1461 PSCM_AutoSarNMReserved2 1;
BA_ "U_U611_U625_MY20_Phev_Rx" SG_ 1461 PSCM_AutoSarNMReserved2 1;
BA_ "U_U611_U625_MY20_Hev_Rx" SG_ 1461 PSCM_AutoSarNMReserved2 1;
BA_ "U_U611_U625_MY20_Gas_Rx" SG_ 1461 PSCM_AutoSarNMReserved2 1;
BA_ "U_U611_U625_MY20_Diesel_Rx" SG_ 1461 PSCM_AutoSarNMReserved2 1;
BA_ "U_CX482_CX483_MY20_Hev_Rx" SG_ 1461 PSCM_AutoSarNMReserved2 1;
BA_ "U_CX482_CX483_MY20_Gas_Rx" SG_ 1461 PSCM_AutoSarNMReserved2 1;
BA_ "U_CX482_CX483_MY20_Diesel_Rx" SG_ 1461 PSCM_AutoSarNMReserved2 1;
BA_ "U_B500_MY18_Diesel_Rx" SG_ 1461 PSCM_AutoSarNMReserved2 1;
BA_ "U_B500_MY18_Gas_Rx" SG_ 1461 PSCM_AutoSarNMReserved2 1;
BA_ "U_C490_MY18_Rx" SG_ 1461 PSCM_AutoSarNMReserved2 1;
BA_ "U_B562_MY18_Gas_Rx" SG_ 1461 PSCM_AutoSarNMReserved2 1;
BA_ "U_C519_MY18_5_Gas_Rx" SG_ 1461 PSCM_AutoSarNMReserved2 1;
BA_ "U_C519_MY18_5_Diesel_Rx" SG_ 1461 PSCM_AutoSarNMReserved2 1;
BA_ "U_B515_MCA_MY17_Gas_Rx" SG_ 1461 PSCM_AutoSarNMReserved2 1;
BA_ "U_B515_MCA_MY17_Diesel_Rx" SG_ 1461 PSCM_AutoSarNMReserved2 1;
BA_ "ContentDependant" SG_ 1461 PSCM_AutoSarNMReserved2 1;
BA_ "GenSigStartValue" SG_ 1461 PSCM_AutoSarNMReserved2 255;
BA_ "U_U611_U625_MY20_Phev_Tx" SG_ 1461 PSCM_AutoSarNMReserved1 1;
BA_ "U_CX482_CX483_MY20_Hev_Tx" SG_ 1461 PSCM_AutoSarNMReserved1 1;
BA_ "U_CX482_CX483_MY20_Gas_Tx" SG_ 1461 PSCM_AutoSarNMReserved1 1;
BA_ "U_CX482_CX483_MY20_Diesel_Tx" SG_ 1461 PSCM_AutoSarNMReserved1 1;
BA_ "U_U611_U625_MY20_Hev_Tx" SG_ 1461 PSCM_AutoSarNMReserved1 1;
BA_ "U_U611_U625_MY20_Gas_Tx" SG_ 1461 PSCM_AutoSarNMReserved1 1;
BA_ "U_U611_U625_MY20_Diesel_Tx" SG_ 1461 PSCM_AutoSarNMReserved1 1;
BA_ "U_B500_MY18_Diesel_Tx" SG_ 1461 PSCM_AutoSarNMReserved1 1;
BA_ "U_B500_MY18_Gas_Tx" SG_ 1461 PSCM_AutoSarNMReserved1 1;
BA_ "U_C490_MY18_Tx" SG_ 1461 PSCM_AutoSarNMReserved1 1;
BA_ "U_B562_MY18_Gas_Tx" SG_ 1461 PSCM_AutoSarNMReserved1 1;
BA_ "U_C519_MY18_5_Gas_Tx" SG_ 1461 PSCM_AutoSarNMReserved1 1;
BA_ "U_C519_MY18_5_Diesel_Tx" SG_ 1461 PSCM_AutoSarNMReserved1 1;
BA_ "U_B479_MY17_Diesel_Tx" SG_ 1461 PSCM_AutoSarNMReserved1 1;
BA_ "U_B479_MY17_Gas_Tx" SG_ 1461 PSCM_AutoSarNMReserved1 1;
BA_ "U_B479_MY17_Diesel_Rx" SG_ 1461 PSCM_AutoSarNMReserved1 1;
BA_ "U_B479_MY17_Gas_Rx" SG_ 1461 PSCM_AutoSarNMReserved1 1;
BA_ "U_U611_U625_MY20_Phev_Rx" SG_ 1461 PSCM_AutoSarNMReserved1 1;
BA_ "U_U611_U625_MY20_Hev_Rx" SG_ 1461 PSCM_AutoSarNMReserved1 1;
BA_ "U_U611_U625_MY20_Gas_Rx" SG_ 1461 PSCM_AutoSarNMReserved1 1;
BA_ "U_U611_U625_MY20_Diesel_Rx" SG_ 1461 PSCM_AutoSarNMReserved1 1;
BA_ "U_CX482_CX483_MY20_Hev_Rx" SG_ 1461 PSCM_AutoSarNMReserved1 1;
BA_ "U_CX482_CX483_MY20_Gas_Rx" SG_ 1461 PSCM_AutoSarNMReserved1 1;
BA_ "U_CX482_CX483_MY20_Diesel_Rx" SG_ 1461 PSCM_AutoSarNMReserved1 1;
BA_ "U_B500_MY18_Diesel_Rx" SG_ 1461 PSCM_AutoSarNMReserved1 1;
BA_ "U_B500_MY18_Gas_Rx" SG_ 1461 PSCM_AutoSarNMReserved1 1;
BA_ "U_C490_MY18_Rx" SG_ 1461 PSCM_AutoSarNMReserved1 1;
BA_ "U_B562_MY18_Gas_Rx" SG_ 1461 PSCM_AutoSarNMReserved1 1;
BA_ "U_C519_MY18_5_Gas_Rx" SG_ 1461 PSCM_AutoSarNMReserved1 1;
BA_ "U_C519_MY18_5_Diesel_Rx" SG_ 1461 PSCM_AutoSarNMReserved1 1;
BA_ "U_B515_MCA_MY17_Gas_Rx" SG_ 1461 PSCM_AutoSarNMReserved1 1;
BA_ "U_B515_MCA_MY17_Diesel_Rx" SG_ 1461 PSCM_AutoSarNMReserved1 1;
BA_ "ContentDependant" SG_ 1461 PSCM_AutoSarNMReserved1 1;
BA_ "GenSigStartValue" SG_ 1461 PSCM_AutoSarNMReserved1 255;
BA_ "U_U611_U625_MY20_Phev_Tx" SG_ 1461 PSCM_AutoSarNMNodeId 1;
BA_ "U_CX482_CX483_MY20_Hev_Tx" SG_ 1461 PSCM_AutoSarNMNodeId 1;
BA_ "U_CX482_CX483_MY20_Gas_Tx" SG_ 1461 PSCM_AutoSarNMNodeId 1;
BA_ "U_CX482_CX483_MY20_Diesel_Tx" SG_ 1461 PSCM_AutoSarNMNodeId 1;
BA_ "U_U611_U625_MY20_Hev_Tx" SG_ 1461 PSCM_AutoSarNMNodeId 1;
BA_ "U_U611_U625_MY20_Gas_Tx" SG_ 1461 PSCM_AutoSarNMNodeId 1;
BA_ "U_U611_U625_MY20_Diesel_Tx" SG_ 1461 PSCM_AutoSarNMNodeId 1;
BA_ "U_B500_MY18_Diesel_Tx" SG_ 1461 PSCM_AutoSarNMNodeId 1;
BA_ "U_B500_MY18_Gas_Tx" SG_ 1461 PSCM_AutoSarNMNodeId 1;
BA_ "U_C490_MY18_Tx" SG_ 1461 PSCM_AutoSarNMNodeId 1;
BA_ "U_B562_MY18_Gas_Tx" SG_ 1461 PSCM_AutoSarNMNodeId 1;
BA_ "U_C519_MY18_5_Gas_Tx" SG_ 1461 PSCM_AutoSarNMNodeId 1;
BA_ "U_C519_MY18_5_Diesel_Tx" SG_ 1461 PSCM_AutoSarNMNodeId 1;
BA_ "U_B479_MY17_Diesel_Tx" SG_ 1461 PSCM_AutoSarNMNodeId 1;
BA_ "U_B479_MY17_Gas_Tx" SG_ 1461 PSCM_AutoSarNMNodeId 1;
BA_ "U_B479_MY17_Diesel_Rx" SG_ 1461 PSCM_AutoSarNMNodeId 1;
BA_ "U_B479_MY17_Gas_Rx" SG_ 1461 PSCM_AutoSarNMNodeId 1;
BA_ "U_U611_U625_MY20_Phev_Rx" SG_ 1461 PSCM_AutoSarNMNodeId 1;
BA_ "U_U611_U625_MY20_Hev_Rx" SG_ 1461 PSCM_AutoSarNMNodeId 1;
BA_ "U_U611_U625_MY20_Gas_Rx" SG_ 1461 PSCM_AutoSarNMNodeId 1;
BA_ "U_U611_U625_MY20_Diesel_Rx" SG_ 1461 PSCM_AutoSarNMNodeId 1;
BA_ "U_CX482_CX483_MY20_Hev_Rx" SG_ 1461 PSCM_AutoSarNMNodeId 1;
BA_ "U_CX482_CX483_MY20_Gas_Rx" SG_ 1461 PSCM_AutoSarNMNodeId 1;
BA_ "U_CX482_CX483_MY20_Diesel_Rx" SG_ 1461 PSCM_AutoSarNMNodeId 1;
BA_ "U_B500_MY18_Diesel_Rx" SG_ 1461 PSCM_AutoSarNMNodeId 1;
BA_ "U_B500_MY18_Gas_Rx" SG_ 1461 PSCM_AutoSarNMNodeId 1;
BA_ "U_C490_MY18_Rx" SG_ 1461 PSCM_AutoSarNMNodeId 1;
BA_ "U_B562_MY18_Gas_Rx" SG_ 1461 PSCM_AutoSarNMNodeId 1;
BA_ "U_C519_MY18_5_Gas_Rx" SG_ 1461 PSCM_AutoSarNMNodeId 1;
BA_ "U_C519_MY18_5_Diesel_Rx" SG_ 1461 PSCM_AutoSarNMNodeId 1;
BA_ "U_B515_MCA_MY17_Gas_Rx" SG_ 1461 PSCM_AutoSarNMNodeId 1;
BA_ "U_B515_MCA_MY17_Diesel_Rx" SG_ 1461 PSCM_AutoSarNMNodeId 1;
BA_ "ContentDependant" SG_ 1461 PSCM_AutoSarNMNodeId 1;
BA_ "GenSigStartValue" SG_ 1461 PSCM_AutoSarNMNodeId 181;
BA_ "U_U611_U625_MY20_Phev_Tx" SG_ 1461 PSCM_AutoSarNMControl 1;
BA_ "U_CX482_CX483_MY20_Hev_Tx" SG_ 1461 PSCM_AutoSarNMControl 1;
BA_ "U_CX482_CX483_MY20_Gas_Tx" SG_ 1461 PSCM_AutoSarNMControl 1;
BA_ "U_CX482_CX483_MY20_Diesel_Tx" SG_ 1461 PSCM_AutoSarNMControl 1;
BA_ "U_U611_U625_MY20_Hev_Tx" SG_ 1461 PSCM_AutoSarNMControl 1;
BA_ "U_U611_U625_MY20_Gas_Tx" SG_ 1461 PSCM_AutoSarNMControl 1;
BA_ "U_U611_U625_MY20_Diesel_Tx" SG_ 1461 PSCM_AutoSarNMControl 1;
BA_ "U_B500_MY18_Diesel_Tx" SG_ 1461 PSCM_AutoSarNMControl 1;
BA_ "U_B500_MY18_Gas_Tx" SG_ 1461 PSCM_AutoSarNMControl 1;
BA_ "U_C490_MY18_Tx" SG_ 1461 PSCM_AutoSarNMControl 1;
BA_ "U_B562_MY18_Gas_Tx" SG_ 1461 PSCM_AutoSarNMControl 1;
BA_ "U_C519_MY18_5_Gas_Tx" SG_ 1461 PSCM_AutoSarNMControl 1;
BA_ "U_C519_MY18_5_Diesel_Tx" SG_ 1461 PSCM_AutoSarNMControl 1;
BA_ "U_B479_MY17_Diesel_Tx" SG_ 1461 PSCM_AutoSarNMControl 1;
BA_ "U_B479_MY17_Gas_Tx" SG_ 1461 PSCM_AutoSarNMControl 1;
BA_ "U_U611_U625_MY20_Phev_Rx" SG_ 1461 PSCM_AutoSarNMControl 1;
BA_ "U_U611_U625_MY20_Hev_Rx" SG_ 1461 PSCM_AutoSarNMControl 1;
BA_ "U_U611_U625_MY20_Gas_Rx" SG_ 1461 PSCM_AutoSarNMControl 1;
BA_ "U_U611_U625_MY20_Diesel_Rx" SG_ 1461 PSCM_AutoSarNMControl 1;
BA_ "U_CX482_CX483_MY20_Hev_Rx" SG_ 1461 PSCM_AutoSarNMControl 1;
BA_ "U_CX482_CX483_MY20_Gas_Rx" SG_ 1461 PSCM_AutoSarNMControl 1;
BA_ "U_CX482_CX483_MY20_Diesel_Rx" SG_ 1461 PSCM_AutoSarNMControl 1;
BA_ "U_B500_MY18_Diesel_Rx" SG_ 1461 PSCM_AutoSarNMControl 1;
BA_ "U_B500_MY18_Gas_Rx" SG_ 1461 PSCM_AutoSarNMControl 1;
BA_ "U_C490_MY18_Rx" SG_ 1461 PSCM_AutoSarNMControl 1;
BA_ "U_B562_MY18_Gas_Rx" SG_ 1461 PSCM_AutoSarNMControl 1;
BA_ "U_C519_MY18_5_Gas_Rx" SG_ 1461 PSCM_AutoSarNMControl 1;
BA_ "U_C519_MY18_5_Diesel_Rx" SG_ 1461 PSCM_AutoSarNMControl 1;
BA_ "U_B515_MCA_MY17_Gas_Rx" SG_ 1461 PSCM_AutoSarNMControl 1;
BA_ "U_B515_MCA_MY17_Diesel_Rx" SG_ 1461 PSCM_AutoSarNMControl 1;
BA_ "U_B479_MY17_Diesel_Rx" SG_ 1461 PSCM_AutoSarNMControl 1;
BA_ "U_B479_MY17_Gas_Rx" SG_ 1461 PSCM_AutoSarNMControl 1;
BA_ "ContentDependant" SG_ 1461 PSCM_AutoSarNMControl 1;
BA_ "U_CX482_CX483_MY20_Hev_Tx" SG_ 390 AccBrkTot_A_Rq 1;
BA_ "U_CX482_CX483_MY20_Gas_Tx" SG_ 390 AccBrkTot_A_Rq 1;
BA_ "U_CX482_CX483_MY20_Diesel_Tx" SG_ 390 AccBrkTot_A_Rq 1;
BA_ "U_U611_U625_MY20_Hev_Tx" SG_ 390 AccBrkTot_A_Rq 1;
BA_ "U_U611_U625_MY20_Gas_Tx" SG_ 390 AccBrkTot_A_Rq 1;
BA_ "U_U611_U625_MY20_Diesel_Tx" SG_ 390 AccBrkTot_A_Rq 1;
BA_ "U_C519_MY18_5_Gas_Tx" SG_ 390 AccBrkTot_A_Rq 1;
BA_ "U_C519_MY18_5_Diesel_Tx" SG_ 390 AccBrkTot_A_Rq 1;
BA_ "U_B479_MY17_Diesel_Tx" SG_ 390 AccBrkTot_A_Rq 1;
BA_ "U_B479_MY17_Gas_Tx" SG_ 390 AccBrkTot_A_Rq 1;
BA_ "U_CX482_CX483_MY20_Hev_Rx" SG_ 390 AccBrkTot_A_Rq 1;
BA_ "U_CX482_CX483_MY20_Gas_Rx" SG_ 390 AccBrkTot_A_Rq 1;
BA_ "U_CX482_CX483_MY20_Diesel_Rx" SG_ 390 AccBrkTot_A_Rq 1;
BA_ "U_U611_U625_MY20_Hev_Rx" SG_ 390 AccBrkTot_A_Rq 1;
BA_ "U_U611_U625_MY20_Gas_Rx" SG_ 390 AccBrkTot_A_Rq 1;
BA_ "U_U611_U625_MY20_Diesel_Rx" SG_ 390 AccBrkTot_A_Rq 1;
BA_ "U_C519_MY18_5_Gas_Rx" SG_ 390 AccBrkTot_A_Rq 1;
BA_ "U_C519_MY18_5_Diesel_Rx" SG_ 390 AccBrkTot_A_Rq 1;
BA_ "U_B479_MY17_Diesel_Rx" SG_ 390 AccBrkTot_A_Rq 1;
BA_ "U_B479_MY17_Gas_Rx" SG_ 390 AccBrkTot_A_Rq 1;
BA_ "GenSigStartValue" SG_ 390 AccBrkTot_A_Rq 5129;
BA_ "U_CX482_CX483_MY20_Hev_Tx" SG_ 390 AccPrpl_A_Pred 1;
BA_ "U_CX482_CX483_MY20_Gas_Tx" SG_ 390 AccPrpl_A_Pred 1;
BA_ "U_CX482_CX483_MY20_Diesel_Tx" SG_ 390 AccPrpl_A_Pred 1;
BA_ "U_U611_U625_MY20_Hev_Tx" SG_ 390 AccPrpl_A_Pred 1;
BA_ "U_U611_U625_MY20_Gas_Tx" SG_ 390 AccPrpl_A_Pred 1;
BA_ "U_U611_U625_MY20_Diesel_Tx" SG_ 390 AccPrpl_A_Pred 1;
BA_ "U_C519_MY18_5_Gas_Tx" SG_ 390 AccPrpl_A_Pred 1;
BA_ "U_C519_MY18_5_Diesel_Tx" SG_ 390 AccPrpl_A_Pred 1;
BA_ "U_B479_MY17_Diesel_Tx" SG_ 390 AccPrpl_A_Pred 1;
BA_ "U_B479_MY17_Gas_Tx" SG_ 390 AccPrpl_A_Pred 1;
BA_ "U_CX482_CX483_MY20_Hev_Tx" SG_ 390 AccVeh_V_Trg 1;
BA_ "U_CX482_CX483_MY20_Gas_Tx" SG_ 390 AccVeh_V_Trg 1;
BA_ "U_CX482_CX483_MY20_Diesel_Tx" SG_ 390 AccVeh_V_Trg 1;
BA_ "U_U611_U625_MY20_Hev_Tx" SG_ 390 AccVeh_V_Trg 1;
BA_ "U_U611_U625_MY20_Gas_Tx" SG_ 390 AccVeh_V_Trg 1;
BA_ "U_U611_U625_MY20_Diesel_Tx" SG_ 390 AccVeh_V_Trg 1;
BA_ "U_C519_MY18_5_Gas_Tx" SG_ 390 AccVeh_V_Trg 1;
BA_ "U_C519_MY18_5_Diesel_Tx" SG_ 390 AccVeh_V_Trg 1;
BA_ "U_B479_MY17_Diesel_Tx" SG_ 390 AccVeh_V_Trg 1;
BA_ "U_B479_MY17_Gas_Tx" SG_ 390 AccVeh_V_Trg 1;
BA_ "U_CX482_CX483_MY20_Hev_Tx" SG_ 390 AccBrkPrkEl_B_Rq 1;
BA_ "U_CX482_CX483_MY20_Gas_Tx" SG_ 390 AccBrkPrkEl_B_Rq 1;
BA_ "U_CX482_CX483_MY20_Diesel_Tx" SG_ 390 AccBrkPrkEl_B_Rq 1;
BA_ "U_U611_U625_MY20_Hev_Tx" SG_ 390 AccBrkPrkEl_B_Rq 1;
BA_ "U_U611_U625_MY20_Gas_Tx" SG_ 390 AccBrkPrkEl_B_Rq 1;
BA_ "U_U611_U625_MY20_Diesel_Tx" SG_ 390 AccBrkPrkEl_B_Rq 1;
BA_ "U_C519_MY18_5_Gas_Tx" SG_ 390 AccBrkPrkEl_B_Rq 1;
BA_ "U_C519_MY18_5_Diesel_Tx" SG_ 390 AccBrkPrkEl_B_Rq 1;
BA_ "U_B479_MY17_Diesel_Tx" SG_ 390 AccBrkPrkEl_B_Rq 1;
BA_ "U_B479_MY17_Gas_Tx" SG_ 390 AccBrkPrkEl_B_Rq 1;
BA_ "U_CX482_CX483_MY20_Hev_Rx" SG_ 390 AccBrkPrkEl_B_Rq 1;
BA_ "U_CX482_CX483_MY20_Gas_Rx" SG_ 390 AccBrkPrkEl_B_Rq 1;
BA_ "U_CX482_CX483_MY20_Diesel_Rx" SG_ 390 AccBrkPrkEl_B_Rq 1;
BA_ "U_U611_U625_MY20_Hev_Rx" SG_ 390 AccBrkPrkEl_B_Rq 1;
BA_ "U_U611_U625_MY20_Gas_Rx" SG_ 390 AccBrkPrkEl_B_Rq 1;
BA_ "U_U611_U625_MY20_Diesel_Rx" SG_ 390 AccBrkPrkEl_B_Rq 1;
BA_ "U_C519_MY18_5_Gas_Rx" SG_ 390 AccBrkPrkEl_B_Rq 1;
BA_ "U_C519_MY18_5_Diesel_Rx" SG_ 390 AccBrkPrkEl_B_Rq 1;
BA_ "U_B479_MY17_Diesel_Rx" SG_ 390 AccBrkPrkEl_B_Rq 1;
BA_ "U_B479_MY17_Gas_Rx" SG_ 390 AccBrkPrkEl_B_Rq 1;
BA_ "U_CX482_CX483_MY20_Hev_Tx" SG_ 390 Cmbb_B_Enbl 1;
BA_ "U_CX482_CX483_MY20_Gas_Tx" SG_ 390 Cmbb_B_Enbl 1;
BA_ "U_CX482_CX483_MY20_Diesel_Tx" SG_ 390 Cmbb_B_Enbl 1;
BA_ "U_U611_U625_MY20_Hev_Tx" SG_ 390 Cmbb_B_Enbl 1;
BA_ "U_U611_U625_MY20_Gas_Tx" SG_ 390 Cmbb_B_Enbl 1;
BA_ "U_U611_U625_MY20_Diesel_Tx" SG_ 390 Cmbb_B_Enbl 1;
BA_ "U_C519_MY18_5_Gas_Tx" SG_ 390 Cmbb_B_Enbl 1;
BA_ "U_C519_MY18_5_Diesel_Tx" SG_ 390 Cmbb_B_Enbl 1;
BA_ "U_B479_MY17_Diesel_Tx" SG_ 390 Cmbb_B_Enbl 1;
BA_ "U_B479_MY17_Gas_Tx" SG_ 390 Cmbb_B_Enbl 1;
BA_ "U_CX482_CX483_MY20_Hev_Rx" SG_ 390 Cmbb_B_Enbl 1;
BA_ "U_CX482_CX483_MY20_Gas_Rx" SG_ 390 Cmbb_B_Enbl 1;
BA_ "U_CX482_CX483_MY20_Diesel_Rx" SG_ 390 Cmbb_B_Enbl 1;
BA_ "U_U611_U625_MY20_Hev_Rx" SG_ 390 Cmbb_B_Enbl 1;
BA_ "U_U611_U625_MY20_Gas_Rx" SG_ 390 Cmbb_B_Enbl 1;
BA_ "U_U611_U625_MY20_Diesel_Rx" SG_ 390 Cmbb_B_Enbl 1;
BA_ "U_C519_MY18_5_Gas_Rx" SG_ 390 Cmbb_B_Enbl 1;
BA_ "U_C519_MY18_5_Diesel_Rx" SG_ 390 Cmbb_B_Enbl 1;
BA_ "U_B479_MY17_Diesel_Rx" SG_ 390 Cmbb_B_Enbl 1;
BA_ "U_B479_MY17_Gas_Rx" SG_ 390 Cmbb_B_Enbl 1;
BA_ "U_CX482_CX483_MY20_Hev_Tx" SG_ 390 CmbbOvrrd_B_RqDrv 1;
BA_ "U_CX482_CX483_MY20_Gas_Tx" SG_ 390 CmbbOvrrd_B_RqDrv 1;
BA_ "U_CX482_CX483_MY20_Diesel_Tx" SG_ 390 CmbbOvrrd_B_RqDrv 1;
BA_ "U_U611_U625_MY20_Hev_Tx" SG_ 390 CmbbOvrrd_B_RqDrv 1;
BA_ "U_U611_U625_MY20_Gas_Tx" SG_ 390 CmbbOvrrd_B_RqDrv 1;
BA_ "U_U611_U625_MY20_Diesel_Tx" SG_ 390 CmbbOvrrd_B_RqDrv 1;
BA_ "U_C519_MY18_5_Gas_Tx" SG_ 390 CmbbOvrrd_B_RqDrv 1;
BA_ "U_C519_MY18_5_Diesel_Tx" SG_ 390 CmbbOvrrd_B_RqDrv 1;
BA_ "U_B479_MY17_Diesel_Tx" SG_ 390 CmbbOvrrd_B_RqDrv 1;
BA_ "U_B479_MY17_Gas_Tx" SG_ 390 CmbbOvrrd_B_RqDrv 1;
BA_ "U_CX482_CX483_MY20_Hev_Rx" SG_ 390 CmbbOvrrd_B_RqDrv 1;
BA_ "U_CX482_CX483_MY20_Gas_Rx" SG_ 390 CmbbOvrrd_B_RqDrv 1;
BA_ "U_CX482_CX483_MY20_Diesel_Rx" SG_ 390 CmbbOvrrd_B_RqDrv 1;
BA_ "U_U611_U625_MY20_Hev_Rx" SG_ 390 CmbbOvrrd_B_RqDrv 1;
BA_ "U_U611_U625_MY20_Gas_Rx" SG_ 390 CmbbOvrrd_B_RqDrv 1;
BA_ "U_U611_U625_MY20_Diesel_Rx" SG_ 390 CmbbOvrrd_B_RqDrv 1;
BA_ "U_C519_MY18_5_Gas_Rx" SG_ 390 CmbbOvrrd_B_RqDrv 1;
BA_ "U_C519_MY18_5_Diesel_Rx" SG_ 390 CmbbOvrrd_B_RqDrv 1;
BA_ "U_B479_MY17_Diesel_Rx" SG_ 390 CmbbOvrrd_B_RqDrv 1;
BA_ "U_B479_MY17_Gas_Rx" SG_ 390 CmbbOvrrd_B_RqDrv 1;
BA_ "U_CX482_CX483_MY20_Hev_Tx" SG_ 390 CmbbDeny_B_Actl 1;
BA_ "U_CX482_CX483_MY20_Gas_Tx" SG_ 390 CmbbDeny_B_Actl 1;
BA_ "U_CX482_CX483_MY20_Diesel_Tx" SG_ 390 CmbbDeny_B_Actl 1;
BA_ "U_U611_U625_MY20_Hev_Tx" SG_ 390 CmbbDeny_B_Actl 1;
BA_ "U_U611_U625_MY20_Gas_Tx" SG_ 390 CmbbDeny_B_Actl 1;
BA_ "U_U611_U625_MY20_Diesel_Tx" SG_ 390 CmbbDeny_B_Actl 1;
BA_ "U_C519_MY18_5_Gas_Tx" SG_ 390 CmbbDeny_B_Actl 1;
BA_ "U_C519_MY18_5_Diesel_Tx" SG_ 390 CmbbDeny_B_Actl 1;
BA_ "U_B479_MY17_Diesel_Tx" SG_ 390 CmbbDeny_B_Actl 1;
BA_ "U_B479_MY17_Gas_Tx" SG_ 390 CmbbDeny_B_Actl 1;
BA_ "U_CX482_CX483_MY20_Hev_Rx" SG_ 390 CmbbDeny_B_Actl 1;
BA_ "U_CX482_CX483_MY20_Gas_Rx" SG_ 390 CmbbDeny_B_Actl 1;
BA_ "U_CX482_CX483_MY20_Diesel_Rx" SG_ 390 CmbbDeny_B_Actl 1;
BA_ "U_U611_U625_MY20_Hev_Rx" SG_ 390 CmbbDeny_B_Actl 1;
BA_ "U_U611_U625_MY20_Gas_Rx" SG_ 390 CmbbDeny_B_Actl 1;
BA_ "U_U611_U625_MY20_Diesel_Rx" SG_ 390 CmbbDeny_B_Actl 1;
BA_ "U_C519_MY18_5_Gas_Rx" SG_ 390 CmbbDeny_B_Actl 1;
BA_ "U_C519_MY18_5_Diesel_Rx" SG_ 390 CmbbDeny_B_Actl 1;
BA_ "U_B479_MY17_Diesel_Rx" SG_ 390 CmbbDeny_B_Actl 1;
BA_ "U_B479_MY17_Gas_Rx" SG_ 390 CmbbDeny_B_Actl 1;
BA_ "U_CX482_CX483_MY20_Hev_Tx" SG_ 390 CmbbEngTqMn_B_Rq 1;
BA_ "U_CX482_CX483_MY20_Gas_Tx" SG_ 390 CmbbEngTqMn_B_Rq 1;
BA_ "U_CX482_CX483_MY20_Diesel_Tx" SG_ 390 CmbbEngTqMn_B_Rq 1;
BA_ "U_U611_U625_MY20_Hev_Tx" SG_ 390 CmbbEngTqMn_B_Rq 1;
BA_ "U_U611_U625_MY20_Gas_Tx" SG_ 390 CmbbEngTqMn_B_Rq 1;
BA_ "U_U611_U625_MY20_Diesel_Tx" SG_ 390 CmbbEngTqMn_B_Rq 1;
BA_ "U_C519_MY18_5_Gas_Tx" SG_ 390 CmbbEngTqMn_B_Rq 1;
BA_ "U_C519_MY18_5_Diesel_Tx" SG_ 390 CmbbEngTqMn_B_Rq 1;
BA_ "U_B479_MY17_Diesel_Tx" SG_ 390 CmbbEngTqMn_B_Rq 1;
BA_ "U_B479_MY17_Gas_Tx" SG_ 390 CmbbEngTqMn_B_Rq 1;
BA_ "U_CX482_CX483_MY20_Hev_Tx" SG_ 390 AccPrpl_A_Rq 1;
BA_ "U_CX482_CX483_MY20_Gas_Tx" SG_ 390 AccPrpl_A_Rq 1;
BA_ "U_CX482_CX483_MY20_Diesel_Tx" SG_ 390 AccPrpl_A_Rq 1;
BA_ "U_U611_U625_MY20_Hev_Tx" SG_ 390 AccPrpl_A_Rq 1;
BA_ "U_U611_U625_MY20_Gas_Tx" SG_ 390 AccPrpl_A_Rq 1;
BA_ "U_U611_U625_MY20_Diesel_Tx" SG_ 390 AccPrpl_A_Rq 1;
BA_ "U_C519_MY18_5_Gas_Tx" SG_ 390 AccPrpl_A_Rq 1;
BA_ "U_C519_MY18_5_Diesel_Tx" SG_ 390 AccPrpl_A_Rq 1;
BA_ "U_B479_MY17_Diesel_Tx" SG_ 390 AccPrpl_A_Rq 1;
BA_ "U_B479_MY17_Gas_Tx" SG_ 390 AccPrpl_A_Rq 1;
BA_ "U_CX482_CX483_MY20_Hev_Tx" SG_ 390 AccDeny_B_Rq 1;
BA_ "U_CX482_CX483_MY20_Gas_Tx" SG_ 390 AccDeny_B_Rq 1;
BA_ "U_CX482_CX483_MY20_Diesel_Tx" SG_ 390 AccDeny_B_Rq 1;
BA_ "U_U611_U625_MY20_Hev_Tx" SG_ 390 AccDeny_B_Rq 1;
BA_ "U_U611_U625_MY20_Gas_Tx" SG_ 390 AccDeny_B_Rq 1;
BA_ "U_U611_U625_MY20_Diesel_Tx" SG_ 390 AccDeny_B_Rq 1;
BA_ "U_C519_MY18_5_Gas_Tx" SG_ 390 AccDeny_B_Rq 1;
BA_ "U_C519_MY18_5_Diesel_Tx" SG_ 390 AccDeny_B_Rq 1;
BA_ "U_B479_MY17_Diesel_Tx" SG_ 390 AccDeny_B_Rq 1;
BA_ "U_B479_MY17_Gas_Tx" SG_ 390 AccDeny_B_Rq 1;
BA_ "U_CX482_CX483_MY20_Hev_Tx" SG_ 390 AccResumEnbl_B_Rq 1;
BA_ "U_CX482_CX483_MY20_Gas_Tx" SG_ 390 AccResumEnbl_B_Rq 1;
BA_ "U_CX482_CX483_MY20_Diesel_Tx" SG_ 390 AccResumEnbl_B_Rq 1;
BA_ "U_U611_U625_MY20_Hev_Tx" SG_ 390 AccResumEnbl_B_Rq 1;
BA_ "U_U611_U625_MY20_Gas_Tx" SG_ 390 AccResumEnbl_B_Rq 1;
BA_ "U_U611_U625_MY20_Diesel_Tx" SG_ 390 AccResumEnbl_B_Rq 1;
BA_ "U_C519_MY18_5_Gas_Tx" SG_ 390 AccResumEnbl_B_Rq 1;
BA_ "U_C519_MY18_5_Diesel_Tx" SG_ 390 AccResumEnbl_B_Rq 1;
BA_ "U_B479_MY17_Diesel_Tx" SG_ 390 AccResumEnbl_B_Rq 1;
BA_ "U_B479_MY17_Gas_Tx" SG_ 390 AccResumEnbl_B_Rq 1;
BA_ "U_B479_MY17_Gas_Rx" SG_ 390 AccResumEnbl_B_Rq 1;
BA_ "WakeupSignal" SG_ 390 AccResumEnbl_B_Rq 1;
BA_ "U_CX482_CX483_MY20_Hev_Tx" SG_ 390 AccCancl_B_Rq 1;
BA_ "U_CX482_CX483_MY20_Gas_Tx" SG_ 390 AccCancl_B_Rq 1;
BA_ "U_CX482_CX483_MY20_Diesel_Tx" SG_ 390 AccCancl_B_Rq 1;
BA_ "U_U611_U625_MY20_Hev_Tx" SG_ 390 AccCancl_B_Rq 1;
BA_ "U_U611_U625_MY20_Gas_Tx" SG_ 390 AccCancl_B_Rq 1;
BA_ "U_U611_U625_MY20_Diesel_Tx" SG_ 390 AccCancl_B_Rq 1;
BA_ "U_C519_MY18_5_Gas_Tx" SG_ 390 AccCancl_B_Rq 1;
BA_ "U_C519_MY18_5_Diesel_Tx" SG_ 390 AccCancl_B_Rq 1;
BA_ "U_B479_MY17_Diesel_Tx" SG_ 390 AccCancl_B_Rq 1;
BA_ "U_B479_MY17_Gas_Tx" SG_ 390 AccCancl_B_Rq 1;
BA_ "U_U611_U625_MY20_Hev_Rx" SG_ 390 AccCancl_B_Rq 1;
BA_ "U_U611_U625_MY20_Gas_Rx" SG_ 390 AccCancl_B_Rq 1;
BA_ "U_U611_U625_MY20_Diesel_Rx" SG_ 390 AccCancl_B_Rq 1;
BA_ "U_B479_MY17_Diesel_Rx" SG_ 390 AccCancl_B_Rq 1;
BA_ "U_B479_MY17_Gas_Rx" SG_ 390 AccCancl_B_Rq 1;
BA_ "U_CX482_CX483_MY20_Hev_Tx" SG_ 390 AccBrkPrchg_B_Rq 1;
BA_ "U_CX482_CX483_MY20_Gas_Tx" SG_ 390 AccBrkPrchg_B_Rq 1;
BA_ "U_CX482_CX483_MY20_Diesel_Tx" SG_ 390 AccBrkPrchg_B_Rq 1;
BA_ "U_U611_U625_MY20_Hev_Tx" SG_ 390 AccBrkPrchg_B_Rq 1;
BA_ "U_U611_U625_MY20_Gas_Tx" SG_ 390 AccBrkPrchg_B_Rq 1;
BA_ "U_U611_U625_MY20_Diesel_Tx" SG_ 390 AccBrkPrchg_B_Rq 1;
BA_ "U_C519_MY18_5_Gas_Tx" SG_ 390 AccBrkPrchg_B_Rq 1;
BA_ "U_C519_MY18_5_Diesel_Tx" SG_ 390 AccBrkPrchg_B_Rq 1;
BA_ "U_B479_MY17_Diesel_Tx" SG_ 390 AccBrkPrchg_B_Rq 1;
BA_ "U_B479_MY17_Gas_Tx" SG_ 390 AccBrkPrchg_B_Rq 1;
BA_ "U_CX482_CX483_MY20_Hev_Rx" SG_ 390 AccBrkPrchg_B_Rq 1;
BA_ "U_CX482_CX483_MY20_Gas_Rx" SG_ 390 AccBrkPrchg_B_Rq 1;
BA_ "U_CX482_CX483_MY20_Diesel_Rx" SG_ 390 AccBrkPrchg_B_Rq 1;
BA_ "U_U611_U625_MY20_Hev_Rx" SG_ 390 AccBrkPrchg_B_Rq 1;
BA_ "U_U611_U625_MY20_Gas_Rx" SG_ 390 AccBrkPrchg_B_Rq 1;
BA_ "U_U611_U625_MY20_Diesel_Rx" SG_ 390 AccBrkPrchg_B_Rq 1;
BA_ "U_C519_MY18_5_Gas_Rx" SG_ 390 AccBrkPrchg_B_Rq 1;
BA_ "U_C519_MY18_5_Diesel_Rx" SG_ 390 AccBrkPrchg_B_Rq 1;
BA_ "U_B479_MY17_Diesel_Rx" SG_ 390 AccBrkPrchg_B_Rq 1;
BA_ "U_B479_MY17_Gas_Rx" SG_ 390 AccBrkPrchg_B_Rq 1;
BA_ "U_CX482_CX483_MY20_Hev_Tx" SG_ 390 AccBrkDecel_B_Rq 1;
BA_ "U_CX482_CX483_MY20_Gas_Tx" SG_ 390 AccBrkDecel_B_Rq 1;
BA_ "U_CX482_CX483_MY20_Diesel_Tx" SG_ 390 AccBrkDecel_B_Rq 1;
BA_ "U_U611_U625_MY20_Hev_Tx" SG_ 390 AccBrkDecel_B_Rq 1;
BA_ "U_U611_U625_MY20_Gas_Tx" SG_ 390 AccBrkDecel_B_Rq 1;
BA_ "U_U611_U625_MY20_Diesel_Tx" SG_ 390 AccBrkDecel_B_Rq 1;
BA_ "U_C519_MY18_5_Gas_Tx" SG_ 390 AccBrkDecel_B_Rq 1;
BA_ "U_C519_MY18_5_Diesel_Tx" SG_ 390 AccBrkDecel_B_Rq 1;
BA_ "U_B479_MY17_Diesel_Tx" SG_ 390 AccBrkDecel_B_Rq 1;
BA_ "U_B479_MY17_Gas_Tx" SG_ 390 AccBrkDecel_B_Rq 1;
BA_ "U_CX482_CX483_MY20_Hev_Rx" SG_ 390 AccBrkDecel_B_Rq 1;
BA_ "U_CX482_CX483_MY20_Gas_Rx" SG_ 390 AccBrkDecel_B_Rq 1;
BA_ "U_CX482_CX483_MY20_Diesel_Rx" SG_ 390 AccBrkDecel_B_Rq 1;
BA_ "U_U611_U625_MY20_Hev_Rx" SG_ 390 AccBrkDecel_B_Rq 1;
BA_ "U_U611_U625_MY20_Gas_Rx" SG_ 390 AccBrkDecel_B_Rq 1;
BA_ "U_U611_U625_MY20_Diesel_Rx" SG_ 390 AccBrkDecel_B_Rq 1;
BA_ "U_C519_MY18_5_Gas_Rx" SG_ 390 AccBrkDecel_B_Rq 1;
BA_ "U_C519_MY18_5_Diesel_Rx" SG_ 390 AccBrkDecel_B_Rq 1;
BA_ "U_B479_MY17_Diesel_Rx" SG_ 390 AccBrkDecel_B_Rq 1;
BA_ "U_B479_MY17_Gas_Rx" SG_ 390 AccBrkDecel_B_Rq 1;
BA_ "U_CX482_CX483_MY20_Hev_Tx" SG_ 390 AccStopStat_B_Rq 1;
BA_ "U_CX482_CX483_MY20_Gas_Tx" SG_ 390 AccStopStat_B_Rq 1;
BA_ "U_CX482_CX483_MY20_Diesel_Tx" SG_ 390 AccStopStat_B_Rq 1;
BA_ "U_U611_U625_MY20_Hev_Tx" SG_ 390 AccStopStat_B_Rq 1;
BA_ "U_U611_U625_MY20_Gas_Tx" SG_ 390 AccStopStat_B_Rq 1;
BA_ "U_U611_U625_MY20_Diesel_Tx" SG_ 390 AccStopStat_B_Rq 1;
BA_ "U_C519_MY18_5_Gas_Tx" SG_ 390 AccStopStat_B_Rq 1;
BA_ "U_C519_MY18_5_Diesel_Tx" SG_ 390 AccStopStat_B_Rq 1;
BA_ "U_B479_MY17_Diesel_Tx" SG_ 390 AccStopStat_B_Rq 1;
BA_ "U_B479_MY17_Gas_Tx" SG_ 390 AccStopStat_B_Rq 1;
BA_ "U_CX482_CX483_MY20_Hev_Rx" SG_ 390 AccStopStat_B_Rq 1;
BA_ "U_CX482_CX483_MY20_Gas_Rx" SG_ 390 AccStopStat_B_Rq 1;
BA_ "U_CX482_CX483_MY20_Diesel_Rx" SG_ 390 AccStopStat_B_Rq 1;
BA_ "U_U611_U625_MY20_Hev_Rx" SG_ 390 AccStopStat_B_Rq 1;
BA_ "U_U611_U625_MY20_Gas_Rx" SG_ 390 AccStopStat_B_Rq 1;
BA_ "U_U611_U625_MY20_Diesel_Rx" SG_ 390 AccStopStat_B_Rq 1;
BA_ "U_C519_MY18_5_Gas_Rx" SG_ 390 AccStopStat_B_Rq 1;
BA_ "U_C519_MY18_5_Diesel_Rx" SG_ 390 AccStopStat_B_Rq 1;
BA_ "U_B479_MY17_Diesel_Rx" SG_ 390 AccStopStat_B_Rq 1;
BA_ "U_B479_MY17_Gas_Rx" SG_ 390 AccStopStat_B_Rq 1;
BA_ "GenSigSendType" SG_ 1947 TesterPhysicalResFDSM 3;
BA_ "GenSigSendType" SG_ 1939 TesterPhysicalReqFDSM 3;
BA_ "U_CX482_CX483_MY20_Hev_Rx" SG_ 1071 CluPdl_PcRate_Actl 1;
BA_ "U_CX482_CX483_MY20_Gas_Rx" SG_ 1071 CluPdl_PcRate_Actl 1;
BA_ "U_CX482_CX483_MY20_Diesel_Rx" SG_ 1071 CluPdl_PcRate_Actl 1;
BA_ "U_B500_MY18_Diesel_Rx" SG_ 1071 CluPdl_PcRate_Actl 1;
BA_ "U_B500_MY18_Gas_Rx" SG_ 1071 CluPdl_PcRate_Actl 1;
BA_ "U_C490_MY18_Rx" SG_ 1071 CluPdl_PcRate_Actl 1;
BA_ "U_B562_MY18_Gas_Rx" SG_ 1071 CluPdl_PcRate_Actl 1;
BA_ "U_C519_MY18_5_Gas_Rx" SG_ 1071 CluPdl_PcRate_Actl 1;
BA_ "U_C519_MY18_5_Diesel_Rx" SG_ 1071 CluPdl_PcRate_Actl 1;
BA_ "U_B515_MCA_MY17_Gas_Rx" SG_ 1071 CluPdl_PcRate_Actl 1;
BA_ "U_B515_MCA_MY17_Diesel_Rx" SG_ 1071 CluPdl_PcRate_Actl 1;
BA_ "U_B479_MY17_Diesel_Rx" SG_ 1071 CluPdl_PcRate_Actl 1;
BA_ "U_B479_MY17_Gas_Rx" SG_ 1071 CluPdl_PcRate_Actl 1;
BA_ "ContentDependant" SG_ 1071 CluPdl_PcRate_Actl 1;
BA_ "CrossOver_InfoCAN" SG_ 1071 CluPdl_PcRate_Actl 1;
BA_ "U_CX482_CX483_MY20_Hev_Rx" SG_ 1071 CluPdlPosPcMeas_D_Qf 1;
BA_ "U_CX482_CX483_MY20_Gas_Rx" SG_ 1071 CluPdlPosPcMeas_D_Qf 1;
BA_ "U_CX482_CX483_MY20_Diesel_Rx" SG_ 1071 CluPdlPosPcMeas_D_Qf 1;
BA_ "U_B500_MY18_Diesel_Rx" SG_ 1071 CluPdlPosPcMeas_D_Qf 1;
BA_ "U_B500_MY18_Gas_Rx" SG_ 1071 CluPdlPosPcMeas_D_Qf 1;
BA_ "U_C490_MY18_Rx" SG_ 1071 CluPdlPosPcMeas_D_Qf 1;
BA_ "U_B562_MY18_Gas_Rx" SG_ 1071 CluPdlPosPcMeas_D_Qf 1;
BA_ "U_C519_MY18_5_Gas_Rx" SG_ 1071 CluPdlPosPcMeas_D_Qf 1;
BA_ "U_C519_MY18_5_Diesel_Rx" SG_ 1071 CluPdlPosPcMeas_D_Qf 1;
BA_ "U_B515_MCA_MY17_Gas_Rx" SG_ 1071 CluPdlPosPcMeas_D_Qf 1;
BA_ "U_B515_MCA_MY17_Diesel_Rx" SG_ 1071 CluPdlPosPcMeas_D_Qf 1;
BA_ "U_B479_MY17_Diesel_Rx" SG_ 1071 CluPdlPosPcMeas_D_Qf 1;
BA_ "U_B479_MY17_Gas_Rx" SG_ 1071 CluPdlPosPcMeas_D_Qf 1;
BA_ "ContentDependant" SG_ 1071 CluPdlPosPcMeas_D_Qf 1;
BA_ "GenSigStartValue" SG_ 1071 CluPdlPosPcMeas_D_Qf 1;
BA_ "CrossOver_InfoCAN" SG_ 1071 CluPdlPosPcMeas_D_Qf 1;
BA_ "U_U611_U625_MY20_Hev_Rx" SG_ 1071 CluPdlPos_Pc_Meas 1;
BA_ "U_U611_U625_MY20_Gas_Rx" SG_ 1071 CluPdlPos_Pc_Meas 1;
BA_ "U_U611_U625_MY20_Diesel_Rx" SG_ 1071 CluPdlPos_Pc_Meas 1;
BA_ "U_CX482_CX483_MY20_Hev_Rx" SG_ 1071 CluPdlPos_Pc_Meas 1;
BA_ "U_CX482_CX483_MY20_Gas_Rx" SG_ 1071 CluPdlPos_Pc_Meas 1;
BA_ "U_CX482_CX483_MY20_Diesel_Rx" SG_ 1071 CluPdlPos_Pc_Meas 1;
BA_ "U_B500_MY18_Diesel_Rx" SG_ 1071 CluPdlPos_Pc_Meas 1;
BA_ "U_B500_MY18_Gas_Rx" SG_ 1071 CluPdlPos_Pc_Meas 1;
BA_ "U_C490_MY18_Rx" SG_ 1071 CluPdlPos_Pc_Meas 1;
BA_ "U_B562_MY18_Gas_Rx" SG_ 1071 CluPdlPos_Pc_Meas 1;
BA_ "U_C519_MY18_5_Gas_Rx" SG_ 1071 CluPdlPos_Pc_Meas 1;
BA_ "U_C519_MY18_5_Diesel_Rx" SG_ 1071 CluPdlPos_Pc_Meas 1;
BA_ "U_B515_MCA_MY17_Gas_Rx" SG_ 1071 CluPdlPos_Pc_Meas 1;
BA_ "U_B515_MCA_MY17_Diesel_Rx" SG_ 1071 CluPdlPos_Pc_Meas 1;
BA_ "U_B479_MY17_Diesel_Rx" SG_ 1071 CluPdlPos_Pc_Meas 1;
BA_ "U_B479_MY17_Gas_Rx" SG_ 1071 CluPdlPos_Pc_Meas 1;
BA_ "ContentDependant" SG_ 1071 CluPdlPos_Pc_Meas 1;
BA_ "CrossOver_InfoCAN" SG_ 1071 CluPdlPos_Pc_Meas 1;
BA_ "U_B479_MY17_Gas_Rx" SG_ 1071 EngMnfld3_P_Actl 1;
BA_ "GenSigStartValue" SG_ 1071 EngMnfld3_P_Actl 254;
BA_ "U_CX482_CX483_MY20_Hev_Rx" SG_ 1071 EngAoutIdl_N_Ntrl 1;
BA_ "U_CX482_CX483_MY20_Gas_Rx" SG_ 1071 EngAoutIdl_N_Ntrl 1;
BA_ "U_CX482_CX483_MY20_Diesel_Rx" SG_ 1071 EngAoutIdl_N_Ntrl 1;
BA_ "U_B500_MY18_Diesel_Rx" SG_ 1071 EngAoutIdl_N_Ntrl 1;
BA_ "U_B500_MY18_Gas_Rx" SG_ 1071 EngAoutIdl_N_Ntrl 1;
BA_ "U_C490_MY18_Rx" SG_ 1071 EngAoutIdl_N_Ntrl 1;
BA_ "U_B562_MY18_Gas_Rx" SG_ 1071 EngAoutIdl_N_Ntrl 1;
BA_ "U_C519_MY18_5_Gas_Rx" SG_ 1071 EngAoutIdl_N_Ntrl 1;
BA_ "U_C519_MY18_5_Diesel_Rx" SG_ 1071 EngAoutIdl_N_Ntrl 1;
BA_ "U_B515_MCA_MY17_Gas_Rx" SG_ 1071 EngAoutIdl_N_Ntrl 1;
BA_ "U_B515_MCA_MY17_Diesel_Rx" SG_ 1071 EngAoutIdl_N_Ntrl 1;
BA_ "U_B479_MY17_Diesel_Rx" SG_ 1071 EngAoutIdl_N_Ntrl 1;
BA_ "U_B479_MY17_Gas_Rx" SG_ 1071 EngAoutIdl_N_Ntrl 1;
BA_ "ContentDependant" SG_ 1071 EngAoutIdl_N_Ntrl 1;
BA_ "CrossOver_InfoCAN" SG_ 1071 EngAoutIdl_N_Ntrl 1;
BA_ "GenSigSendType" SG_ 1072 TrlrAidCancl_B_Rq 3;
BA_ "GenSigSendType" SG_ 1072 HdcOn_B_Rq 3;
BA_ "U_CX482_CX483_MY20_Hev_Rx" SG_ 1072 HsaMde_D_Rq 1;
BA_ "U_CX482_CX483_MY20_Gas_Rx" SG_ 1072 HsaMde_D_Rq 1;
BA_ "U_CX482_CX483_MY20_Diesel_Rx" SG_ 1072 HsaMde_D_Rq 1;
BA_ "U_U611_U625_MY20_Hev_Rx" SG_ 1072 HsaMde_D_Rq 1;
BA_ "U_U611_U625_MY20_Gas_Rx" SG_ 1072 HsaMde_D_Rq 1;
BA_ "U_U611_U625_MY20_Diesel_Rx" SG_ 1072 HsaMde_D_Rq 1;
BA_ "U_B500_MY18_Diesel_Rx" SG_ 1072 HsaMde_D_Rq 1;
BA_ "U_B500_MY18_Gas_Rx" SG_ 1072 HsaMde_D_Rq 1;
BA_ "U_B562_MY18_Gas_Rx" SG_ 1072 HsaMde_D_Rq 1;
BA_ "U_C519_MY18_5_Gas_Rx" SG_ 1072 HsaMde_D_Rq 1;
BA_ "U_C519_MY18_5_Diesel_Rx" SG_ 1072 HsaMde_D_Rq 1;
BA_ "U_B515_MCA_MY17_Gas_Rx" SG_ 1072 HsaMde_D_Rq 1;
BA_ "U_B515_MCA_MY17_Diesel_Rx" SG_ 1072 HsaMde_D_Rq 1;
BA_ "U_B479_MY17_Diesel_Rx" SG_ 1072 HsaMde_D_Rq 1;
BA_ "U_B479_MY17_Gas_Rx" SG_ 1072 HsaMde_D_Rq 1;
BA_ "GenSigSendType" SG_ 1072 HsaMde_D_Rq 3;
BA_ "GenSigStartValue" SG_ 1072 HsaMde_D_Rq 1;
BA_ "CrossOver_InfoCAN" SG_ 1072 HsaMde_D_Rq 1;
BA_ "U_CX482_CX483_MY20_Hev_Rx" SG_ 1072 HsaMde_D_Rq_UB 1;
BA_ "U_CX482_CX483_MY20_Gas_Rx" SG_ 1072 HsaMde_D_Rq_UB 1;
BA_ "U_CX482_CX483_MY20_Diesel_Rx" SG_ 1072 HsaMde_D_Rq_UB 1;
BA_ "U_B500_MY18_Diesel_Rx" SG_ 1072 HsaMde_D_Rq_UB 1;
BA_ "U_B500_MY18_Gas_Rx" SG_ 1072 HsaMde_D_Rq_UB 1;
BA_ "U_B562_MY18_Gas_Rx" SG_ 1072 HsaMde_D_Rq_UB 1;
BA_ "U_C519_MY18_5_Gas_Rx" SG_ 1072 HsaMde_D_Rq_UB 1;
BA_ "U_C519_MY18_5_Diesel_Rx" SG_ 1072 HsaMde_D_Rq_UB 1;
BA_ "U_B515_MCA_MY17_Gas_Rx" SG_ 1072 HsaMde_D_Rq_UB 1;
BA_ "U_B515_MCA_MY17_Diesel_Rx" SG_ 1072 HsaMde_D_Rq_UB 1;
BA_ "U_B479_MY17_Diesel_Rx" SG_ 1072 HsaMde_D_Rq_UB 1;
BA_ "U_B479_MY17_Gas_Rx" SG_ 1072 HsaMde_D_Rq_UB 1;
BA_ "GenSigSendType" SG_ 1072 LscmbbStat_B_Actl 3;
BA_ "CrossOver_InfoCAN" SG_ 1072 LscmbbStat_B_Actl 1;
BA_ "U_U611_U625_MY20_Phev_Rx" SG_ 1072 Outside_Air_Temp_Stat_UB 1;
BA_ "U_CX482_CX483_MY20_Hev_Rx" SG_ 1072 Outside_Air_Temp_Stat_UB 1;
BA_ "U_CX482_CX483_MY20_Gas_Rx" SG_ 1072 Outside_Air_Temp_Stat_UB 1;
BA_ "U_CX482_CX483_MY20_Diesel_Rx" SG_ 1072 Outside_Air_Temp_Stat_UB 1;
BA_ "U_U611_U625_MY20_Hev_Rx" SG_ 1072 Outside_Air_Temp_Stat_UB 1;
BA_ "U_U611_U625_MY20_Gas_Rx" SG_ 1072 Outside_Air_Temp_Stat_UB 1;
BA_ "U_U611_U625_MY20_Diesel_Rx" SG_ 1072 Outside_Air_Temp_Stat_UB 1;
BA_ "U_C519_MY18_5_Gas_Rx" SG_ 1072 Outside_Air_Temp_Stat_UB 1;
BA_ "U_C519_MY18_5_Diesel_Rx" SG_ 1072 Outside_Air_Temp_Stat_UB 1;
BA_ "U_B479_MY17_Diesel_Rx" SG_ 1072 Outside_Air_Temp_Stat_UB 1;
BA_ "U_B479_MY17_Gas_Rx" SG_ 1072 Outside_Air_Temp_Stat_UB 1;
BA_ "CrossOver_InfoCAN" SG_ 1072 Outside_Air_Temp_Stat_UB 1;
BA_ "U_U611_U625_MY20_Phev_Rx" SG_ 1072 Outside_Air_Temp_Stat 1;
BA_ "U_CX482_CX483_MY20_Hev_Rx" SG_ 1072 Outside_Air_Temp_Stat 1;
BA_ "U_CX482_CX483_MY20_Gas_Rx" SG_ 1072 Outside_Air_Temp_Stat 1;
BA_ "U_CX482_CX483_MY20_Diesel_Rx" SG_ 1072 Outside_Air_Temp_Stat 1;
BA_ "U_U611_U625_MY20_Hev_Rx" SG_ 1072 Outside_Air_Temp_Stat 1;
BA_ "U_U611_U625_MY20_Gas_Rx" SG_ 1072 Outside_Air_Temp_Stat 1;
BA_ "U_U611_U625_MY20_Diesel_Rx" SG_ 1072 Outside_Air_Temp_Stat 1;
BA_ "U_B500_MY18_Diesel_Rx" SG_ 1072 Outside_Air_Temp_Stat 1;
BA_ "U_B500_MY18_Gas_Rx" SG_ 1072 Outside_Air_Temp_Stat 1;
BA_ "U_C519_MY18_5_Gas_Rx" SG_ 1072 Outside_Air_Temp_Stat 1;
BA_ "U_C519_MY18_5_Diesel_Rx" SG_ 1072 Outside_Air_Temp_Stat 1;
BA_ "U_B479_MY17_Diesel_Rx" SG_ 1072 Outside_Air_Temp_Stat 1;
BA_ "U_B479_MY17_Gas_Rx" SG_ 1072 Outside_Air_Temp_Stat 1;
BA_ "GenSigSendType" SG_ 1072 Outside_Air_Temp_Stat 3;
BA_ "GenSigStartValue" SG_ 1072 Outside_Air_Temp_Stat 254;
BA_ "CrossOver_InfoCAN" SG_ 1072 Outside_Air_Temp_Stat 1;
BA_ "U_U611_U625_MY20_Phev_Rx" SG_ 1072 BulbChkActv_B_Stat_UB 1;
BA_ "U_U611_U625_MY20_Hev_Rx" SG_ 1072 BulbChkActv_B_Stat_UB 1;
BA_ "U_U611_U625_MY20_Gas_Rx" SG_ 1072 BulbChkActv_B_Stat_UB 1;
BA_ "U_U611_U625_MY20_Diesel_Rx" SG_ 1072 BulbChkActv_B_Stat_UB 1;
BA_ "U_U611_U625_MY20_Phev_Rx" SG_ 1072 BulbChkActv_B_Stat 1;
BA_ "U_U611_U625_MY20_Hev_Rx" SG_ 1072 BulbChkActv_B_Stat 1;
BA_ "U_U611_U625_MY20_Gas_Rx" SG_ 1072 BulbChkActv_B_Stat 1;
BA_ "U_U611_U625_MY20_Diesel_Rx" SG_ 1072 BulbChkActv_B_Stat 1;
BA_ "GenSigSendType" SG_ 1072 BulbChkActv_B_Stat 3;
BA_ "CrossOver_InfoCAN" SG_ 1072 BulbChkActv_B_Stat 1;
BA_ "U_CX482_CX483_MY20_Hev_Rx" SG_ 1072 Fda_B_Stat_UB 1;
BA_ "U_CX482_CX483_MY20_Gas_Rx" SG_ 1072 Fda_B_Stat_UB 1;
BA_ "U_CX482_CX483_MY20_Diesel_Rx" SG_ 1072 Fda_B_Stat_UB 1;
BA_ "U_U611_U625_MY20_Hev_Rx" SG_ 1072 Fda_B_Stat_UB 1;
BA_ "U_U611_U625_MY20_Gas_Rx" SG_ 1072 Fda_B_Stat_UB 1;
BA_ "U_U611_U625_MY20_Diesel_Rx" SG_ 1072 Fda_B_Stat_UB 1;
BA_ "U_C519_MY18_5_Gas_Rx" SG_ 1072 Fda_B_Stat_UB 1;
BA_ "U_C519_MY18_5_Diesel_Rx" SG_ 1072 Fda_B_Stat_UB 1;
BA_ "U_B479_MY17_Diesel_Rx" SG_ 1072 Fda_B_Stat_UB 1;
BA_ "U_B479_MY17_Gas_Rx" SG_ 1072 Fda_B_Stat_UB 1;
BA_ "U_CX482_CX483_MY20_Hev_Rx" SG_ 1072 AccEnbl_B_RqDrv_UB 1;
BA_ "U_CX482_CX483_MY20_Gas_Rx" SG_ 1072 AccEnbl_B_RqDrv_UB 1;
BA_ "U_CX482_CX483_MY20_Diesel_Rx" SG_ 1072 AccEnbl_B_RqDrv_UB 1;
BA_ "U_U611_U625_MY20_Hev_Rx" SG_ 1072 AccEnbl_B_RqDrv_UB 1;
BA_ "U_U611_U625_MY20_Gas_Rx" SG_ 1072 AccEnbl_B_RqDrv_UB 1;
BA_ "U_U611_U625_MY20_Diesel_Rx" SG_ 1072 AccEnbl_B_RqDrv_UB 1;
BA_ "U_C519_MY18_5_Gas_Rx" SG_ 1072 AccEnbl_B_RqDrv_UB 1;
BA_ "U_C519_MY18_5_Diesel_Rx" SG_ 1072 AccEnbl_B_RqDrv_UB 1;
BA_ "U_B479_MY17_Diesel_Rx" SG_ 1072 AccEnbl_B_RqDrv_UB 1;
BA_ "U_B479_MY17_Gas_Rx" SG_ 1072 AccEnbl_B_RqDrv_UB 1;
BA_ "U_CX482_CX483_MY20_Hev_Rx" SG_ 1072 AccDeny_B_RqIpc_UB 1;
BA_ "U_CX482_CX483_MY20_Gas_Rx" SG_ 1072 AccDeny_B_RqIpc_UB 1;
BA_ "U_CX482_CX483_MY20_Diesel_Rx" SG_ 1072 AccDeny_B_RqIpc_UB 1;
BA_ "U_U611_U625_MY20_Hev_Rx" SG_ 1072 AccDeny_B_RqIpc_UB 1;
BA_ "U_U611_U625_MY20_Gas_Rx" SG_ 1072 AccDeny_B_RqIpc_UB 1;
BA_ "U_U611_U625_MY20_Diesel_Rx" SG_ 1072 AccDeny_B_RqIpc_UB 1;
BA_ "U_C519_MY18_5_Gas_Rx" SG_ 1072 AccDeny_B_RqIpc_UB 1;
BA_ "U_C519_MY18_5_Diesel_Rx" SG_ 1072 AccDeny_B_RqIpc_UB 1;
BA_ "U_B479_MY17_Diesel_Rx" SG_ 1072 AccDeny_B_RqIpc_UB 1;
BA_ "U_B479_MY17_Gas_Rx" SG_ 1072 AccDeny_B_RqIpc_UB 1;
BA_ "U_U611_U625_MY20_Phev_Rx" SG_ 1072 OdometerMasterValue_UB 1;
BA_ "U_U611_U625_MY20_Hev_Rx" SG_ 1072 OdometerMasterValue_UB 1;
BA_ "U_U611_U625_MY20_Gas_Rx" SG_ 1072 OdometerMasterValue_UB 1;
BA_ "U_U611_U625_MY20_Diesel_Rx" SG_ 1072 OdometerMasterValue_UB 1;
BA_ "U_CX482_CX483_MY20_Hev_Rx" SG_ 1072 OdometerMasterValue_UB 1;
BA_ "U_CX482_CX483_MY20_Gas_Rx" SG_ 1072 OdometerMasterValue_UB 1;
BA_ "U_CX482_CX483_MY20_Diesel_Rx" SG_ 1072 OdometerMasterValue_UB 1;
BA_ "U_B500_MY18_Diesel_Rx" SG_ 1072 OdometerMasterValue_UB 1;
BA_ "U_B500_MY18_Gas_Rx" SG_ 1072 OdometerMasterValue_UB 1;
BA_ "U_C519_MY18_5_Gas_Rx" SG_ 1072 OdometerMasterValue_UB 1;
BA_ "U_C519_MY18_5_Diesel_Rx" SG_ 1072 OdometerMasterValue_UB 1;
BA_ "U_B515_MCA_MY17_Gas_Rx" SG_ 1072 OdometerMasterValue_UB 1;
BA_ "U_B515_MCA_MY17_Diesel_Rx" SG_ 1072 OdometerMasterValue_UB 1;
BA_ "U_B479_MY17_Diesel_Rx" SG_ 1072 OdometerMasterValue_UB 1;
BA_ "U_B479_MY17_Gas_Rx" SG_ 1072 OdometerMasterValue_UB 1;
BA_ "U_U611_U625_MY20_Phev_Rx" SG_ 1072 OdometerMasterValue 1;
BA_ "U_CX482_CX483_MY20_Hev_Rx" SG_ 1072 OdometerMasterValue 1;
BA_ "U_CX482_CX483_MY20_Gas_Rx" SG_ 1072 OdometerMasterValue 1;
BA_ "U_CX482_CX483_MY20_Diesel_Rx" SG_ 1072 OdometerMasterValue 1;
BA_ "U_U611_U625_MY20_Hev_Rx" SG_ 1072 OdometerMasterValue 1;
BA_ "U_U611_U625_MY20_Gas_Rx" SG_ 1072 OdometerMasterValue 1;
BA_ "U_U611_U625_MY20_Diesel_Rx" SG_ 1072 OdometerMasterValue 1;
BA_ "U_B500_MY18_Diesel_Rx" SG_ 1072 OdometerMasterValue 1;
BA_ "U_B500_MY18_Gas_Rx" SG_ 1072 OdometerMasterValue 1;
BA_ "U_C490_MY18_Rx" SG_ 1072 OdometerMasterValue 1;
BA_ "U_B562_MY18_Gas_Rx" SG_ 1072 OdometerMasterValue 1;
BA_ "U_C519_MY18_5_Gas_Rx" SG_ 1072 OdometerMasterValue 1;
BA_ "U_C519_MY18_5_Diesel_Rx" SG_ 1072 OdometerMasterValue 1;
BA_ "U_B515_MCA_MY17_Gas_Rx" SG_ 1072 OdometerMasterValue 1;
BA_ "U_B515_MCA_MY17_Diesel_Rx" SG_ 1072 OdometerMasterValue 1;
BA_ "U_B479_MY17_Diesel_Rx" SG_ 1072 OdometerMasterValue 1;
BA_ "U_B479_MY17_Gas_Rx" SG_ 1072 OdometerMasterValue 1;
BA_ "GenSigSendType" SG_ 1072 OdometerMasterValue 3;
BA_ "CrossOver_InfoCAN" SG_ 1072 OdometerMasterValue 1;
BA_ "U_CX482_CX483_MY20_Hev_Rx" SG_ 1072 Fda_B_Stat 1;
BA_ "U_CX482_CX483_MY20_Gas_Rx" SG_ 1072 Fda_B_Stat 1;
BA_ "U_CX482_CX483_MY20_Diesel_Rx" SG_ 1072 Fda_B_Stat 1;
BA_ "U_U611_U625_MY20_Hev_Rx" SG_ 1072 Fda_B_Stat 1;
BA_ "U_U611_U625_MY20_Gas_Rx" SG_ 1072 Fda_B_Stat 1;
BA_ "U_U611_U625_MY20_Diesel_Rx" SG_ 1072 Fda_B_Stat 1;
BA_ "U_C519_MY18_5_Gas_Rx" SG_ 1072 Fda_B_Stat 1;
BA_ "U_C519_MY18_5_Diesel_Rx" SG_ 1072 Fda_B_Stat 1;
BA_ "U_B479_MY17_Diesel_Rx" SG_ 1072 Fda_B_Stat 1;
BA_ "U_B479_MY17_Gas_Rx" SG_ 1072 Fda_B_Stat 1;
BA_ "GenSigSendType" SG_ 1072 Fda_B_Stat 3;
BA_ "CrossOver_InfoCAN" SG_ 1072 Fda_B_Stat 1;
BA_ "U_CX482_CX483_MY20_Hev_Rx" SG_ 1072 AccDeny_B_RqIpc 1;
BA_ "U_CX482_CX483_MY20_Gas_Rx" SG_ 1072 AccDeny_B_RqIpc 1;
BA_ "U_CX482_CX483_MY20_Diesel_Rx" SG_ 1072 AccDeny_B_RqIpc 1;
BA_ "U_U611_U625_MY20_Hev_Rx" SG_ 1072 AccDeny_B_RqIpc 1;
BA_ "U_U611_U625_MY20_Gas_Rx" SG_ 1072 AccDeny_B_RqIpc 1;
BA_ "U_U611_U625_MY20_Diesel_Rx" SG_ 1072 AccDeny_B_RqIpc 1;
BA_ "U_C519_MY18_5_Gas_Rx" SG_ 1072 AccDeny_B_RqIpc 1;
BA_ "U_C519_MY18_5_Diesel_Rx" SG_ 1072 AccDeny_B_RqIpc 1;
BA_ "U_B479_MY17_Diesel_Rx" SG_ 1072 AccDeny_B_RqIpc 1;
BA_ "U_B479_MY17_Gas_Rx" SG_ 1072 AccDeny_B_RqIpc 1;
BA_ "GenSigSendType" SG_ 1072 AccDeny_B_RqIpc 3;
BA_ "CrossOver_InfoCAN" SG_ 1072 AccDeny_B_RqIpc 1;
BA_ "U_CX482_CX483_MY20_Hev_Rx" SG_ 1072 AccEnbl_B_RqDrv 1;
BA_ "U_CX482_CX483_MY20_Gas_Rx" SG_ 1072 AccEnbl_B_RqDrv 1;
BA_ "U_CX482_CX483_MY20_Diesel_Rx" SG_ 1072 AccEnbl_B_RqDrv 1;
BA_ "U_U611_U625_MY20_Hev_Rx" SG_ 1072 AccEnbl_B_RqDrv 1;
BA_ "U_U611_U625_MY20_Gas_Rx" SG_ 1072 AccEnbl_B_RqDrv 1;
BA_ "U_U611_U625_MY20_Diesel_Rx" SG_ 1072 AccEnbl_B_RqDrv 1;
BA_ "U_C519_MY18_5_Gas_Rx" SG_ 1072 AccEnbl_B_RqDrv 1;
BA_ "U_C519_MY18_5_Diesel_Rx" SG_ 1072 AccEnbl_B_RqDrv 1;
BA_ "U_B479_MY17_Diesel_Rx" SG_ 1072 AccEnbl_B_RqDrv 1;
BA_ "U_B479_MY17_Gas_Rx" SG_ 1072 AccEnbl_B_RqDrv 1;
BA_ "GenSigSendType" SG_ 1072 AccEnbl_B_RqDrv 3;
BA_ "GenSigStartValue" SG_ 1072 AccEnbl_B_RqDrv 1;
BA_ "CrossOver_InfoCAN" SG_ 1072 AccEnbl_B_RqDrv 1;
BA_ "U_B500_MY18_Diesel_Rx" SG_ 1072 DrvSlipCtlMde_D_Rq_UB 1;
BA_ "U_B500_MY18_Gas_Rx" SG_ 1072 DrvSlipCtlMde_D_Rq_UB 1;
BA_ "U_B562_MY18_Gas_Rx" SG_ 1072 DrvSlipCtlMde_D_Rq_UB 1;
BA_ "U_B515_MCA_MY17_Gas_Rx" SG_ 1072 DrvSlipCtlMde_D_Rq_UB 1;
BA_ "U_B515_MCA_MY17_Diesel_Rx" SG_ 1072 DrvSlipCtlMde_D_Rq_UB 1;
BA_ "U_B479_MY17_Diesel_Rx" SG_ 1072 DrvSlipCtlMde_D_Rq_UB 1;
BA_ "U_B479_MY17_Gas_Rx" SG_ 1072 DrvSlipCtlMde_D_Rq_UB 1;
BA_ "U_U611_U625_MY20_Hev_Rx" SG_ 1072 DrvSlipCtlMde_D_Rq 1;
BA_ "U_U611_U625_MY20_Gas_Rx" SG_ 1072 DrvSlipCtlMde_D_Rq 1;
BA_ "U_U611_U625_MY20_Diesel_Rx" SG_ 1072 DrvSlipCtlMde_D_Rq 1;
BA_ "U_B500_MY18_Diesel_Rx" SG_ 1072 DrvSlipCtlMde_D_Rq 1;
BA_ "U_B500_MY18_Gas_Rx" SG_ 1072 DrvSlipCtlMde_D_Rq 1;
BA_ "U_B562_MY18_Gas_Rx" SG_ 1072 DrvSlipCtlMde_D_Rq 1;
BA_ "U_B515_MCA_MY17_Gas_Rx" SG_ 1072 DrvSlipCtlMde_D_Rq 1;
BA_ "U_B515_MCA_MY17_Diesel_Rx" SG_ 1072 DrvSlipCtlMde_D_Rq 1;
BA_ "U_B479_MY17_Diesel_Rx" SG_ 1072 DrvSlipCtlMde_D_Rq 1;
BA_ "U_B479_MY17_Gas_Rx" SG_ 1072 DrvSlipCtlMde_D_Rq 1;
BA_ "GenSigSendType" SG_ 1072 DrvSlipCtlMde_D_Rq 3;
BA_ "CrossOver_InfoCAN" SG_ 1072 DrvSlipCtlMde_D_Rq 1;
BA_ "U_B500_MY18_Diesel_Rx" SG_ 1072 DrvSlipCtlMde_B_Rq_UB 1;
BA_ "U_B500_MY18_Gas_Rx" SG_ 1072 DrvSlipCtlMde_B_Rq_UB 1;
BA_ "U_B562_MY18_Gas_Rx" SG_ 1072 DrvSlipCtlMde_B_Rq_UB 1;
BA_ "U_B515_MCA_MY17_Gas_Rx" SG_ 1072 DrvSlipCtlMde_B_Rq_UB 1;
BA_ "U_B515_MCA_MY17_Diesel_Rx" SG_ 1072 DrvSlipCtlMde_B_Rq_UB 1;
BA_ "U_B479_MY17_Diesel_Rx" SG_ 1072 DrvSlipCtlMde_B_Rq_UB 1;
BA_ "U_B479_MY17_Gas_Rx" SG_ 1072 DrvSlipCtlMde_B_Rq_UB 1;
BA_ "U_U611_U625_MY20_Hev_Rx" SG_ 1072 DrvSlipCtlMde_B_Rq 1;
BA_ "U_U611_U625_MY20_Gas_Rx" SG_ 1072 DrvSlipCtlMde_B_Rq 1;
BA_ "U_U611_U625_MY20_Diesel_Rx" SG_ 1072 DrvSlipCtlMde_B_Rq 1;
BA_ "U_B500_MY18_Diesel_Rx" SG_ 1072 DrvSlipCtlMde_B_Rq 1;
BA_ "U_B500_MY18_Gas_Rx" SG_ 1072 DrvSlipCtlMde_B_Rq 1;
BA_ "U_B562_MY18_Gas_Rx" SG_ 1072 DrvSlipCtlMde_B_Rq 1;
BA_ "U_B515_MCA_MY17_Gas_Rx" SG_ 1072 DrvSlipCtlMde_B_Rq 1;
BA_ "U_B515_MCA_MY17_Diesel_Rx" SG_ 1072 DrvSlipCtlMde_B_Rq 1;
BA_ "U_B479_MY17_Diesel_Rx" SG_ 1072 DrvSlipCtlMde_B_Rq 1;
BA_ "U_B479_MY17_Gas_Rx" SG_ 1072 DrvSlipCtlMde_B_Rq 1;
BA_ "GenSigSendType" SG_ 1072 DrvSlipCtlMde_B_Rq 3;
BA_ "CrossOver_InfoCAN" SG_ 1072 DrvSlipCtlMde_B_Rq 1;
BA_ "U_U611_U625_MY20_Phev_Rx" SG_ 1072 ePRNDL_MODE_UB 1;
BA_ "U_CX482_CX483_MY20_Hev_Rx" SG_ 1072 ePRNDL_MODE_UB 1;
BA_ "U_CX482_CX483_MY20_Gas_Rx" SG_ 1072 ePRNDL_MODE_UB 1;
BA_ "U_CX482_CX483_MY20_Diesel_Rx" SG_ 1072 ePRNDL_MODE_UB 1;
BA_ "U_U611_U625_MY20_Hev_Rx" SG_ 1072 ePRNDL_MODE_UB 1;
BA_ "U_U611_U625_MY20_Gas_Rx" SG_ 1072 ePRNDL_MODE_UB 1;
BA_ "U_U611_U625_MY20_Diesel_Rx" SG_ 1072 ePRNDL_MODE_UB 1;
BA_ "U_C519_MY18_5_Gas_Rx" SG_ 1072 ePRNDL_MODE_UB 1;
BA_ "U_C519_MY18_5_Diesel_Rx" SG_ 1072 ePRNDL_MODE_UB 1;
BA_ "U_U611_U625_MY20_Phev_Rx" SG_ 1072 ePRNDL_MODE 1;
BA_ "U_CX482_CX483_MY20_Hev_Rx" SG_ 1072 ePRNDL_MODE 1;
BA_ "U_CX482_CX483_MY20_Gas_Rx" SG_ 1072 ePRNDL_MODE 1;
BA_ "U_CX482_CX483_MY20_Diesel_Rx" SG_ 1072 ePRNDL_MODE 1;
BA_ "U_U611_U625_MY20_Hev_Rx" SG_ 1072 ePRNDL_MODE 1;
BA_ "U_U611_U625_MY20_Gas_Rx" SG_ 1072 ePRNDL_MODE 1;
BA_ "U_U611_U625_MY20_Diesel_Rx" SG_ 1072 ePRNDL_MODE 1;
BA_ "U_C519_MY18_5_Gas_Rx" SG_ 1072 ePRNDL_MODE 1;
BA_ "U_C519_MY18_5_Diesel_Rx" SG_ 1072 ePRNDL_MODE 1;
BA_ "GenSigSendType" SG_ 1072 ePRNDL_MODE 3;
BA_ "CrossOver_InfoCAN" SG_ 1072 ePRNDL_MODE 1;
BA_ "WakeupSignal" SG_ 1072 ePRNDL_MODE 1;
BA_ "GenSigSendType" SG_ 1072 TrlrBrkMde_D_Rq 3;
BA_ "U_CX482_CX483_MY20_Hev_Rx" SG_ 1072 TRLR_SWAY_CONFIG_CMD 1;
BA_ "U_CX482_CX483_MY20_Gas_Rx" SG_ 1072 TRLR_SWAY_CONFIG_CMD 1;
BA_ "U_CX482_CX483_MY20_Diesel_Rx" SG_ 1072 TRLR_SWAY_CONFIG_CMD 1;
BA_ "U_C519_MY18_5_Gas_Rx" SG_ 1072 TRLR_SWAY_CONFIG_CMD 1;
BA_ "U_C519_MY18_5_Diesel_Rx" SG_ 1072 TRLR_SWAY_CONFIG_CMD 1;
BA_ "U_B515_MCA_MY17_Gas_Rx" SG_ 1072 TRLR_SWAY_CONFIG_CMD 1;
BA_ "U_B515_MCA_MY17_Diesel_Rx" SG_ 1072 TRLR_SWAY_CONFIG_CMD 1;
BA_ "U_B479_MY17_Diesel_Rx" SG_ 1072 TRLR_SWAY_CONFIG_CMD 1;
BA_ "U_B479_MY17_Gas_Rx" SG_ 1072 TRLR_SWAY_CONFIG_CMD 1;
BA_ "GenSigSendType" SG_ 1072 TRLR_SWAY_CONFIG_CMD 3;
BA_ "GenSigSendType" SG_ 1072 TRAILER_BRAKE_CONFIG 3;
BA_ "U_CX482_CX483_MY20_Hev_Rx" SG_ 1072 TRLR_SWAY_CONFIG_CMD_UB 1;
BA_ "U_CX482_CX483_MY20_Gas_Rx" SG_ 1072 TRLR_SWAY_CONFIG_CMD_UB 1;
BA_ "U_CX482_CX483_MY20_Diesel_Rx" SG_ 1072 TRLR_SWAY_CONFIG_CMD_UB 1;
BA_ "U_C519_MY18_5_Gas_Rx" SG_ 1072 TRLR_SWAY_CONFIG_CMD_UB 1;
BA_ "U_C519_MY18_5_Diesel_Rx" SG_ 1072 TRLR_SWAY_CONFIG_CMD_UB 1;
BA_ "U_B515_MCA_MY17_Gas_Rx" SG_ 1072 TRLR_SWAY_CONFIG_CMD_UB 1;
BA_ "U_B515_MCA_MY17_Diesel_Rx" SG_ 1072 TRLR_SWAY_CONFIG_CMD_UB 1;
BA_ "U_B479_MY17_Diesel_Rx" SG_ 1072 TRLR_SWAY_CONFIG_CMD_UB 1;
BA_ "U_B479_MY17_Gas_Rx" SG_ 1072 TRLR_SWAY_CONFIG_CMD_UB 1;
BA_ "CrossOver_InfoCAN" SG_ 1058 TqmTerrMdeChng_D_Rdy 1;
BA_ "CrossOver_InfoCAN" SG_ 1058 TqmTerrMde_D_Actl 1;
BA_ "CrossOver_InfoCAN" SG_ 1058 BattTracWarnLamp_B_Rq_UB 1;
BA_ "U_CX482_CX483_MY20_Hev_Rx" SG_ 1058 BattTracWarnLamp_B_Rq 1;
BA_ "U_CX482_CX483_MY20_Gas_Rx" SG_ 1058 BattTracWarnLamp_B_Rq 1;
BA_ "U_CX482_CX483_MY20_Diesel_Rx" SG_ 1058 BattTracWarnLamp_B_Rq 1;
BA_ "U_C519_MY18_5_Gas_Rx" SG_ 1058 BattTracWarnLamp_B_Rq 1;
BA_ "U_C519_MY18_5_Diesel_Rx" SG_ 1058 BattTracWarnLamp_B_Rq 1;
BA_ "CrossOver_InfoCAN" SG_ 1058 BattTracWarnLamp_B_Rq 1;
BA_ "CrossOver_InfoCAN" SG_ 1058 BattTracSrvcRqd_B_Rq_UB 1;
BA_ "U_CX482_CX483_MY20_Hev_Rx" SG_ 1058 BattTracSrvcRqd_B_Rq 1;
BA_ "U_CX482_CX483_MY20_Gas_Rx" SG_ 1058 BattTracSrvcRqd_B_Rq 1;
BA_ "U_CX482_CX483_MY20_Diesel_Rx" SG_ 1058 BattTracSrvcRqd_B_Rq 1;
BA_ "U_C519_MY18_5_Gas_Rx" SG_ 1058 BattTracSrvcRqd_B_Rq 1;
BA_ "U_C519_MY18_5_Diesel_Rx" SG_ 1058 BattTracSrvcRqd_B_Rq 1;
BA_ "CrossOver_InfoCAN" SG_ 1058 BattTracSrvcRqd_B_Rq 1;
BA_ "U_U611_U625_MY20_Phev_Rx" SG_ 1058 SeatBlLoPsgr_Pc_Actl_UB 1;
BA_ "U_U611_U625_MY20_Hev_Rx" SG_ 1058 SeatBlLoPsgr_Pc_Actl_UB 1;
BA_ "U_U611_U625_MY20_Gas_Rx" SG_ 1058 SeatBlLoPsgr_Pc_Actl_UB 1;
BA_ "U_U611_U625_MY20_Diesel_Rx" SG_ 1058 SeatBlLoPsgr_Pc_Actl_UB 1;
BA_ "U_U611_U625_MY20_Phev_Rx" SG_ 1058 SeatBlLoPsgr_Pc_Actl 1;
BA_ "U_U611_U625_MY20_Hev_Rx" SG_ 1058 SeatBlLoPsgr_Pc_Actl 1;
BA_ "U_U611_U625_MY20_Gas_Rx" SG_ 1058 SeatBlLoPsgr_Pc_Actl 1;
BA_ "U_U611_U625_MY20_Diesel_Rx" SG_ 1058 SeatBlLoPsgr_Pc_Actl 1;
BA_ "GenSigStartValue" SG_ 1058 SeatBlLoPsgr_Pc_Actl 127;
BA_ "CrossOver_InfoCAN" SG_ 1058 SeatBlLoPsgr_Pc_Actl 1;
BA_ "U_CX482_CX483_MY20_Hev_Rx" SG_ 1058 WndwFrontHeat_B_Stat_UB 1;
BA_ "U_CX482_CX483_MY20_Gas_Rx" SG_ 1058 WndwFrontHeat_B_Stat_UB 1;
BA_ "U_CX482_CX483_MY20_Diesel_Rx" SG_ 1058 WndwFrontHeat_B_Stat_UB 1;
BA_ "U_U611_U625_MY20_Hev_Rx" SG_ 1058 WndwFrontHeat_B_Stat_UB 1;
BA_ "U_U611_U625_MY20_Gas_Rx" SG_ 1058 WndwFrontHeat_B_Stat_UB 1;
BA_ "U_U611_U625_MY20_Diesel_Rx" SG_ 1058 WndwFrontHeat_B_Stat_UB 1;
BA_ "U_C519_MY18_5_Gas_Rx" SG_ 1058 WndwFrontHeat_B_Stat_UB 1;
BA_ "U_C519_MY18_5_Diesel_Rx" SG_ 1058 WndwFrontHeat_B_Stat_UB 1;
BA_ "U_B479_MY17_Diesel_Rx" SG_ 1058 WndwFrontHeat_B_Stat_UB 1;
BA_ "U_B479_MY17_Gas_Rx" SG_ 1058 WndwFrontHeat_B_Stat_UB 1;
BA_ "U_CX482_CX483_MY20_Hev_Rx" SG_ 1058 WndwFrontHeat_B_Stat 1;
BA_ "U_CX482_CX483_MY20_Gas_Rx" SG_ 1058 WndwFrontHeat_B_Stat 1;
BA_ "U_CX482_CX483_MY20_Diesel_Rx" SG_ 1058 WndwFrontHeat_B_Stat 1;
BA_ "U_U611_U625_MY20_Hev_Rx" SG_ 1058 WndwFrontHeat_B_Stat 1;
BA_ "U_U611_U625_MY20_Gas_Rx" SG_ 1058 WndwFrontHeat_B_Stat 1;
BA_ "U_U611_U625_MY20_Diesel_Rx" SG_ 1058 WndwFrontHeat_B_Stat 1;
BA_ "U_C519_MY18_5_Gas_Rx" SG_ 1058 WndwFrontHeat_B_Stat 1;
BA_ "U_C519_MY18_5_Diesel_Rx" SG_ 1058 WndwFrontHeat_B_Stat 1;
BA_ "U_B479_MY17_Diesel_Rx" SG_ 1058 WndwFrontHeat_B_Stat 1;
BA_ "U_B479_MY17_Gas_Rx" SG_ 1058 WndwFrontHeat_B_Stat 1;
BA_ "CrossOver_InfoCAN" SG_ 1058 HILL_DESC_SW 1;
BA_ "U_B515_MCA_MY17_Gas_Rx" SG_ 1058 EngClntTe_D_Qf 1;
BA_ "U_B515_MCA_MY17_Diesel_Rx" SG_ 1058 EngClntTe_D_Qf 1;
BA_ "U_B479_MY17_Diesel_Rx" SG_ 1058 EngClntTe_D_Qf 1;
BA_ "U_B479_MY17_Gas_Rx" SG_ 1058 EngClntTe_D_Qf 1;
BA_ "CrossOver_InfoCAN" SG_ 1058 EngClntTe_D_Qf 1;
BA_ "U_B515_MCA_MY17_Gas_Rx" SG_ 1058 EngClnt_Te_Actl_UB 1;
BA_ "U_B515_MCA_MY17_Diesel_Rx" SG_ 1058 EngClnt_Te_Actl_UB 1;
BA_ "U_B479_MY17_Diesel_Rx" SG_ 1058 EngClnt_Te_Actl_UB 1;
BA_ "U_B479_MY17_Gas_Rx" SG_ 1058 EngClnt_Te_Actl_UB 1;
BA_ "U_U611_U625_MY20_Phev_Rx" SG_ 1058 EngClnt_Te_Actl 1;
BA_ "U_CX482_CX483_MY20_Hev_Rx" SG_ 1058 EngClnt_Te_Actl 1;
BA_ "U_CX482_CX483_MY20_Gas_Rx" SG_ 1058 EngClnt_Te_Actl 1;
BA_ "U_CX482_CX483_MY20_Diesel_Rx" SG_ 1058 EngClnt_Te_Actl 1;
BA_ "U_U611_U625_MY20_Hev_Rx" SG_ 1058 EngClnt_Te_Actl 1;
BA_ "U_U611_U625_MY20_Gas_Rx" SG_ 1058 EngClnt_Te_Actl 1;
BA_ "U_U611_U625_MY20_Diesel_Rx" SG_ 1058 EngClnt_Te_Actl 1;
BA_ "U_C519_MY18_5_Gas_Rx" SG_ 1058 EngClnt_Te_Actl 1;
BA_ "U_C519_MY18_5_Diesel_Rx" SG_ 1058 EngClnt_Te_Actl 1;
BA_ "U_B515_MCA_MY17_Gas_Rx" SG_ 1058 EngClnt_Te_Actl 1;
BA_ "U_B515_MCA_MY17_Diesel_Rx" SG_ 1058 EngClnt_Te_Actl 1;
BA_ "U_B479_MY17_Diesel_Rx" SG_ 1058 EngClnt_Te_Actl 1;
BA_ "U_B479_MY17_Gas_Rx" SG_ 1058 EngClnt_Te_Actl 1;
BA_ "CrossOver_InfoCAN" SG_ 1058 EngClnt_Te_Actl 1;
BA_ "U_CX482_CX483_MY20_Hev_Rx" SG_ 1058 TrnTotTq_Rt_Est_UB 1;
BA_ "U_CX482_CX483_MY20_Gas_Rx" SG_ 1058 TrnTotTq_Rt_Est_UB 1;
BA_ "U_CX482_CX483_MY20_Diesel_Rx" SG_ 1058 TrnTotTq_Rt_Est_UB 1;
BA_ "U_B500_MY18_Diesel_Rx" SG_ 1058 TrnTotTq_Rt_Est_UB 1;
BA_ "U_B500_MY18_Gas_Rx" SG_ 1058 TrnTotTq_Rt_Est_UB 1;
BA_ "U_C519_MY18_5_Gas_Rx" SG_ 1058 TrnTotTq_Rt_Est_UB 1;
BA_ "U_C519_MY18_5_Diesel_Rx" SG_ 1058 TrnTotTq_Rt_Est_UB 1;
BA_ "U_B515_MCA_MY17_Gas_Rx" SG_ 1058 TrnTotTq_Rt_Est_UB 1;
BA_ "U_B515_MCA_MY17_Diesel_Rx" SG_ 1058 TrnTotTq_Rt_Est_UB 1;
BA_ "U_B479_MY17_Diesel_Rx" SG_ 1058 TrnTotTq_Rt_Est_UB 1;
BA_ "U_B479_MY17_Gas_Rx" SG_ 1058 TrnTotTq_Rt_Est_UB 1;
BA_ "U_CX482_CX483_MY20_Hev_Rx" SG_ 1058 TrnTotLss_Tq_Est_UB 1;
BA_ "U_CX482_CX483_MY20_Gas_Rx" SG_ 1058 TrnTotLss_Tq_Est_UB 1;
BA_ "U_CX482_CX483_MY20_Diesel_Rx" SG_ 1058 TrnTotLss_Tq_Est_UB 1;
BA_ "U_B500_MY18_Diesel_Rx" SG_ 1058 TrnTotLss_Tq_Est_UB 1;
BA_ "U_B500_MY18_Gas_Rx" SG_ 1058 TrnTotLss_Tq_Est_UB 1;
BA_ "U_C519_MY18_5_Gas_Rx" SG_ 1058 TrnTotLss_Tq_Est_UB 1;
BA_ "U_C519_MY18_5_Diesel_Rx" SG_ 1058 TrnTotLss_Tq_Est_UB 1;
BA_ "U_B515_MCA_MY17_Gas_Rx" SG_ 1058 TrnTotLss_Tq_Est_UB 1;
BA_ "U_B515_MCA_MY17_Diesel_Rx" SG_ 1058 TrnTotLss_Tq_Est_UB 1;
BA_ "U_B479_MY17_Diesel_Rx" SG_ 1058 TrnTotLss_Tq_Est_UB 1;
BA_ "U_B479_MY17_Gas_Rx" SG_ 1058 TrnTotLss_Tq_Est_UB 1;
BA_ "U_CX482_CX483_MY20_Hev_Rx" SG_ 1058 TrnTotTq_Rt_Est 1;
BA_ "U_CX482_CX483_MY20_Gas_Rx" SG_ 1058 TrnTotTq_Rt_Est 1;
BA_ "U_CX482_CX483_MY20_Diesel_Rx" SG_ 1058 TrnTotTq_Rt_Est 1;
BA_ "U_B500_MY18_Diesel_Rx" SG_ 1058 TrnTotTq_Rt_Est 1;
BA_ "U_B500_MY18_Gas_Rx" SG_ 1058 TrnTotTq_Rt_Est 1;
BA_ "U_C519_MY18_5_Gas_Rx" SG_ 1058 TrnTotTq_Rt_Est 1;
BA_ "U_C519_MY18_5_Diesel_Rx" SG_ 1058 TrnTotTq_Rt_Est 1;
BA_ "U_B515_MCA_MY17_Gas_Rx" SG_ 1058 TrnTotTq_Rt_Est 1;
BA_ "U_B515_MCA_MY17_Diesel_Rx" SG_ 1058 TrnTotTq_Rt_Est 1;
BA_ "U_B479_MY17_Diesel_Rx" SG_ 1058 TrnTotTq_Rt_Est 1;
BA_ "U_B479_MY17_Gas_Rx" SG_ 1058 TrnTotTq_Rt_Est 1;
BA_ "ContentDependant" SG_ 1058 TrnTotTq_Rt_Est 1;
BA_ "CrossOver_InfoCAN" SG_ 1058 TrnTotTq_Rt_Est 1;
BA_ "U_CX482_CX483_MY20_Hev_Rx" SG_ 1058 TrnTotLss_Tq_Est 1;
BA_ "U_CX482_CX483_MY20_Gas_Rx" SG_ 1058 TrnTotLss_Tq_Est 1;
BA_ "U_CX482_CX483_MY20_Diesel_Rx" SG_ 1058 TrnTotLss_Tq_Est 1;
BA_ "U_B500_MY18_Diesel_Rx" SG_ 1058 TrnTotLss_Tq_Est 1;
BA_ "U_B500_MY18_Gas_Rx" SG_ 1058 TrnTotLss_Tq_Est 1;
BA_ "U_C519_MY18_5_Gas_Rx" SG_ 1058 TrnTotLss_Tq_Est 1;
BA_ "U_C519_MY18_5_Diesel_Rx" SG_ 1058 TrnTotLss_Tq_Est 1;
BA_ "U_B515_MCA_MY17_Gas_Rx" SG_ 1058 TrnTotLss_Tq_Est 1;
BA_ "U_B515_MCA_MY17_Diesel_Rx" SG_ 1058 TrnTotLss_Tq_Est 1;
BA_ "U_B479_MY17_Diesel_Rx" SG_ 1058 TrnTotLss_Tq_Est 1;
BA_ "U_B479_MY17_Gas_Rx" SG_ 1058 TrnTotLss_Tq_Est 1;
BA_ "ContentDependant" SG_ 1058 TrnTotLss_Tq_Est 1;
BA_ "CrossOver_InfoCAN" SG_ 1058 TrnTotLss_Tq_Est 1;
BA_ "U_CX482_CX483_MY20_Hev_Rx" SG_ 1058 DrvSlipCtlMde_B_Rq2_UB 1;
BA_ "U_CX482_CX483_MY20_Gas_Rx" SG_ 1058 DrvSlipCtlMde_B_Rq2_UB 1;
BA_ "U_CX482_CX483_MY20_Diesel_Rx" SG_ 1058 DrvSlipCtlMde_B_Rq2_UB 1;
BA_ "U_B500_MY18_Diesel_Rx" SG_ 1058 DrvSlipCtlMde_B_Rq2_UB 1;
BA_ "U_B500_MY18_Gas_Rx" SG_ 1058 DrvSlipCtlMde_B_Rq2_UB 1;
BA_ "U_B562_MY18_Gas_Rx" SG_ 1058 DrvSlipCtlMde_B_Rq2_UB 1;
BA_ "U_C519_MY18_5_Gas_Rx" SG_ 1058 DrvSlipCtlMde_B_Rq2_UB 1;
BA_ "U_C519_MY18_5_Diesel_Rx" SG_ 1058 DrvSlipCtlMde_B_Rq2_UB 1;
BA_ "U_B515_MCA_MY17_Gas_Rx" SG_ 1058 DrvSlipCtlMde_B_Rq2_UB 1;
BA_ "U_B515_MCA_MY17_Diesel_Rx" SG_ 1058 DrvSlipCtlMde_B_Rq2_UB 1;
BA_ "U_B479_MY17_Diesel_Rx" SG_ 1058 DrvSlipCtlMde_B_Rq2_UB 1;
BA_ "U_B479_MY17_Gas_Rx" SG_ 1058 DrvSlipCtlMde_B_Rq2_UB 1;
BA_ "U_CX482_CX483_MY20_Hev_Rx" SG_ 1058 DrvSlipCtlMde_B_Rq2 1;
BA_ "U_CX482_CX483_MY20_Gas_Rx" SG_ 1058 DrvSlipCtlMde_B_Rq2 1;
BA_ "U_CX482_CX483_MY20_Diesel_Rx" SG_ 1058 DrvSlipCtlMde_B_Rq2 1;
BA_ "U_B500_MY18_Diesel_Rx" SG_ 1058 DrvSlipCtlMde_B_Rq2 1;
BA_ "U_B500_MY18_Gas_Rx" SG_ 1058 DrvSlipCtlMde_B_Rq2 1;
BA_ "U_B562_MY18_Gas_Rx" SG_ 1058 DrvSlipCtlMde_B_Rq2 1;
BA_ "U_C519_MY18_5_Gas_Rx" SG_ 1058 DrvSlipCtlMde_B_Rq2 1;
BA_ "U_C519_MY18_5_Diesel_Rx" SG_ 1058 DrvSlipCtlMde_B_Rq2 1;
BA_ "U_B515_MCA_MY17_Gas_Rx" SG_ 1058 DrvSlipCtlMde_B_Rq2 1;
BA_ "U_B515_MCA_MY17_Diesel_Rx" SG_ 1058 DrvSlipCtlMde_B_Rq2 1;
BA_ "U_B479_MY17_Diesel_Rx" SG_ 1058 DrvSlipCtlMde_B_Rq2 1;
BA_ "U_B479_MY17_Gas_Rx" SG_ 1058 DrvSlipCtlMde_B_Rq2 1;
BA_ "CrossOver_InfoCAN" SG_ 1058 DrvSlipCtlMde_B_Rq2 1;
VAL_ 1073 CamraFrntBttn_D_Stat 1 "Pressed" 0 "Not_Pressed" ;
VAL_ 1073 CamraFrntBttn_D_Stat_UB 1 "Fresh_data" 0 "Unchanged_data" ;
VAL_ 1073 BrkDrvMde_D_Rq_UB 1 "Fresh_data" 0 "Unchanged_data" ;
VAL_ 1073 BrkDrvMde_D_Rq 7 "Faulty" 6 "RockCrawl" 5 "Baja" 4 "DragOrMudAndSand" 3 "Track" 2 "Snow_Wet" 1 "Sport" 0 "Normal" ;
VAL_ 1073 SteEffort_D_Rq 7 "NotUsed_3" 6 "NotUsed_2" 5 "NotUsed_1" 4 "SpecialMode_2" 3 "SpecialMode_1" 2 "Comfort" 1 "Sport" 0 "Normal" ;
VAL_ 1073 SteEffort_D_Rq_UB 1 "Fresh_data" 0 "Unchanged_data" ;
VAL_ 1073 AutoHoldSwtch_D_Stat_UB 1 "Fresh_data" 0 "Unchanged_data" ;
VAL_ 1073 AutoHoldSwtch_D_Stat 3 "Faulty" 2 "NotUsed" 1 "Pressed" 0 "Not_Pressed" ;
VAL_ 1073 HMI_HMIMode_St_UB 1 "Fresh_data" 0 "Unchanged_data" ;
VAL_ 1073 HMI_HMIMode_St 7 "NotUsed2" 6 "NotUsed1" 5 "Load_Shed_Active" 0 "Invalid" 1 "OffMode" 2 "On" 3 "Phone" 4 "Climate" ;
VAL_ 1073 Veh_Lock_Requestor_UB 1 "Fresh_data" 0 "Unchanged_data" ;
VAL_ 1073 Veh_Lock_EvNum_UB 1 "Fresh_data" 0 "Unchanged_data" ;
VAL_ 1073 Veh_Lock_Sub_Id_UB 1 "Fresh_data" 0 "Unchanged_data" ;
VAL_ 1073 Tire_Press_System_Stat_UB 1 "Fresh_data" 0 "Unchanged_data" ;
VAL_ 1073 Veh_Lock_Status_UB 1 "Fresh_data" 0 "Unchanged_data" ;
VAL_ 1073 Veh_Lock_Sub_Id 15 "Unused7" 14 "Unused6" 13 "Unused5" 12 "Unused4" 11 "Unused3" 10 "Unused2" 9 "Unused1" 8 "Customer_8" 7 "Customer_7" 6 "Customer_6" 5 "Customer_5" 4 "Customer_4" 3 "Customer_3" 2 "Customer_2" 1 "Customer_1" 0 "Null" ;
VAL_ 1073 Veh_Lock_Status 3 "UNLOCK_DRV" 2 "UNLOCK_ALL" 1 "LOCK_ALL" 0 "LOCK_DBL" ;
VAL_ 1073 Veh_Lock_Requestor 31 "Unused8" 30 "Unused7" 29 "Unused6" 28 "Unused5" 27 "Unused4" 26 "Transit_Vehicle_Relock" 25 "Transit_Cargo_Relock" 24 "Transit_Ajar_Lock" 23 "Diagnostics" 22 "Console_Lock" 21 "Child_Lock" 20 "Double_Lock" 19 "Passive_Pasenger" 18 "Passive_Driver" 17 "Slam_Lock_Protect" 16 "SYNC" 15 "Passport" 14 "Passive_Smart_Unlock" 13 "Autorelock" 12 "RemoteStart" 0 "Null" 1 "Autolock" 11 "Smart_Unlock" 10 "Sliding_Door" 9 "Passive" 8 "Remote" 7 "Programming" 6 "Powerslide" 5 "Keypad" 4 "Key_Cylinder" 3 "Interior" 2 "Auto_Unlock" ;
VAL_ 1073 Tire_Press_System_Stat 13 "Training_Complete" 12 "Train_InsideLeftRear_tire" 11 "Train_OutsideLeftRear_tire" 10 "Train_LeftRear_tire" 9 "Train_InsideRtRear_tire" 8 "Train_OutsideRtRear_tire" 7 "Train_RightRear_tire" 14 "Tires_not_trained" 6 "Train_RightFront_tire" 5 "Train_LeftFront_tire" 4 "Systm_Activ_Composite_Stat" 3 "Low_Composite_Stat" 2 "Sensr_Fault_Composite_Stat" 1 "Systm_Fault_Composite_Stat" 0 "Unknown_Composite_Stat" ;
VAL_ 1073 DISPLAY_SPEED_OFFSET_UB 1 "Fresh_data" 0 "Unchanged_data" ;
VAL_ 1073 DISPLAY_SPEED_SCALING_UB 1 "Fresh_data" 0 "Unchanged_data" ;
VAL_ 1073 Foh_D_Stat 7 "Unused3" 6 "Unused2" 5 "Unused1" 4 "Stopping" 3 "Running" 2 "Starting" 1 "Prestart" 0 "Off" ;
VAL_ 1073 Foh_D_Stat_UB 1 "Fresh_data" 0 "Unchanged_data" ;
VAL_ 1073 SteWhlHeat_D_Rq_UB 1 "Fresh_data" 0 "Unchanged_data" ;
VAL_ 1073 SteWhlHeat_D_Rq 15 "NotUsed6" 14 "NotUsed5" 13 "NotUsed4" 12 "NotUsed3" 11 "NotUsed2" 10 "NotUsed1" 9 "Reserved_3" 8 "Reserved_2" 7 "Reserved_1" 6 "Level_3_Heating" 5 "Level_3_Heating_LS" 4 "Level_2_Heating" 3 "Level_2_Heating_LS" 2 "Level_1_Heating" 1 "Level_1_Heating_LS" 0 "Off" ;
VAL_ 1092 TbsLamp_D_RqDsply 3 "Not_Used" 2 "Flash" 1 "On" 0 "Off" ;
VAL_ 71 immoTarget1Status 7 "Unused4" 6 "Unused3" 5 "Unused2" 4 "Unused1" 3 "DISABLED_RESET   " 2 "ENABLED_NONMOTIVE_START" 1 "ENABLED_MOTIVE_START" 0 "DISABLED" ;
VAL_ 71 immoTarget1Cmd 7 "Unused4" 6 "Unused3" 5 "Unused2" 4 "Unused1" 3 "TARGET1_IDBLOCK2" 2 "TARGET1_IDBLOCK1" 1 "CHALLENGE" 0 "IDLE" ;
VAL_ 973 TsrVl2PrmntMsgTxt_D_Rq 3 "NotUsed" 2 "ShowPermanentlyWithSupp" 1 "ShowPermanentlyWithoutSupp" 0 "DoNotShowSignPermanent" ;
VAL_ 973 TsrVl1PrmntMsgTxt_D_Rq 3 "NotUsed" 2 "ShowPermanentlyWithSupp" 1 "ShowPermanentlyWithoutSupp" 0 "DoNotShowSignPermanent" ;
VAL_ 973 TsrVl2RstrcMsgTxt2_D_Rq 7 "NotUsed" 6 "Time" 5 "Trailer" 4 "Snow" 3 "RainWet" 2 "NoRecognizableRestrictn" 1 "NoSpeedLimitRestrictn" 0 "Null" ;
VAL_ 973 TsrVl1RstrcMsgTxt2_D_Rq 7 "NotUsed" 6 "Time" 5 "Trailer" 4 "Snow" 3 "RainWet" 2 "NoRecognizableRestrictn" 1 "NoSpeedLimitRestrictn" 0 "Null" ;
VAL_ 973 TsrOvtkMsgTxt2_D_Rq 15 "NotUsed5" 14 "NotUsed4" 13 "NotUsed3" 12 "NotUsed2" 11 "NotUsed1" 10 "LimForTrucksCancelled" 9 "LimForTrucksWoQlfdRstrc" 8 "LimForTrucksWithoutRstrc" 7 "LimAllCancelled" 6 "LimAllWithRstrcTime" 5 "LimAllWithRstrcTrailer" 4 "LimAllWithRstrcSnow" 3 "LimAllWithRstrcRain" 2 "LimAllWithoutQlfdRstrc" 1 "LimAllWithoutRestriction" 0 "OvertakingAllowed" ;
VAL_ 973 WwaWarn_B_Rq 1 "On" 0 "Off" ;
VAL_ 973 TsrVlUnitMsgTxt_D_Rq 3 "NoDataExists" 2 "Mph" 1 "Kph" 0 "Null" ;
VAL_ 973 TsrVLim2MsgTxt_D_Rq 255 "NoLimit" 254 "NotUsed2" 253 "NotUsed1" 252 "NotToBeDisplayed" 251 "LimitCancelled" 31 "1F_FA_Message31_250" 30 "Message30" 29 "Message29" 28 "Message28" 27 "Message27" 26 "Message26" 25 "Message25" 24 "Message24" 23 "Message23" 22 "Message22" 21 "Message21" 20 "Message20" 19 "Message19" 18 "Message18" 17 "Message17" 16 "Message16" 15 "Message15" 14 "Message14" 13 "Message13" 12 "Message12" 11 "Message11" 10 "Message10" 9 "Message9" 8 "Message8" 7 "Message7" 6 "Message6" 5 "Message5" 4 "Message4" 3 "Message3" 2 "Message2" 1 "Message1" 0 "Null" ;
VAL_ 973 TsrVLim1MsgTxt_D_Rq 255 "NoLimit" 254 "NotUsed2" 253 "NotUsed1" 252 "NotToBeDisplayed" 251 "LimitCancelled" 31 "1F_FA_Message31_250" 30 "Message30" 29 "Message29" 28 "Message28" 27 "Message27" 26 "Message26" 25 "Message25" 24 "Message24" 23 "Message23" 22 "Message22" 21 "Message21" 20 "Message20" 19 "Message19" 18 "Message18" 17 "Message17" 16 "Message16" 15 "Message15" 14 "Message14" 13 "Message13" 12 "Message12" 11 "Message11" 10 "Message10" 9 "Message9" 8 "Message8" 7 "Message7" 6 "Message6" 5 "Message5" 4 "Message4" 3 "Message3" 2 "Message2" 1 "Message1" 0 "Null" ;
VAL_ 973 TsrVl2TypeMsgTxt_D_Rq 3 "NotUsed" 2 "Explicit" 1 "Implicit" 0 "Null" ;
VAL_ 973 TsrVl2StatMsgTxt_D_Rq 3 "LimitOutdated" 2 "LimitReiable" 1 "LimitChanged" 0 "Null" ;
VAL_ 973 TsrVl2RstrcMsgTxt_D_Rq 3 "NotUsed" 2 "NoRecognizableRestriction" 1 "NoSpeedLimitRestriction" 0 "Null" ;
VAL_ 973 TsrVl1TypeMsgTxt_D_Rq 3 "NotUsed" 2 "Explicit" 1 "Implicit" 0 "Null" ;
VAL_ 973 TsrVl1StatMsgTxt_D_Rq 3 "LimitOutdated" 2 "LimitReiable" 1 "LimitChanged" 0 "Null" ;
VAL_ 973 TsrVl1RstrcMsgTxt_D_Rq 3 "NotUsed" 2 "NoRecognizableRestriction" 1 "NoSpeedLimitRestriction" 0 "Null" ;
VAL_ 973 TsrStatMsgTxt_D_Rq 7 "NotUsed" 6 "NoDataExists" 5 "TSR_Error" 4 "Available_NavigationOnly" 3 "Available_CameraOnly" 2 "Available_FusionMode" 1 "TSR_Off" 0 "Null" ;
VAL_ 973 TsrOvtkTypeMsgTxt_D_Rq 3 "NotUsed" 2 "Explicit" 1 "Implicit" 0 "Null" ;
VAL_ 973 TsrOvtkStatMsgTxt_D_Rq 3 "LimitOutdated" 2 "LimitReiable" 1 "LimitChanged" 0 "Null" ;
VAL_ 973 TsrOvtkMsgTxt_D_Rq 7 "LimForTrucksCancelled" 6 "LimForTrucksWoQlfdRstrc" 5 "LimForTrucksWithoutRstrc" 4 "LimAllCancelled" 3 "LimAllWithoutQlfdRstrc" 2 "LimAllWithoutRestriction" 1 "OvertakingAllowed" 0 "Null" ;
VAL_ 973 TsrOswWarnMsgTxt_D_Rq 3 "NotUsed" 2 "True" 1 "False" 0 "Null" ;
VAL_ 973 TsrMsgTxt_D_Rq 15 "NotUsed6" 14 "NotUsed5" 13 "NotUsed4" 12 "NotUsed3" 11 "NotUsed2" 10 "NotUsed1" 9 "RecgnzdSignNotUsblForDsply" 8 "LimitedSystemPerformance" 7 "OffRoad" 6 "RegionNotSupported" 5 "CountryNotSupported" 4 "WrngNavDatIncompDatCarrier" 3 "NoNavDataAvailable" 2 "NoNavAvailableSwitchedOff" 1 "NoInformationAllOK" 0 "Null" ;
VAL_ 825 WndwFrontHeat_B_Rq 1 "On" 0 "Off" ;
VAL_ 825 FdsmTrgRight_B_Actl 1 "Object_in_Right_Lobe" 0 "No_Object" ;
VAL_ 825 FdsmTrgLeft_B_Actl 1 "Object_in_Left_Lobe" 0 "No_Object" ;
VAL_ 825 FdsmTrgCntr_B_Actl 1 "Object_in_Center_Lobe" 0 "No_Object" ;
VAL_ 825 LscmbbSrvcRqd_B_Rq 1 "Yes" 0 "No" ;
VAL_ 825 LscmbbPostEvnt_B_Dsply 1 "Yes" 0 "No" ;
VAL_ 825 LscmbbEngTqMn_B_Rq 1 "Engine_Braking" 0 "No_Engine_Braking" ;
VAL_ 825 LscmbbMsgTxt_D_Rq 1 "Yes" 0 "No" ;
VAL_ 825 LscmbbDeny_B_Actl 1 "Denied" 0 "Allowed" ;
VAL_ 825 LscmbbBrkPrchg_D_Rq 3 "NotUsed" 2 "Level2_PreCharge" 1 "Level1_PreCharge" 0 "No_Precharge" ;
VAL_ 825 LscmbbBrkDecel_B_Enbl 1 "ConductLSCMbBDecelReq" 0 "DoNotConductLSCMbBDecelReq" ;
VAL_ 825 LscmbbBlck_B_Actl 1 "Yes" 0 "No" ;
VAL_ 825 LscmbbBaSens_D_Rq 3 "Level3_EBA" 2 "Level2_EBA" 1 "Level1_EBA" 0 "Norman_EBA" ;
VAL_ 837 SuspVLim_B_Rq 1 "True" 0 "False" ;
VAL_ 837 SelDrvMdeSusp_D_Stat 3 "Faulty" 2 "TemporarilyNotAvailable" 1 "Available" 0 "NotAvailable" ;
VAL_ 837 AdptDrvMdePt_D_Rq 7 "Faulty" 6 "NotUsed3" 5 "NotUsed2" 4 "NotUsed1" 3 "Powertrain2Sport" 2 "Powertrain2Normal" 1 "Powertrain2Comfort" 0 "AdaptiveNotActive" ;
VAL_ 837 AdptDrvMdeChassis_D_Rq 7 "Faulty" 6 "NotUsed3" 5 "NotUsed2" 4 "NotUsed1" 3 "Chassis2Sport" 2 "Chassis2Normal" 1 "Chassis2Comfort" 0 "AdaptiveNotActive" ;
VAL_ 837 AirSprngRateRr_D_Rq 3 "NoRequest" 2 "Firm" 1 "Medium" 0 "Soft" ;
VAL_ 837 AirSprngRateRl_D_Rq 3 "NoRequest" 2 "Firm" 1 "Medium" 0 "Soft" ;
VAL_ 837 AirSprngRateFr_D_Rq 3 "NoRequest" 2 "Firm" 1 "Medium" 0 "Soft" ;
VAL_ 837 AirSprngRateFl_D_Rq 3 "NoRequest" 2 "Firm" 1 "Medium" 0 "Soft" ;
VAL_ 837 BrkPadMsgTxt_D_Rq 3 "Faulty" 2 "PadsOk" 1 "ReplacePads" 0 "Null" ;
VAL_ 837 AirSusp_D_Stat 3 "NotUsed" 2 "On" 1 "Off" 0 "Null" ;
VAL_ 837 AirSuspMsgTxt_D_Rq 3 "NotUsed" 2 "Faulty" 1 "Override" 0 "NoMessage" ;
VAL_ 837 SuspDrvMde_D_Stat 7 "Faulty" 6 "NotUsed2" 5 "NotUsed1" 4 "Drag" 3 "Track" 2 "Snow_Wet" 1 "Sport" 0 "Normal" ;
VAL_ 837 CcdMsgTxt_D_RqDsply 15 "Unused8" 14 "Unused7" 13 "Unused6" 12 "Unused5" 11 "Unused4" 10 "Unused3" 9 "Unused2" 8 "Unused1" 7 "Mode_Change_Unavailable" 6 "CCD_Temporarily_Off" 5 "CCD_Service_Required" 4 "Fault" 3 "Sport" 2 "Normal" 1 "Comfort" 0 "No_Mode_Selected" ;
VAL_ 1091 TowBarMsgTxt_D_Rq 7 "NotUsed3" 6 "NotUsed2" 5 "NotUsed1" 4 "TowBar_Ext_No_Trlr" 3 "Error_Dealer_Fix" 2 "Start_Engine_Swivel" 1 "Check_Tow_Bar" 0 "Null" ;
VAL_ 1091 ParkLampTrlrOut_B_Stat 1 "Out" 0 "Null" ;
VAL_ 1091 StopLampTrlrOut_B_Stat 1 "Out" 0 "Null" ;
VAL_ 1091 TrlrBattChrg_D_Stat 3 "Reverse" 2 "Normal" 1 "Low" 0 "Null" ;
VAL_ 1091 TrlrLampCtl_D_Stat 3 "NotUsed" 2 "TrlrLampCnnctDrvFailure" 1 "TrlrLampNotCnnctDrvFailure" 0 "Null" ;
VAL_ 1091 TurnLampTrlrRr_B_Stat 1 "Out" 0 "Null" ;
VAL_ 1091 TurnLampTrlrRl_B_Stat 1 "Out" 0 "Null" ;
VAL_ 1091 TrlrLampCnnct_B_Actl 1 "Yes" 0 "No" ;
VAL_ 1068 EngStrtInhbt_B_RqBatt 1 "Start_Inhibit" 0 "Dont_Care" ;
VAL_ 1068 BattULoChrg_D_Rq 3 "Low_Battery_Temperature" 2 "Charging_Requested" 1 "Chrg_Requested_HighCurrent" 0 "No_Request" ;
VAL_ 1068 PwSysULoFalt_D_Stat 15 "Not_Used_6" 14 "LowBatterySOC" 13 "PSS_Shed2_Contin" 12 "Not_Used_4" 11 "Not_Used_3" 10 "Not_Used_2" 9 "BattMonitoringSensorFault" 8 "LowBattVoltDuringPwSrcOn" 7 "LowBatt2_PowerSaveMode" 6 "LowBatt1_Warning" 5 "Overvoltage" 4 "Fault_NoOutput" 3 "Fault_ReducedOutput" 2 "Fault_Nonspecific" 1 "Cluster_Proveout" 0 "No_Fault" ;
VAL_ 1068 Shed_T_Eng_Off_B 1 "Active" 0 "Inactive" ;
VAL_ 1068 Shed_Feature_Group_ID 14 "HtdMirr" 13 "HvacRearBlwr_Third" 12 "HvacRearBlwr_Second" 11 "HvacRearBlwr_First" 31 "All LSHED1 Features" 10 "Htd_Windscrn" 9 "SpltHtdBcklight_HtdMirr" 8 "HtdBcklight_HtdMirr" 7 "HtdCoolSeat_FrtDriver" 6 "HtdCoolSeat_FrtPass" 5 "HtdCoolSeat_RearPass" 4 "HtdCoolSeat_RearDriver" 3 "SmartTrlrTowBattCharge" 2 "Htd_StrWhl" 1 "Htd_Washer_Fluid" 0 "No_LSHED1_Features" 15 "Engine_Coolant_Fan" ;
VAL_ 1068 Shed_Drain_Eng_Off_B 1 "Active" 0 "Inactive" ;
VAL_ 1068 Shed_Level_Req 7 "Unused_2" 6 "Loads_On" 5 "SHED_ENG_OFF" 4 "SOON_ENG_OFF" 3 "SHED2_CONTIN" 2 "SHED2_TRANS" 1 "SHED1" 0 "NO_SHED" ;
VAL_ 1068 ChargeMode 7 "Undefined_2" 6 "Undefined_1" 5 "Battery_Identify" 4 "Battery_Refresh" 3 "SlowRegenAllowNoDischarge" 2 "Fast_Regen_Allowed" 1 "Slow_Regen_Allowed" 0 "Conventional_Charging" ;
VAL_ 1068 IdleSpeedIncrease_El 1 "Yes" 0 "No" ;
VAL_ 1068 Batt_Lo_SoC_B 1 "Active" 0 "Inactive" ;
VAL_ 1068 PeriodicElLoad_B_Stat 1 "Active" 0 "Inactive" ;
VAL_ 1068 Batt_Crit_SoC_B 1 "Active" 0 "Inactive" ;
VAL_ 1068 ULoRgenTestMde_B_Rq 1 "Request" 0 "NoRequest" ;
VAL_ 611 AwdTerrMdeChng_D_Rdy 7 "Fault" 6 "Undefined_2" 5 "Undefined_1" 4 "ModeUnavailDrInputRqd" 3 "SpOpModes_NotSupported" 2 "ModeUnavailDynamicCond" 1 "Module_In_Initialization" 0 "Mode_Change_Available" ;
VAL_ 611 AwdTerrMde_D_Actl 7 "Fail_Safe_Default" 6 "Dynamic_Mode" 5 "Rock_Crawl_Mode" 4 "Mud_Ruts_Mode" 3 "Sand_Mode" 2 "Undefined" 1 "Low_Mu_Mode" 0 "Special_Operating_Mode_Off" ;
VAL_ 611 AwdSys_D_Stat 3 "Faulty" 2 "NotUsed" 1 "_4x4_L_H_Active" 0 "_4x4_L_H_Inactive" ;
VAL_ 611 SelDrvMdeAwd_D_Stat 3 "Faulty" 2 "TemporarilyNotAvailable" 1 "Available" 0 "NotAvailable" ;
VAL_ 611 AwdStat_D_RqDsply 31 "NotUsed9" 30 "NotUsed8" 29 "NotUsed7" 28 "NotUsed6" 27 "NotUsed5" 26 "NotUsed4" 25 "Lkr_Mode_Unavail_TMS" 24 " _4x4_Mode_Unavail_TMS" 23 "Out_of_4Low_Crawl" 22 "AWD_PTU_Oil_Changed" 21 "Change_AWD_PTU_Oil" 20 "Neutral_Tow_Disabled" 19 "Neutral_Tow_Enabled" 18 "AWD_OFF" 17 "_4x4_Off_Road_Speed" 16 "_4x4_Extreme_Off_Road_Mode" 15 "_4x4_Exiting_Off_Road" 14 "_4x4_Off_Road_Mode" 10 "_4x4_Locked_Temporarily" 9 "Shift_In_Progress" 13 "Blocked_Shift_Assist" 12 "_4x4_Auto_Restored" 11 "_4x4_Disabled_Temporarily" 7 "Out_of_4Low__Neutral" 6 "Out_of_4Low__Brake" 5 "Out_of_4Low__Speed" 4 "Into_4Low__Clutch" 3 "Into_4Low__Neutral" 2 "Into_4Low__Brake" 1 "Into_4Low__Speed" 0 "Normal__No_Message" 8 "Out_of_4Low__Clutch" ;
VAL_ 611 AwdLck_D_Stat 9 "Undefined" 8 "Under_External_Torque_Ctrl" 7 "Torque_Limited_by_Cmd" 6 "Fully_Locked_by_Cmd" 5 "Disabled" 4 "Warning" 3 "Fault" 2 "Inactive" 1 "Completely_Opened_by_Cmd" 0 "OK" ;
VAL_ 611 AwdSrvcRqd_B_Rq 1 "On" 0 "Off" ;
VAL_ 611 AwdDrvMde_D_Stat 7 "Faulty" 6 "NotAvailable" 5 "RockCrawl" 4 "Baja" 3 "MudAndSand" 2 "Weather" 1 "Sport" 0 "Normal" ;
VAL_ 611 NtrlTowAvail_B_Stat 1 "Available" 0 "NotAvailable" ;
VAL_ 611 AwdLck_Tq_Rq 4095 "Fault" 4094 "Unknown" ;
VAL_ 611 AwdOffRoadMode_D_Stats 3 "Invalid" 2 "Extreme_Off_Road" 1 "Off_Road" 0 "Normal_Mode" ;
VAL_ 611 AwdLoLamp_D_RqDsply 3 "Not_Used" 2 "Flash" 1 "On" 0 "Off" ;
VAL_ 611 AwdHiLamp_D_RqDsply 3 "Not_Used" 2 "Flash" 1 "On" 0 "Off" ;
VAL_ 611 AwdAutoLamp_D_RqDsply 3 "Not_Used" 2 "Flash" 1 "On" 0 "Off" ;
VAL_ 611 Awd2wdLamp_D_RqDsply 3 "Not_Used" 2 "Flash" 1 "On" 0 "Off" ;
VAL_ 611 AwdRnge_D_Actl 7 "Unknown" 6 "High_Range_2wd" 5 "High_Range_Auto" 4 "High_Range_Locked" 3 "Neutral" 2 "Low_Range_2wd" 1 "Low_Range_Auto" 0 "Low_Range_Locked" ;
VAL_ 395 HudMde_D_Rq 7 "NotUsed3" 6 "NotUsed2" 5 "NotUsed1" 4 "Manual" 3 "Drag" 2 "RoadCourse" 1 "Tach" 0 "Off" ;
VAL_ 395 HudLedMde_D_Rq 3 "Not_Used" 2 "Flash" 1 "On" 0 "Off" ;
VAL_ 395 HudLed9On_B_Rq 1 "On" 0 "Off" ;
VAL_ 395 HudLed8On_B_Rq 1 "On" 0 "Off" ;
VAL_ 395 HudLed7On_B_Rq 1 "On" 0 "Off" ;
VAL_ 395 HudLed6On_B_Rq 1 "On" 0 "Off" ;
VAL_ 395 HudLed5On_B_Rq 1 "On" 0 "Off" ;
VAL_ 395 HudLed4On_B_Rq 1 "On" 0 "Off" ;
VAL_ 395 HudLed3On_B_Rq 1 "On" 0 "Off" ;
VAL_ 395 HudLed2On_B_Rq 1 "On" 0 "Off" ;
VAL_ 395 HudLed1On_B_Rq 1 "On" 0 "Off" ;
VAL_ 395 HudLed18On_B_Rq 1 "On" 0 "Off" ;
VAL_ 395 HudLed17On_B_Rq 1 "On" 0 "Off" ;
VAL_ 395 HudLed16On_B_Rq 1 "On" 0 "Off" ;
VAL_ 395 HudLed15On_B_Rq 1 "On" 0 "Off" ;
VAL_ 395 HudLed14On_B_Rq 1 "On" 0 "Off" ;
VAL_ 395 HudLed13On_B_Rq 1 "On" 0 "Off" ;
VAL_ 395 HudLed12On_B_Rq 1 "On" 0 "Off" ;
VAL_ 395 HudLed11On_B_Rq 1 "On" 0 "Off" ;
VAL_ 395 HudLed10On_B_Rq 1 "On" 0 "Off" ;
VAL_ 578 PtLatchActv_B_RqBcm 1 "On" 0 "Off" ;
VAL_ 578 PrkLckCtlUnlck_D_Stat 3 "Trans_And_Steer_Unlckd" 2 "Steering_Unlckd" 1 "Transmission_Unlckd" 0 "Null" ;
VAL_ 578 PrkLckCtlTow_B_Enbl 1 "Enable" 0 "Disable" ;
VAL_ 578 immoSecureIdleMode 3 "NotUsed2" 2 "NotUsed1" 1 "Active" 0 "Inactive" ;
VAL_ 578 FuelPumpPwr_D_Stat 7 "NotUsed3" 6 "NotUsed2" 5 "NotUsed1" 4 "Power_Off_Default" 3 "Power_Off_Command" 2 "Power_Off_Service" 1 "Power_Off_Impact" 0 "Power_On" ;
VAL_ 578 BattULo_U_Actl 255 "Fault" ;
VAL_ 578 PrkLckCtl_B_Enbl 1 "Enable" 0 "Disable" ;
VAL_ 578 PrkLckCtlMsgTxt_D_Rq 3 "BTSI_DI_3" 2 "BTSI_DI_2" 1 "BTSI_DI_1" 0 "Null_BTSI_DI" ;
VAL_ 578 BrkTrnShifLck_B_Stat 1 "Shift" 0 "NoShift" ;
VAL_ 578 DriverCrankingReq 1 "Crank_Request" 0 "No_Crank_Request" ;
VAL_ 578 EngOff_T_Actl 65535 "Invalid" ;
VAL_ 578 ReFuelSwtchStat_D_Actl 3 "NotUsed2" 2 "NotUsed1" 1 "On" 0 "Off" ;
VAL_ 578 DcacElPw_D_Rq 3 "NotUsed" 2 "AC_HighPower_Requested" 1 "AC_LowPower_Requested" 0 "AC_Power_NotRequested" ;
VAL_ 578 BattULo_I_Actl 16383 "Fault" ;
VAL_ 560 SelDrvMdeSwtch_D_Stat3 3 "Faulty" 2 "SwitchState2" 1 "SwitchState1" 0 "NotPressed" ;
VAL_ 560 TrnGbox_Rt_Actl 65535 "Fault" 65534 "Unknown" ;
VAL_ 560 TrnShifMde_D_RqDrv 7 "Undefined" 6 "Tow_Haul_Range_Select" 5 "Overdrive_Cancel" 4 "Tow_haul" 3 "Sport_Tip" 2 "Sport" 1 "Range_Select" 0 "Normal" ;
VAL_ 560 TrnSrvcRqd_B_Rq 1 "On" 0 "Off" ;
VAL_ 560 TrnCnvtClu_D_Actl 3 "Transition_or_Micro_Slip" 2 "Lock_Up_Fixed" 1 "Lock_Up_Slip" 0 "No_Lock_Up" ;
VAL_ 560 TrnShifActv_B_Actl 1 "Active" 0 "Inactive" ;
VAL_ 560 RtmTerrMdeChng_D_Rdy 7 "Fault" 6 "Undefined_2" 5 "Undefined_1" 4 "ModeUnavailDrInputRqd" 3 "SpOpModes_NotSupported" 2 "ModeUnavailDynamicCond" 1 "Module_In_Initialization" 0 "Mode_Change_Available" ;
VAL_ 560 RtmTerrMde_D_Actl 7 "Fail_Safe_Default" 6 "Dynamic_Mode" 5 "Rock_Crawl_Mode" 4 "Mud_Ruts_Mode" 3 "Sand_Mode" 2 "Undefined" 1 "Low_Mu_Mode" 0 "Special_Operating_Mode_Off" ;
VAL_ 560 GearLvrPos_D_Actl 15 "Fault" 14 "Unknown_Position" 13 "Undefined_Treat_as__Fault" 12 "Undefined_Treat_as_Fault" 11 "sixth" 10 "fifth" 9 "fourth" 8 "third" 7 "second" 6 "first" 5 "Low" 4 "Sport_DriveSport" 3 "Drive" 2 "Neutral" 1 "Reverse" 0 "Park" ;
VAL_ 560 GboxOil_Te_Actl 255 "Faulty" 254 "NoDataExists" ;
VAL_ 359 PrplWhlRgenMn_Tq_Actl 8191 "Faulty" ;
VAL_ 359 ElPw_D_StatStrtStop 15 "NotUsed6" 14 "NotUsed5" 13 "NotUsed4" 12 "NotUsed3" 11 "NotUsed2" 10 "NotUsed1" 9 "Supported_Level_4" 8 "Supported_Level_3" 7 "Supported_Level_2" 6 "Supported_Level_1" 5 "Limited_Support" 4 "Fault_Limited" 3 "LV_Event_in_Progress" 2 "Not_Supported_Imminent" 1 "Supported_All" 0 "Not_Supported" ;
VAL_ 359 PrplWhlTot2_Tq_Actl 65535 "Fault" 65534 "NoDataExists" ;
VAL_ 359 LscmbbDeny_B_ActlPrpl 1 "Denied" 0 "Allowed" ;
VAL_ 359 LscmbbEngTqMn_B_Actl 1 "Engine_Braking_Activated" 0 "Engine_Braking_Off" ;
VAL_ 359 PwPckTq_D_Stat 3 "PwPckOn_TqAvailable" 2 "StartInPrgrss_TqNotAvail" 1 "PwPckOn_TqNotAvailable" 0 "PwPckOff_TqNotAvailable" ;
VAL_ 359 Eng_D_Stat 3 "NotUsed" 2 "EngAutoStopped" 1 "EngOn" 0 "EngOff" ;
VAL_ 359 ElPw_D_Stat 7 "NotUsed_3" 6 "NotUsed_2" 5 "NotUsed_1" 4 "Fault_Limited" 3 "LV_Event_In_Progress" 2 "Not_Supported_Imminent" 1 "Supported" 0 "Not_Supported" ;
VAL_ 359 TrnAinTq_D_Qf 3 "OK" 2 "Not_Within_Specifications" 1 "No_Data_Exists" 0 "Faulty" ;
VAL_ 359 PlgActvArb_B_Actl 1 "On" 0 "Off" ;
VAL_ 372 TrnAinTqDtrb_B_Actl 1 "Active" 0 "Inactive" ;
VAL_ 357 BPedDrvAppl_D_QF 3 "OK" 2 "Not_Within_Specifications" 1 "No_Data_Exists" 0 "Faulty" ;
VAL_ 357 CmbbDeny_B_ActlPrpl 1 "Yes" 0 "No" ;
VAL_ 357 PrplTqMnSat_B_Actl 1 "Yes" 0 "No" ;
VAL_ 357 VehStrtStop_D_Rq 3 "NotUsed" 2 "Vehicle_Start_Request" 1 "Vehicle_Stop_Request" 0 "NoRequest" ;
VAL_ 357 BpedDrvAppl_D_Actl 3 "_Not_Allowed" 2 "Driver_Braking" 1 "Driver_Not_Braking" 0 "Not_Allowed" ;
VAL_ 357 CmbbEngTqMn_B_Actl 1 "Yes" 0 "No" ;
VAL_ 357 Veh_V_DsplyCcSet 255 "Fault" 254 "Unknown" ;
VAL_ 357 AccEngStat_D_Actl 7 "Undefined_2" 6 "Undefined_1" 5 "ACCSoonCancel_due_Low_Spd" 4 "Shift_Down_Recommendation" 3 "Shift_Up_Recommendation" 2 "ACCNotAllowedToBeActivated" 1 "ACCStandby_due_Auto_Cancel" 0 "Normal_Operation" ;
VAL_ 357 CcMde_D_Actl 7 "TapDownWaiting" 6 "TapUpWaiting" 5 "Resuming_Low" 4 "Resuming_High" 3 "Decelerating" 2 "Accelerating" 1 "Keeping_Speed" 0 "Not_Active" ;
VAL_ 357 CcStat_D_Actl 7 "Undefined_2" 6 "Undefined_1" 5 "Active" 4 "Active_Que_Assist" 3 "Standby" 2 "Standby_Denied" 1 "Denied" 0 "Off" ;
VAL_ 357 CcOvrrdActv_B_Actl 1 "Cruise_Overridden" 0 "Cruise_Req_Not_Overridden" ;
VAL_ 357 AccStopMde_D_Rq 3 "Stop_Mode_Active" 2 "EPBApplyOrBrakeReleaseWarn" 1 "Limit_Rolling_Speed" 0 "Stop_Mode_Not_Active" ;
VAL_ 390 AccBrkPrkEl_B_Rq 1 "Yes" 0 "No" ;
VAL_ 390 Cmbb_B_Enbl 1 "Yes" 0 "No" ;
VAL_ 390 CmbbOvrrd_B_RqDrv 1 "Yes" 0 "No" ;
VAL_ 390 CmbbDeny_B_Actl 1 "Yes" 0 "No" ;
VAL_ 390 CmbbEngTqMn_B_Rq 1 "Yes" 0 "No" ;
VAL_ 390 AccDeny_B_Rq 1 "Yes" 0 "No" ;
VAL_ 390 AccResumEnbl_B_Rq 1 "Yes" 0 "No" ;
VAL_ 390 AccCancl_B_Rq 1 "Yes" 0 "No" ;
VAL_ 390 AccBrkPrchg_B_Rq 1 "Yes" 0 "No" ;
VAL_ 390 AccBrkDecel_B_Rq 1 "Active" 0 "Inactive" ;
VAL_ 390 AccStopStat_B_Rq 1 "Yes" 0 "No" ;
VAL_ 1071 CluPdlPosPcMeas_D_Qf 3 "OK" 2 "Not_Within_Specifications" 1 "No_Data_Exists" 0 "Faulty" ;
VAL_ 1071 EngMnfld3_P_Actl 255 "Faulty" 254 "NoDataExists" ;
VAL_ 1072 HdcOn_B_Rq_UB 1 "Fresh_data" 0 "Unchanged_data" ;
VAL_ 1072 TrlrAidCancl_B_Rq_UB 1 "Fresh_data" 0 "Unchanged_data" ;
VAL_ 1072 TrlrAidCancl_B_Rq 1 "Cancel" 0 "Null" ;
VAL_ 1072 HdcOn_B_Rq 1 "On" 0 "Off" ;
VAL_ 1072 HsaMde_D_Rq 3 "Undefined" 2 "Manual" 1 "Automatic" 0 "Off" ;
VAL_ 1072 HsaMde_D_Rq_UB 1 "Fresh_data" 0 "Unchanged_data" ;
VAL_ 1072 LscmbbStat_B_Actl 1 "On" 0 "Off" ;
VAL_ 1072 LscmbbStat_B_Actl_UB 1 "Fresh_data" 0 "Unchanged_data" ;
VAL_ 1072 Outside_Air_Temp_Stat_UB 1 "Fresh_data" 0 "Unchanged_data" ;
VAL_ 1072 Outside_Air_Temp_Stat 255 "Invalid" 254 "Unknown" ;
VAL_ 1072 BulbChkActv_B_Stat_UB 1 "Fresh_data" 0 "Unchanged_data" ;
VAL_ 1072 BulbChkActv_B_Stat 1 "Active" 0 "Inactive" ;
VAL_ 1072 Fda_B_Stat_UB 1 "Fresh_data" 0 "Unchanged_data" ;
VAL_ 1072 AccEnbl_B_RqDrv_UB 1 "Fresh_data" 0 "Unchanged_data" ;
VAL_ 1072 AccDeny_B_RqIpc_UB 1 "Fresh_data" 0 "Unchanged_data" ;
VAL_ 1072 OdometerMasterValue_UB 1 "Fresh_data" 0 "Unchanged_data" ;
VAL_ 1072 OdometerMasterValue 16777215 "Invalid" ;
VAL_ 1072 Fda_B_Stat 1 "On" 0 "Off" ;
VAL_ 1072 AccDeny_B_RqIpc 1 "Yes" 0 "No" ;
VAL_ 1072 AccEnbl_B_RqDrv 1 "Adaptive_Cruise" 0 "Normal_Cruise" ;
VAL_ 1072 DrvSlipCtlMde_D_Rq_UB 1 "Fresh_data" 0 "Unchanged_data" ;
VAL_ 1072 DrvSlipCtlMde_D_Rq 3 "App_Specific_Off_Mode_3" 2 "App_Specific_Off_Mode_2" 1 "App_Specific_Off_Mode_1" 0 "Default_Mode" ;
VAL_ 1072 DrvSlipCtlMde_B_Rq_UB 1 "Fresh_data" 0 "Unchanged_data" ;
VAL_ 1072 DrvSlipCtlMde_B_Rq 1 "Pressed" 0 "Not_Pressed" ;
VAL_ 1072 ePRNDL_MODE_UB 1 "Fresh_data" 0 "Unchanged_data" ;
VAL_ 1072 ePRNDL_MODE 1 "On" 0 "Off" ;
VAL_ 1072 TrlrBrkMde_D_Rq 1 "ElectricOverHydraulic" 0 "Electric" ;
VAL_ 1072 TRLR_SWAY_CONFIG_CMD 1 "On" 0 "Off" ;
VAL_ 1072 TRAILER_BRAKE_CONFIG 1 "Yes" 0 "No" ;
VAL_ 1072 TrlrBrkMde_D_Rq_UB 1 "Fresh_data" 0 "Unchanged_data" ;
VAL_ 1072 TRLR_SWAY_CONFIG_CMD_UB 1 "Fresh_data" 0 "Unchanged_data" ;
VAL_ 1072 TRAILER_BRAKE_CONFIG_UB 1 "Fresh_data" 0 "Unchanged_data" ;
VAL_ 1058 TqmTerrMdeChng_D_Rdy_UB 1 "Fresh_data" 0 "Unchanged_data" ;
VAL_ 1058 TqmTerrMde_D_Actl_UB 1 "Fresh_data" 0 "Unchanged_data" ;
VAL_ 1058 TqmTerrMdeChng_D_Rdy 7 "Fault" 6 "Undefined_2" 5 "Undefined_1" 4 "ModeUnavailDrInputRqd" 3 "SpOpModes_NotSupported" 2 "ModeUnavailDynamicCond" 1 "Module_In_Initialization" 0 "Mode_Change_Available" ;
VAL_ 1058 TqmTerrMde_D_Actl 7 "Fail_Safe_Default" 6 "Dynamic_Mode" 5 "Rock_Crawl_Mode" 4 "Mud_Ruts_Mode" 3 "Sand_Mode" 2 "Undefined" 1 "Low_Mu_Mode" 0 "Special_Operating_Mode_Off" ;
VAL_ 1058 BattTracWarnLamp_B_Rq_UB 1 "Fresh_data" 0 "Unchanged_data" ;
VAL_ 1058 BattTracWarnLamp_B_Rq 1 "On" 0 "Off" ;
VAL_ 1058 BattTracSrvcRqd_B_Rq_UB 1 "Fresh_data" 0 "Unchanged_data" ;
VAL_ 1058 BattTracSrvcRqd_B_Rq 1 "On" 0 "Off" ;
VAL_ 1058 SeatBlLoPsgr_Pc_Actl_UB 1 "Fresh_data" 0 "Unchanged_data" ;
VAL_ 1058 SeatBlLoPsgr_Pc_Actl 127 "Null" ;
VAL_ 1058 WndwFrontHeat_B_Stat_UB 1 "Fresh_data" 0 "Unchanged_data" ;
VAL_ 1058 WndwFrontHeat_B_Stat 1 "On" 0 "Off" ;
VAL_ 1058 HILL_DESC_SW_UB 1 "Fresh_data" 0 "Unchanged_data" ;
VAL_ 1058 HILL_DESC_SW 1 "On" 0 "Off" ;
VAL_ 1058 EngClntTe_D_Qf 3 "OK" 2 "Not_Within_Specifications" 1 "No_Data_Exists" 0 "Faulty" ;
VAL_ 1058 EngClnt_Te_Actl_UB 1 "Fresh_data" 0 "Unchanged_data" ;
VAL_ 1058 TrnTotTq_Rt_Est_UB 1 "Fresh_data" 0 "Unchanged_data" ;
VAL_ 1058 TrnTotLss_Tq_Est_UB 1 "Fresh_data" 0 "Unchanged_data" ;
VAL_ 1058 TrnTotTq_Rt_Est 65535 "Fault" 65534 "Unknown" ;
VAL_ 1058 TrnTotLss_Tq_Est 255 "Fault" 254 "Unknown" ;
VAL_ 1058 DrvSlipCtlMde_B_Rq2_UB 1 "Fresh_data" 0 "Unchanged_data" ;
VAL_ 1058 DrvSlipCtlMde_B_Rq2 1 "Pressed" 0 "Not_Pressed" ;
